VERSION "HNPBNNNYNNNNNNNNNNNNNNNNNNNNNNNNYNYYYYYYYY>4>%%%/4>'%**4YYY///"

NS_ :

BS_:

BU_: RDF2 Air Vehicle_CAN MPC2

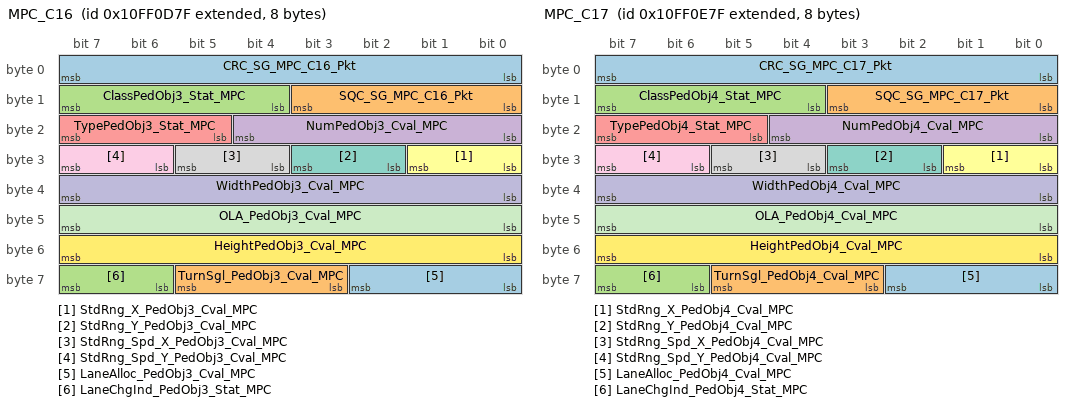
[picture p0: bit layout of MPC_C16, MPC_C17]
BO_ 2432634239 MPC_C16: 8 MPC2
 SG_ CRC_SG_MPC_C16_Pkt : 0|8@1+ (1,0) [0|255] "NoUnit" Vector__XXX
 SG_ SQC_SG_MPC_C16_Pkt : 8|4@1+ (1,0) [0|15] "NoUnit" Vector__XXX
 SG_ ClassPedObj3_Stat_MPC : 12|4@1+ (1,0) [0|15] "" Vector__XXX
 SG_ NumPedObj3_Cval_MPC : 16|5@1+ (1,0) [0|30] "NoUnit" Vector__XXX
 SG_ TypePedObj3_Stat_MPC : 21|3@1+ (1,0) [0|7] "" Vector__XXX
 SG_ StdRng_X_PedObj3_Cval_MPC : 24|2@1+ (1,0) [0|3] "" Vector__XXX
 SG_ StdRng_Y_PedObj3_Cval_MPC : 26|2@1+ (1,0) [0|3] "" Vector__XXX
 SG_ StdRng_Spd_X_PedObj3_Cval_MPC : 28|2@1+ (1,0) [0|3] "" Vector__XXX
 SG_ StdRng_Spd_Y_PedObj3_Cval_MPC : 30|2@1+ (1,0) [0|3] "" Vector__XXX
 SG_ WidthPedObj3_Cval_MPC : 32|8@1+ (0.05,0) [0|12.5] "m" Vector__XXX
 SG_ OLA_PedObj3_Cval_MPC : 40|8@1+ (0.004,-0.5) [-0.5|0.5] "rad" Vector__XXX
 SG_ HeightPedObj3_Cval_MPC : 48|8@1+ (0.05,0) [0|12.5] "m" Vector__XXX
 SG_ LaneAlloc_PedObj3_Cval_MPC : 56|3@1+ (1,0) [0|7] "" Vector__XXX
 SG_ TurnSgl_PedObj3_Cval_MPC : 59|3@1+ (1,0) [0|7] "" Vector__XXX
 SG_ LaneChgInd_PedObj3_Stat_MPC : 62|2@1+ (1,0) [0|3] "" Vector__XXX

BO_ 2432634495 MPC_C17: 8 MPC2
 SG_ CRC_SG_MPC_C17_Pkt : 0|8@1+ (1,0) [0|255] "NoUnit" Vector__XXX
 SG_ SQC_SG_MPC_C17_Pkt : 8|4@1+ (1,0) [0|15] "NoUnit" Vector__XXX
 SG_ ClassPedObj4_Stat_MPC : 12|4@1+ (1,0) [0|15] "" Vector__XXX
 SG_ NumPedObj4_Cval_MPC : 16|5@1+ (1,0) [0|30] "NoUnit" Vector__XXX
 SG_ TypePedObj4_Stat_MPC : 21|3@1+ (1,0) [0|7] "" Vector__XXX
 SG_ StdRng_X_PedObj4_Cval_MPC : 24|2@1+ (1,0) [0|3] "" Vector__XXX
 SG_ StdRng_Y_PedObj4_Cval_MPC : 26|2@1+ (1,0) [0|3] "" Vector__XXX
 SG_ StdRng_Spd_X_PedObj4_Cval_MPC : 28|2@1+ (1,0) [0|3] "" Vector__XXX
 SG_ StdRng_Spd_Y_PedObj4_Cval_MPC : 30|2@1+ (1,0) [0|3] "" Vector__XXX
 SG_ WidthPedObj4_Cval_MPC : 32|8@1+ (0.05,0) [0|12.5] "m" Vector__XXX
 SG_ OLA_PedObj4_Cval_MPC : 40|8@1+ (0.004,-0.5) [-0.5|0.5] "rad" Vector__XXX
 SG_ HeightPedObj4_Cval_MPC : 48|8@1+ (0.05,0) [0|12.5] "m" Vector__XXX
 SG_ LaneAlloc_PedObj4_Cval_MPC : 56|3@1+ (1,0) [0|7] "" Vector__XXX
 SG_ TurnSgl_PedObj4_Cval_MPC : 59|3@1+ (1,0) [0|7] "" Vector__XXX
 SG_ LaneChgInd_PedObj4_Stat_MPC : 62|2@1+ (1,0) [0|3] "" Vector__XXX

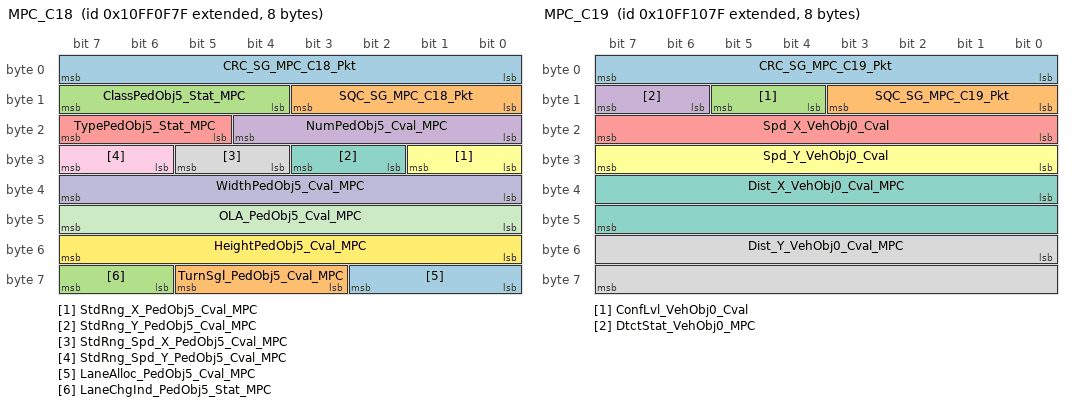
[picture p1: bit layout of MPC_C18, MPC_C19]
BO_ 2432634751 MPC_C18: 8 MPC2
 SG_ CRC_SG_MPC_C18_Pkt : 0|8@1+ (1,0) [0|255] "NoUnit" Vector__XXX
 SG_ SQC_SG_MPC_C18_Pkt : 8|4@1+ (1,0) [0|15] "NoUnit" Vector__XXX
 SG_ ClassPedObj5_Stat_MPC : 12|4@1+ (1,0) [0|15] "" Vector__XXX
 SG_ NumPedObj5_Cval_MPC : 16|5@1+ (1,0) [0|30] "NoUnit" Vector__XXX
 SG_ TypePedObj5_Stat_MPC : 21|3@1+ (1,0) [0|7] "" Vector__XXX
 SG_ StdRng_X_PedObj5_Cval_MPC : 24|2@1+ (1,0) [0|3] "" Vector__XXX
 SG_ StdRng_Y_PedObj5_Cval_MPC : 26|2@1+ (1,0) [0|3] "" Vector__XXX
 SG_ StdRng_Spd_X_PedObj5_Cval_MPC : 28|2@1+ (1,0) [0|3] "" Vector__XXX
 SG_ StdRng_Spd_Y_PedObj5_Cval_MPC : 30|2@1+ (1,0) [0|3] "" Vector__XXX
 SG_ WidthPedObj5_Cval_MPC : 32|8@1+ (0.05,0) [0|12.5] "m" Vector__XXX
 SG_ OLA_PedObj5_Cval_MPC : 40|8@1+ (0.004,-0.5) [-0.5|0.5] "rad" Vector__XXX
 SG_ HeightPedObj5_Cval_MPC : 48|8@1+ (0.05,0) [0|12.5] "m" Vector__XXX
 SG_ LaneAlloc_PedObj5_Cval_MPC : 56|3@1+ (1,0) [0|7] "" Vector__XXX
 SG_ TurnSgl_PedObj5_Cval_MPC : 59|3@1+ (1,0) [0|7] "" Vector__XXX
 SG_ LaneChgInd_PedObj5_Stat_MPC : 62|2@1+ (1,0) [0|3] "" Vector__XXX

BO_ 2432635007 MPC_C19: 8 MPC2
 SG_ CRC_SG_MPC_C19_Pkt : 0|8@1+ (1,0) [0|255] "NoUnit" Vector__XXX
 SG_ SQC_SG_MPC_C19_Pkt : 8|4@1+ (1,0) [0|15] "NoUnit" Vector__XXX
 SG_ ConfLvl_VehObj0_Cval : 12|2@1+ (1,0) [0|3] "" Vector__XXX
 SG_ DtctStat_VehObj0_MPC : 14|2@1+ (1,0) [0|3] "" Vector__XXX
 SG_ Spd_X_VehObj0_Cval : 16|8@1+ (1,-200) [-200|50] "km/h" Vector__XXX
 SG_ Spd_Y_VehObj0_Cval : 24|8@1+ (0.1,-12.5) [-12.5|12.5] "m/s" Vector__XXX
 SG_ Dist_X_VehObj0_Cval_MPC : 32|16@1+ (0.0078125,-250.99609375) [-250.99609375|250.99609375] "m" Vector__XXX
 SG_ Dist_Y_VehObj0_Cval_MPC : 48|16@1+ (0.0078125,-250.99609375) [-250.99609375|250.99609375] "m" Vector__XXX

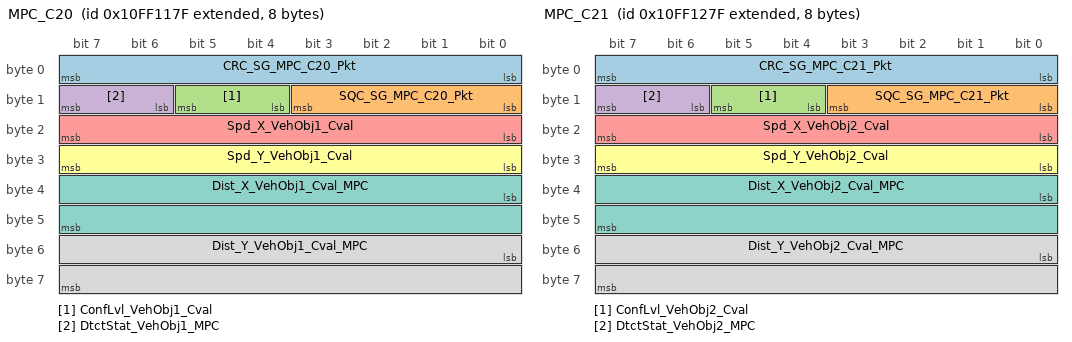
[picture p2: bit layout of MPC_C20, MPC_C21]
BO_ 2432635263 MPC_C20: 8 MPC2
 SG_ CRC_SG_MPC_C20_Pkt : 0|8@1+ (1,0) [0|255] "NoUnit" Vector__XXX
 SG_ SQC_SG_MPC_C20_Pkt : 8|4@1+ (1,0) [0|15] "NoUnit" Vector__XXX
 SG_ ConfLvl_VehObj1_Cval : 12|2@1+ (1,0) [0|3] "" Vector__XXX
 SG_ DtctStat_VehObj1_MPC : 14|2@1+ (1,0) [0|3] "" Vector__XXX
 SG_ Spd_X_VehObj1_Cval : 16|8@1+ (1,-200) [-200|50] "km/h" Vector__XXX
 SG_ Spd_Y_VehObj1_Cval : 24|8@1+ (0.1,-12.5) [-12.5|12.5] "m/s" Vector__XXX
 SG_ Dist_X_VehObj1_Cval_MPC : 32|16@1+ (0.0078125,-250.99609375) [-250.99609375|250.99609375] "m" Vector__XXX
 SG_ Dist_Y_VehObj1_Cval_MPC : 48|16@1+ (0.0078125,-250.99609375) [-250.99609375|250.99609375] "m" Vector__XXX

BO_ 2432635519 MPC_C21: 8 MPC2
 SG_ CRC_SG_MPC_C21_Pkt : 0|8@1+ (1,0) [0|255] "NoUnit" Vector__XXX
 SG_ SQC_SG_MPC_C21_Pkt : 8|4@1+ (1,0) [0|15] "NoUnit" Vector__XXX
 SG_ ConfLvl_VehObj2_Cval : 12|2@1+ (1,0) [0|3] "" Vector__XXX
 SG_ DtctStat_VehObj2_MPC : 14|2@1+ (1,0) [0|3] "" Vector__XXX
 SG_ Spd_X_VehObj2_Cval : 16|8@1+ (1,-200) [-200|50] "km/h" Vector__XXX
 SG_ Spd_Y_VehObj2_Cval : 24|8@1+ (0.1,-12.5) [-12.5|12.5] "m/s" Vector__XXX
 SG_ Dist_X_VehObj2_Cval_MPC : 32|16@1+ (0.0078125,-250.99609375) [-250.99609375|250.99609375] "m" Vector__XXX
 SG_ Dist_Y_VehObj2_Cval_MPC : 48|16@1+ (0.0078125,-250.99609375) [-250.99609375|250.99609375] "m" Vector__XXX

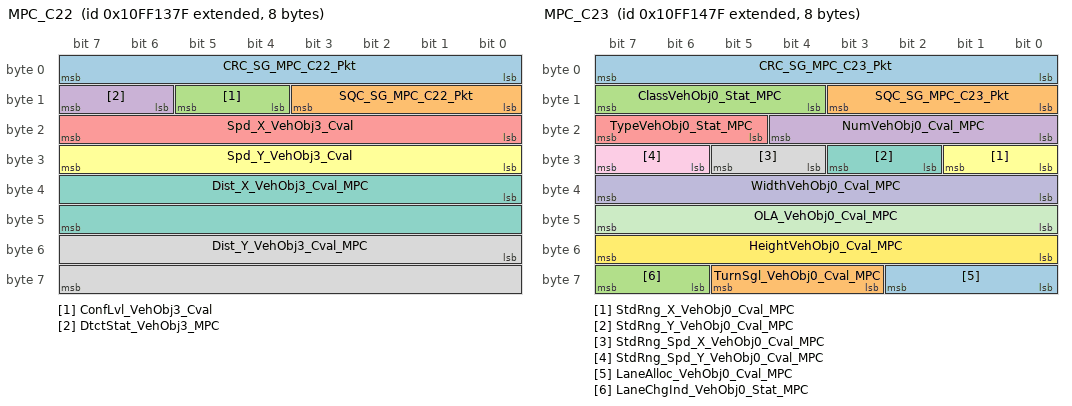
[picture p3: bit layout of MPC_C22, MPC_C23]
BO_ 2432635775 MPC_C22: 8 MPC2
 SG_ CRC_SG_MPC_C22_Pkt : 0|8@1+ (1,0) [0|255] "NoUnit" Vector__XXX
 SG_ SQC_SG_MPC_C22_Pkt : 8|4@1+ (1,0) [0|15] "NoUnit" Vector__XXX
 SG_ ConfLvl_VehObj3_Cval : 12|2@1+ (1,0) [0|3] "" Vector__XXX
 SG_ DtctStat_VehObj3_MPC : 14|2@1+ (1,0) [0|3] "" Vector__XXX
 SG_ Spd_X_VehObj3_Cval : 16|8@1+ (1,-200) [-200|50] "km/h" Vector__XXX
 SG_ Spd_Y_VehObj3_Cval : 24|8@1+ (0.1,-12.5) [-12.5|12.5] "m/s" Vector__XXX
 SG_ Dist_X_VehObj3_Cval_MPC : 32|16@1+ (0.0078125,-250.99609375) [-250.99609375|250.99609375] "m" Vector__XXX
 SG_ Dist_Y_VehObj3_Cval_MPC : 48|16@1+ (0.0078125,-250.99609375) [-250.99609375|250.99609375] "m" Vector__XXX

BO_ 2432636031 MPC_C23: 8 MPC2
 SG_ CRC_SG_MPC_C23_Pkt : 0|8@1+ (1,0) [0|255] "NoUnit" Vector__XXX
 SG_ SQC_SG_MPC_C23_Pkt : 8|4@1+ (1,0) [0|15] "NoUnit" Vector__XXX
 SG_ ClassVehObj0_Stat_MPC : 12|4@1+ (1,0) [0|15] "" Vector__XXX
 SG_ NumVehObj0_Cval_MPC : 16|5@1+ (1,0) [0|30] "NoUnit" Vector__XXX
 SG_ TypeVehObj0_Stat_MPC : 21|3@1+ (1,0) [0|7] "" Vector__XXX
 SG_ StdRng_X_VehObj0_Cval_MPC : 24|2@1+ (1,0) [0|3] "" Vector__XXX
 SG_ StdRng_Y_VehObj0_Cval_MPC : 26|2@1+ (1,0) [0|3] "" Vector__XXX
 SG_ StdRng_Spd_X_VehObj0_Cval_MPC : 28|2@1+ (1,0) [0|3] "" Vector__XXX
 SG_ StdRng_Spd_Y_VehObj0_Cval_MPC : 30|2@1+ (1,0) [0|3] "" Vector__XXX
 SG_ WidthVehObj0_Cval_MPC : 32|8@1+ (0.05,0) [0|12.5] "m" Vector__XXX
 SG_ OLA_VehObj0_Cval_MPC : 40|8@1+ (0.004,-0.5) [-0.5|0.5] "rad" Vector__XXX
 SG_ HeightVehObj0_Cval_MPC : 48|8@1+ (0.05,0) [0|12.5] "m" Vector__XXX
 SG_ LaneAlloc_VehObj0_Cval_MPC : 56|3@1+ (1,0) [0|7] "" Vector__XXX
 SG_ TurnSgl_VehObj0_Cval_MPC : 59|3@1+ (1,0) [0|7] "" Vector__XXX
 SG_ LaneChgInd_VehObj0_Stat_MPC : 62|2@1+ (1,0) [0|3] "" Vector__XXX

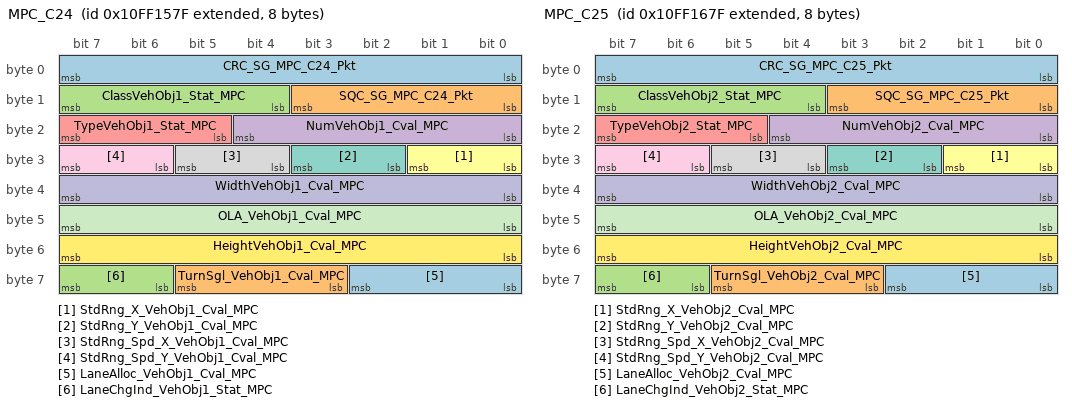
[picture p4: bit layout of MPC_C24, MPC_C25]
BO_ 2432636287 MPC_C24: 8 MPC2
 SG_ CRC_SG_MPC_C24_Pkt : 0|8@1+ (1,0) [0|255] "NoUnit" Vector__XXX
 SG_ SQC_SG_MPC_C24_Pkt : 8|4@1+ (1,0) [0|15] "NoUnit" Vector__XXX
 SG_ ClassVehObj1_Stat_MPC : 12|4@1+ (1,0) [0|15] "" Vector__XXX
 SG_ NumVehObj1_Cval_MPC : 16|5@1+ (1,0) [0|30] "NoUnit" Vector__XXX
 SG_ TypeVehObj1_Stat_MPC : 21|3@1+ (1,0) [0|7] "" Vector__XXX
 SG_ StdRng_X_VehObj1_Cval_MPC : 24|2@1+ (1,0) [0|3] "" Vector__XXX
 SG_ StdRng_Y_VehObj1_Cval_MPC : 26|2@1+ (1,0) [0|3] "" Vector__XXX
 SG_ StdRng_Spd_X_VehObj1_Cval_MPC : 28|2@1+ (1,0) [0|3] "" Vector__XXX
 SG_ StdRng_Spd_Y_VehObj1_Cval_MPC : 30|2@1+ (1,0) [0|3] "" Vector__XXX
 SG_ WidthVehObj1_Cval_MPC : 32|8@1+ (0.05,0) [0|12.5] "m" Vector__XXX
 SG_ OLA_VehObj1_Cval_MPC : 40|8@1+ (0.004,-0.5) [-0.5|0.5] "rad" Vector__XXX
 SG_ HeightVehObj1_Cval_MPC : 48|8@1+ (0.05,0) [0|12.5] "m" Vector__XXX
 SG_ LaneAlloc_VehObj1_Cval_MPC : 56|3@1+ (1,0) [0|7] "" Vector__XXX
 SG_ TurnSgl_VehObj1_Cval_MPC : 59|3@1+ (1,0) [0|7] "" Vector__XXX
 SG_ LaneChgInd_VehObj1_Stat_MPC : 62|2@1+ (1,0) [0|3] "" Vector__XXX

BO_ 2432636543 MPC_C25: 8 MPC2
 SG_ CRC_SG_MPC_C25_Pkt : 0|8@1+ (1,0) [0|255] "NoUnit" Vector__XXX
 SG_ SQC_SG_MPC_C25_Pkt : 8|4@1+ (1,0) [0|15] "NoUnit" Vector__XXX
 SG_ ClassVehObj2_Stat_MPC : 12|4@1+ (1,0) [0|15] "" Vector__XXX
 SG_ NumVehObj2_Cval_MPC : 16|5@1+ (1,0) [0|30] "NoUnit" Vector__XXX
 SG_ TypeVehObj2_Stat_MPC : 21|3@1+ (1,0) [0|7] "" Vector__XXX
 SG_ StdRng_X_VehObj2_Cval_MPC : 24|2@1+ (1,0) [0|3] "" Vector__XXX
 SG_ StdRng_Y_VehObj2_Cval_MPC : 26|2@1+ (1,0) [0|3] "" Vector__XXX
 SG_ StdRng_Spd_X_VehObj2_Cval_MPC : 28|2@1+ (1,0) [0|3] "" Vector__XXX
 SG_ StdRng_Spd_Y_VehObj2_Cval_MPC : 30|2@1+ (1,0) [0|3] "" Vector__XXX
 SG_ WidthVehObj2_Cval_MPC : 32|8@1+ (0.05,0) [0|12.5] "m" Vector__XXX
 SG_ OLA_VehObj2_Cval_MPC : 40|8@1+ (0.004,-0.5) [-0.5|0.5] "rad" Vector__XXX
 SG_ HeightVehObj2_Cval_MPC : 48|8@1+ (0.05,0) [0|12.5] "m" Vector__XXX
 SG_ LaneAlloc_VehObj2_Cval_MPC : 56|3@1+ (1,0) [0|7] "" Vector__XXX
 SG_ TurnSgl_VehObj2_Cval_MPC : 59|3@1+ (1,0) [0|7] "" Vector__XXX
 SG_ LaneChgInd_VehObj2_Stat_MPC : 62|2@1+ (1,0) [0|3] "" Vector__XXX

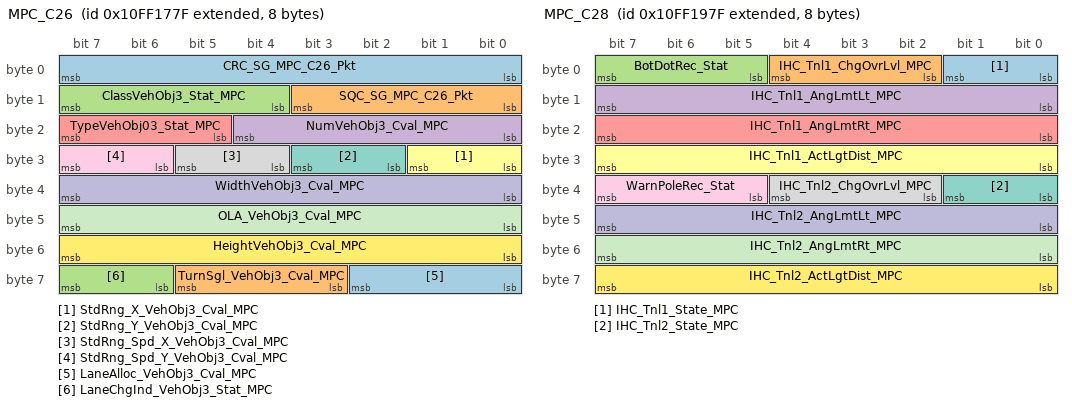
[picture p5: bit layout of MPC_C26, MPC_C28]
BO_ 2432636799 MPC_C26: 8 MPC2
 SG_ CRC_SG_MPC_C26_Pkt : 0|8@1+ (1,0) [0|255] "NoUnit" Vector__XXX
 SG_ SQC_SG_MPC_C26_Pkt : 8|4@1+ (1,0) [0|15] "NoUnit" Vector__XXX
 SG_ ClassVehObj3_Stat_MPC : 12|4@1+ (1,0) [0|15] "" Vector__XXX
 SG_ NumVehObj3_Cval_MPC : 16|5@1+ (1,0) [0|30] "NoUnit" Vector__XXX
 SG_ TypeVehObj03_Stat_MPC : 21|3@1+ (1,0) [0|7] "" Vector__XXX
 SG_ StdRng_X_VehObj3_Cval_MPC : 24|2@1+ (1,0) [0|3] "" Vector__XXX
 SG_ StdRng_Y_VehObj3_Cval_MPC : 26|2@1+ (1,0) [0|3] "" Vector__XXX
 SG_ StdRng_Spd_X_VehObj3_Cval_MPC : 28|2@1+ (1,0) [0|3] "" Vector__XXX
 SG_ StdRng_Spd_Y_VehObj3_Cval_MPC : 30|2@1+ (1,0) [0|3] "" Vector__XXX
 SG_ WidthVehObj3_Cval_MPC : 32|8@1+ (0.05,0) [0|12.5] "m" Vector__XXX
 SG_ OLA_VehObj3_Cval_MPC : 40|8@1+ (0.004,-0.5) [-0.5|0.5] "rad" Vector__XXX
 SG_ HeightVehObj3_Cval_MPC : 48|8@1+ (0.05,0) [0|12.5] "m" Vector__XXX
 SG_ LaneAlloc_VehObj3_Cval_MPC : 56|3@1+ (1,0) [0|7] "" Vector__XXX
 SG_ TurnSgl_VehObj3_Cval_MPC : 59|3@1+ (1,0) [0|7] "" Vector__XXX
 SG_ LaneChgInd_VehObj3_Stat_MPC : 62|2@1+ (1,0) [0|3] "" Vector__XXX

BO_ 2432637311 MPC_C28: 8 MPC2
 SG_ IHC_Tnl1_State_MPC : 0|2@1+ (1,0) [0|3] "" Vector__XXX
 SG_ IHC_Tnl1_ChgOvrLvl_MPC : 2|3@1+ (1,0) [0|6] "NoUnit" Vector__XXX
 SG_ BotDotRec_Stat : 5|3@1+ (1,0) [0|7] "" Vector__XXX
 SG_ IHC_Tnl1_AngLmtLt_MPC : 8|8@1+ (0.25,-31.25) [-31.25|31.25] "°" Vector__XXX
 SG_ IHC_Tnl1_AngLmtRt_MPC : 16|8@1+ (0.25,-31.25) [-31.25|31.25] "°" Vector__XXX
 SG_ IHC_Tnl1_ActLgtDist_MPC : 24|8@1+ (2.5,0) [0|625] "m" Vector__XXX
 SG_ IHC_Tnl2_State_MPC : 32|2@1+ (1,0) [0|3] "" Vector__XXX
 SG_ IHC_Tnl2_ChgOvrLvl_MPC : 34|3@1+ (1,0) [0|6] "NoUnit" Vector__XXX
 SG_ WarnPoleRec_Stat : 37|3@1+ (1,0) [0|7] "" Vector__XXX
 SG_ IHC_Tnl2_AngLmtLt_MPC : 40|8@1+ (0.25,-31.25) [-31.25|31.25] "°" Vector__XXX
 SG_ IHC_Tnl2_AngLmtRt_MPC : 48|8@1+ (0.25,-31.25) [-31.25|31.25] "°" Vector__XXX
 SG_ IHC_Tnl2_ActLgtDist_MPC : 56|8@1+ (2.5,0) [0|625] "m" Vector__XXX

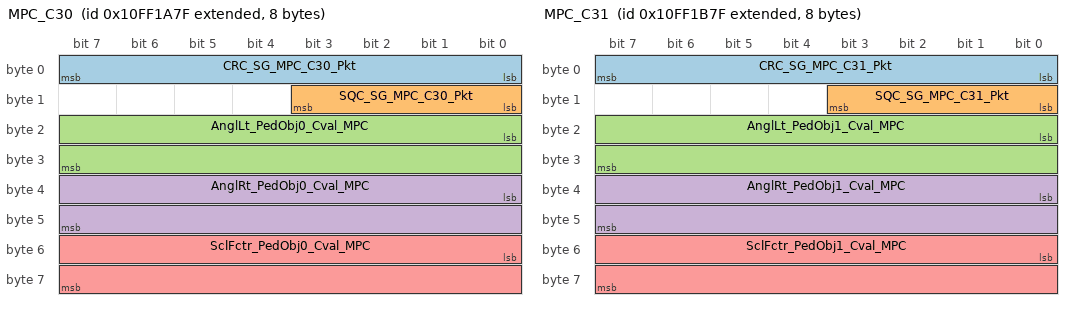
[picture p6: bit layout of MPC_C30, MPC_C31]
BO_ 2432637567 MPC_C30: 8 MPC2
 SG_ CRC_SG_MPC_C30_Pkt : 0|8@1+ (1,0) [0|255] "NoUnit" Vector__XXX
 SG_ SQC_SG_MPC_C30_Pkt : 8|4@1+ (1,0) [0|15] "NoUnit" Vector__XXX
 SG_ AnglLt_PedObj0_Cval_MPC : 16|16@1+ (0.00390625,-125) [-125|125] "°" Vector__XXX
 SG_ AnglRt_PedObj0_Cval_MPC : 32|16@1+ (0.00390625,-125) [-125|125] "°" Vector__XXX
 SG_ SclFctr_PedObj0_Cval_MPC : 48|16@1+ (6.25E-005,0.5) [0.5|4.5] "NoUnit" Vector__XXX

BO_ 2432637823 MPC_C31: 8 MPC2
 SG_ CRC_SG_MPC_C31_Pkt : 0|8@1+ (1,0) [0|255] "NoUnit" Vector__XXX
 SG_ SQC_SG_MPC_C31_Pkt : 8|4@1+ (1,0) [0|15] "NoUnit" Vector__XXX
 SG_ AnglLt_PedObj1_Cval_MPC : 16|16@1+ (0.00390625,-125) [-125|125] "°" Vector__XXX
 SG_ AnglRt_PedObj1_Cval_MPC : 32|16@1+ (0.00390625,-125) [-125|125] "°" Vector__XXX
 SG_ SclFctr_PedObj1_Cval_MPC : 48|16@1+ (6.25E-005,0.5) [0.5|4.5] "NoUnit" Vector__XXX

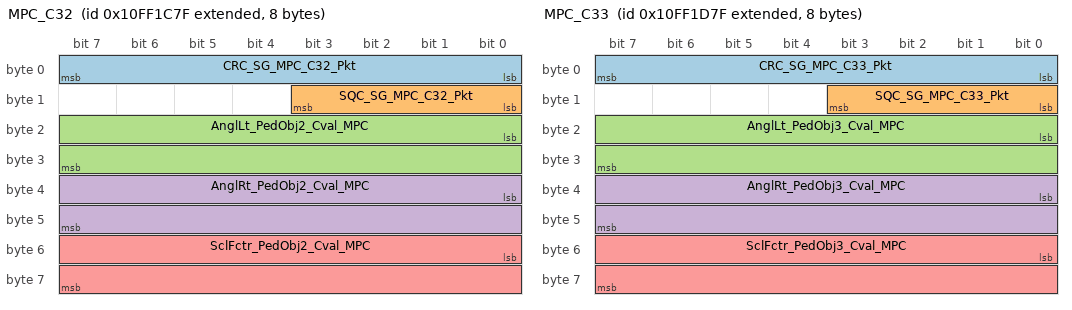
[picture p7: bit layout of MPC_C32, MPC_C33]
BO_ 2432638079 MPC_C32: 8 MPC2
 SG_ CRC_SG_MPC_C32_Pkt : 0|8@1+ (1,0) [0|255] "NoUnit" Vector__XXX
 SG_ SQC_SG_MPC_C32_Pkt : 8|4@1+ (1,0) [0|15] "NoUnit" Vector__XXX
 SG_ AnglLt_PedObj2_Cval_MPC : 16|16@1+ (0.00390625,-125) [-125|125] "°" Vector__XXX
 SG_ AnglRt_PedObj2_Cval_MPC : 32|16@1+ (0.00390625,-125) [-125|125] "°" Vector__XXX
 SG_ SclFctr_PedObj2_Cval_MPC : 48|16@1+ (6.25E-005,0.5) [0.5|4.5] "NoUnit" Vector__XXX

BO_ 2432638335 MPC_C33: 8 MPC2
 SG_ CRC_SG_MPC_C33_Pkt : 0|8@1+ (1,0) [0|255] "NoUnit" Vector__XXX
 SG_ SQC_SG_MPC_C33_Pkt : 8|4@1+ (1,0) [0|15] "NoUnit" Vector__XXX
 SG_ AnglLt_PedObj3_Cval_MPC : 16|16@1+ (0.00390625,-125) [-125|125] "°" Vector__XXX
 SG_ AnglRt_PedObj3_Cval_MPC : 32|16@1+ (0.00390625,-125) [-125|125] "°" Vector__XXX
 SG_ SclFctr_PedObj3_Cval_MPC : 48|16@1+ (6.25E-005,0.5) [0.5|4.5] "NoUnit" Vector__XXX

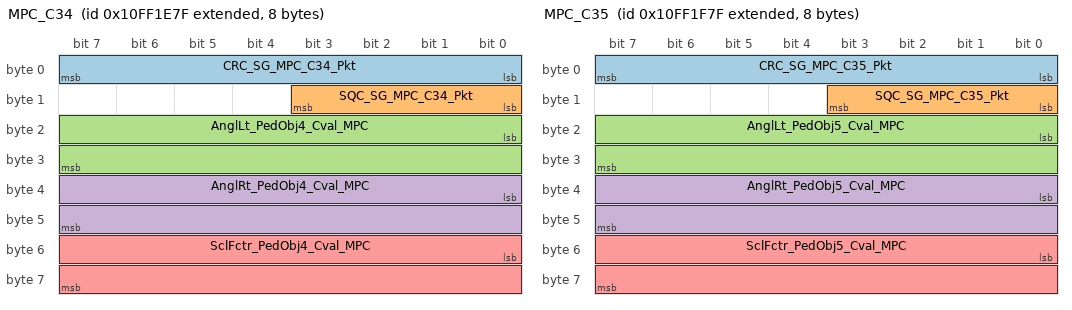
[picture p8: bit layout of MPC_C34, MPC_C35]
BO_ 2432638591 MPC_C34: 8 MPC2
 SG_ CRC_SG_MPC_C34_Pkt : 0|8@1+ (1,0) [0|255] "NoUnit" Vector__XXX
 SG_ SQC_SG_MPC_C34_Pkt : 8|4@1+ (1,0) [0|15] "NoUnit" Vector__XXX
 SG_ AnglLt_PedObj4_Cval_MPC : 16|16@1+ (0.00390625,-125) [-125|125] "°" Vector__XXX
 SG_ AnglRt_PedObj4_Cval_MPC : 32|16@1+ (0.00390625,-125) [-125|125] "°" Vector__XXX
 SG_ SclFctr_PedObj4_Cval_MPC : 48|16@1+ (6.25E-005,0.5) [0.5|4.5] "NoUnit" Vector__XXX

BO_ 2432638847 MPC_C35: 8 MPC2
 SG_ CRC_SG_MPC_C35_Pkt : 0|8@1+ (1,0) [0|255] "NoUnit" Vector__XXX
 SG_ SQC_SG_MPC_C35_Pkt : 8|4@1+ (1,0) [0|15] "NoUnit" Vector__XXX
 SG_ AnglLt_PedObj5_Cval_MPC : 16|16@1+ (0.00390625,-125) [-125|125] "°" Vector__XXX
 SG_ AnglRt_PedObj5_Cval_MPC : 32|16@1+ (0.00390625,-125) [-125|125] "°" Vector__XXX
 SG_ SclFctr_PedObj5_Cval_MPC : 48|16@1+ (6.25E-005,0.5) [0.5|4.5] "NoUnit" Vector__XXX

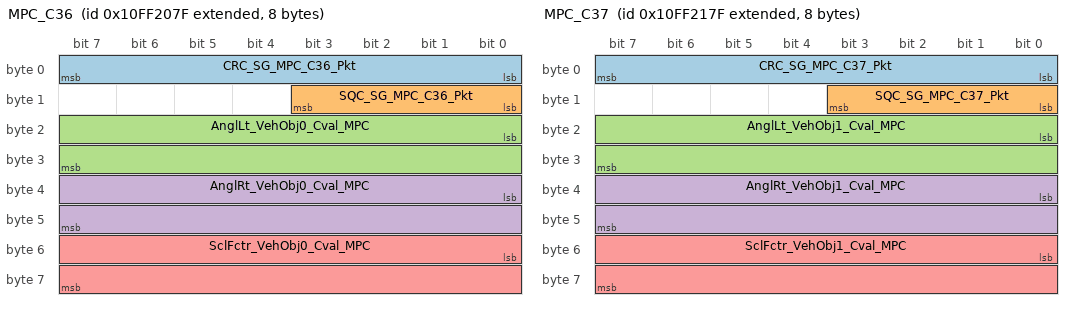
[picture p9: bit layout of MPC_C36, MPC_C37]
BO_ 2432639103 MPC_C36: 8 MPC2
 SG_ CRC_SG_MPC_C36_Pkt : 0|8@1+ (1,0) [0|255] "NoUnit" Vector__XXX
 SG_ SQC_SG_MPC_C36_Pkt : 8|4@1+ (1,0) [0|15] "NoUnit" Vector__XXX
 SG_ AnglLt_VehObj0_Cval_MPC : 16|16@1+ (0.00390625,-125) [-125|125] "°" Vector__XXX
 SG_ AnglRt_VehObj0_Cval_MPC : 32|16@1+ (0.00390625,-125) [-125|125] "°" Vector__XXX
 SG_ SclFctr_VehObj0_Cval_MPC : 48|16@1+ (6.25E-005,0.5) [0.5|4.5] "NoUnit" Vector__XXX

BO_ 2432639359 MPC_C37: 8 MPC2
 SG_ CRC_SG_MPC_C37_Pkt : 0|8@1+ (1,0) [0|255] "NoUnit" Vector__XXX
 SG_ SQC_SG_MPC_C37_Pkt : 8|4@1+ (1,0) [0|15] "NoUnit" Vector__XXX
 SG_ AnglLt_VehObj1_Cval_MPC : 16|16@1+ (0.00390625,-125) [-125|125] "°" Vector__XXX
 SG_ AnglRt_VehObj1_Cval_MPC : 32|16@1+ (0.00390625,-125) [-125|125] "°" Vector__XXX
 SG_ SclFctr_VehObj1_Cval_MPC : 48|16@1+ (6.25E-005,0.5) [0.5|4.5] "NoUnit" Vector__XXX

CM_ SG_ 2432634239 CRC_SG_MPC_C16_Pkt "Checksum C16 Current value MPC {54,37,1A,F8,DB,BE,A1,84,67,4A,2D,10,EE,D1,B4,97}";
CM_ SG_ 2432634239 SQC_SG_MPC_C16_Pkt "Message Counter C16 Current Value MPC";
CM_ SG_ 2432634239 ClassPedObj3_Stat_MPC "classification of pedestrian object 3 Current state (MPC)";
CM_ SG_ 2432634239 NumPedObj3_Cval_MPC "object number of pedestrian object 3 Current value (MPC)";
CM_ SG_ 2432634239 TypePedObj3_Stat_MPC "Object type of pedestrian object 3 Current state (MPC)";
CM_ SG_ 2432634239 StdRng_X_PedObj3_Cval_MPC "Longitudinal (x) standard deviation range gate of pedestrian object 3 Current Value (MPC)";
CM_ SG_ 2432634239 StdRng_Y_PedObj3_Cval_MPC "Lateral (y) standard deviation range gate of pedestrian object 3 Current Value (MPC)";
CM_ SG_ 2432634239 StdRng_Spd_X_PedObj3_Cval_MPC "Longitudinal speed standard deviation range gate of pedestrian object 3 Current Value (MPC)";
CM_ SG_ 2432634239 StdRng_Spd_Y_PedObj3_Cval_MPC "Lateral speed standard deviation range gate of pedestrian object 3 Current Value (MPC)";
CM_ SG_ 2432634239 WidthPedObj3_Cval_MPC "Width of the pedestrian object 3 Current value (MPC)";
CM_ SG_ 2432634239 OLA_PedObj3_Cval_MPC "OLA Pedestrian Object 3 Current value MPC";
CM_ SG_ 2432634239 HeightPedObj3_Cval_MPC "Height over grorund of the pedestrian object 3 Current value (MPC)";
CM_ SG_ 2432634239 LaneAlloc_PedObj3_Cval_MPC "Lane Allocation Pedestrian Object 3 Current value MPC";
CM_ SG_ 2432634239 TurnSgl_PedObj3_Cval_MPC "Turn Signal Pedestrian Object 3 Current value MPC";
CM_ SG_ 2432634239 LaneChgInd_PedObj3_Stat_MPC "Lane Change Indication Pedestrian Object 3 Current state MPC";
CM_ SG_ 2432634495 CRC_SG_MPC_C17_Pkt "Checksum C17 Current value MPC {30,EA,A9,68,27,E1,A0,5F,1E,D8,97,56,15,CF,8E,4D}";
CM_ SG_ 2432634495 SQC_SG_MPC_C17_Pkt "Message Counter C17 Current Value MPC";
CM_ SG_ 2432634495 ClassPedObj4_Stat_MPC "classification of pedestrian object 4 Current state (MPC)";
CM_ SG_ 2432634495 NumPedObj4_Cval_MPC "object number of pedestrian object 4 Current value (MPC)";
CM_ SG_ 2432634495 TypePedObj4_Stat_MPC "Object type of pedestrian object 4 Current state (MPC)";
CM_ SG_ 2432634495 StdRng_X_PedObj4_Cval_MPC "Longitudinal (x) standard deviation range gate of pedestrian object 4 Current Value (MPC)";
CM_ SG_ 2432634495 StdRng_Y_PedObj4_Cval_MPC "Lateral (y) standard deviation range gate of pedestrian object 4 Current Value (MPC)";
CM_ SG_ 2432634495 StdRng_Spd_X_PedObj4_Cval_MPC "Longitudinal speed standard deviation range gate of pedestrian object 4 Current Value (MPC)";
CM_ SG_ 2432634495 StdRng_Spd_Y_PedObj4_Cval_MPC "Lateral speed standard deviation range gate of pedestrian object 4 Current Value (MPC)";
CM_ SG_ 2432634495 WidthPedObj4_Cval_MPC "Width of the pedestrian object 4 Current value (MPC)";
CM_ SG_ 2432634495 OLA_PedObj4_Cval_MPC "OLA Pedestrian Object 4 Current value MPC";
CM_ SG_ 2432634495 HeightPedObj4_Cval_MPC "Height over grorund of the pedestrian object 4 Current value (MPC)";
CM_ SG_ 2432634495 LaneAlloc_PedObj4_Cval_MPC "Lane Allocation Pedestrian Object 4 Current value MPC";
CM_ SG_ 2432634495 TurnSgl_PedObj4_Cval_MPC "Turn Signal Pedestrian Object 4 Current value MPC";
CM_ SG_ 2432634495 LaneChgInd_PedObj4_Stat_MPC "Lane Change Indication Pedestrian Object 4 Current state MPC";
CM_ SG_ 2432634751 CRC_SG_MPC_C18_Pkt "Checksum C18 Current value MPC {30,7D,CA,1C,69,B6,08,55,A2,EF,41,8E,DB,2D,7A,C7}";
CM_ SG_ 2432634751 SQC_SG_MPC_C18_Pkt "Checksum C18 Current value MPC";
CM_ SG_ 2432634751 ClassPedObj5_Stat_MPC "classification of pedestrian object 5 Current state (MPC)";
CM_ SG_ 2432634751 NumPedObj5_Cval_MPC "object number of pedestrian object 5 Current value (MPC)";
CM_ SG_ 2432634751 TypePedObj5_Stat_MPC "Object type of pedestrian object 5 Current state (MPC)";
CM_ SG_ 2432634751 StdRng_X_PedObj5_Cval_MPC "Longitudinal (x) standard deviation range gate of pedestrian object 5 Current Value (MPC)";
CM_ SG_ 2432634751 StdRng_Y_PedObj5_Cval_MPC "Lateral (y) standard deviation range gate of pedestrian object 5 Current Value (MPC)";
CM_ SG_ 2432634751 StdRng_Spd_X_PedObj5_Cval_MPC "Longitudinal speed standard deviation range gate of pedestrian object 5 Current Value (MPC)";
CM_ SG_ 2432634751 StdRng_Spd_Y_PedObj5_Cval_MPC "Lateral speed standard deviation range gate of pedestrian object 5 Current Value (MPC)";
CM_ SG_ 2432634751 WidthPedObj5_Cval_MPC "Width of the pedestrian object 5 Current value (MPC)";
CM_ SG_ 2432634751 OLA_PedObj5_Cval_MPC "OLA Pedestrian Object 5 Current value MPC";
CM_ SG_ 2432634751 HeightPedObj5_Cval_MPC "Height over grorund of the pedestrian object 5 Current value (MPC)";
CM_ SG_ 2432634751 LaneAlloc_PedObj5_Cval_MPC "Lane Allocation Pedestrian Object 5 Current value MPC";
CM_ SG_ 2432634751 TurnSgl_PedObj5_Cval_MPC "Turn Signal Pedestrian Object 5 Current value MPC";
CM_ SG_ 2432634751 LaneChgInd_PedObj5_Stat_MPC "Lane Change Indication Pedestrian Object 5 Current state MPC";
CM_ SG_ 2432635007 CRC_SG_MPC_C19_Pkt "Checksum C19 Current value MPC {ED,F9,0A,16,22,2E,3A,46,52,5E,6A,76,82,8E,9A,A6}";
CM_ SG_ 2432635007 SQC_SG_MPC_C19_Pkt "Checksum C19 Current value MPC";
CM_ SG_ 2432635007 ConfLvl_VehObj0_Cval "Confidence Level of vehicle object 0 Current value (MPC)";
CM_ SG_ 2432635007 DtctStat_VehObj0_MPC "Detection State of vehicle object 0 Current Value (MPC)";
CM_ SG_ 2432635007 Spd_X_VehObj0_Cval "Relative speed longitudinal (vx) of vehicle object 0 Current value (MPC)";
CM_ SG_ 2432635007 Spd_Y_VehObj0_Cval "Relative speed lateral (vy) of vehicle object 0 Current value (MPC)";
CM_ SG_ 2432635007 Dist_X_VehObj0_Cval_MPC "Distance longitudinal (x) of vehicle object 0 Current value (MPC)";
CM_ SG_ 2432635007 Dist_Y_VehObj0_Cval_MPC "Distance lateral (y) of vehicle object 0 Current value (MPC)";
CM_ SG_ 2432635263 CRC_SG_MPC_C20_Pkt "Checksum C20 Current value MPC {67,72,7D,88,93,9E,A9,B4,BF,CA,D5,E0,EB,F6,06,11}";
CM_ SG_ 2432635263 SQC_SG_MPC_C20_Pkt "Checksum C20 Current value MPC";
CM_ SG_ 2432635263 ConfLvl_VehObj1_Cval "Confidence Level of vehicle object 1 Current value (MPC)";
CM_ SG_ 2432635263 DtctStat_VehObj1_MPC "Detection State of vehicle object 1 Current Value (MPC)";
CM_ SG_ 2432635263 Spd_X_VehObj1_Cval "Relative speed longitudinal (vx) of vehicle object 1 Current value (MPC)";
CM_ SG_ 2432635263 Spd_Y_VehObj1_Cval "Relative speed lateral (vy) of vehicle object 1 Current value (MPC)";
CM_ SG_ 2432635263 Dist_X_VehObj1_Cval_MPC "Distance longitudinal (x) of vehicle object 1 Current value (MPC)";
CM_ SG_ 2432635263 Dist_Y_VehObj1_Cval_MPC "Distance lateral (y) of vehicle object 1 Current value (MPC)";
CM_ SG_ 2432635519 CRC_SG_MPC_C21_Pkt "Checksum C21 Current value MPC {9C,56,10,C5,7F,39,EE,A8,62,1C,D1,8B,45,FA,B4,6E}";
CM_ SG_ 2432635519 SQC_SG_MPC_C21_Pkt "Checksum C21 Current value MPC";
CM_ SG_ 2432635519 ConfLvl_VehObj2_Cval "Confidence Level of vehicle object 2 Current value (MPC)";
CM_ SG_ 2432635519 DtctStat_VehObj2_MPC "Detection State of vehicle object 2 Current Value (MPC)";
CM_ SG_ 2432635519 Spd_X_VehObj2_Cval "Relative speed longitudinal (vx) of vehicle object 2 Current value (MPC)";
CM_ SG_ 2432635519 Spd_Y_VehObj2_Cval "Relative speed lateral (vy) of vehicle object 2 Current value (MPC)";
CM_ SG_ 2432635519 Dist_X_VehObj2_Cval_MPC "Distance longitudinal (x) of vehicle object 2 Current value (MPC)";
CM_ SG_ 2432635519 Dist_Y_VehObj2_Cval_MPC "Distance lateral (y) of vehicle object 2 Current value (MPC)";
CM_ SG_ 2432635775 CRC_SG_MPC_C22_Pkt "Checksum C22 Current value MPC {62,A0,DE,21,5F,9D,DB,1E,5C,9A,D8,1B,59,97,D5,18}";
CM_ SG_ 2432635775 SQC_SG_MPC_C22_Pkt "Checksum C22 Current value MPC";
CM_ SG_ 2432635775 ConfLvl_VehObj3_Cval "Confidence Level of vehicle object 3 Current value (MPC)";
CM_ SG_ 2432635775 DtctStat_VehObj3_MPC "Detection State of vehicle object 3 Current Value (MPC)";
CM_ SG_ 2432635775 Spd_X_VehObj3_Cval "Relative speed longitudinal (vx) of vehicle object 3 Current value (MPC)";
CM_ SG_ 2432635775 Spd_Y_VehObj3_Cval "Relative speed lateral (vy) of vehicle object 3 Current value (MPC)";
CM_ SG_ 2432635775 Dist_X_VehObj3_Cval_MPC "Distance longitudinal (x) of vehicle object 3 Current value (MPC)";
CM_ SG_ 2432635775 Dist_Y_VehObj3_Cval_MPC "Distance lateral (y) of vehicle object 3 Current value (MPC)";
CM_ SG_ 2432636031 CRC_SG_MPC_C23_Pkt "Checksum C23 Current value MPC {84,30,D7,83,2F,D6,82,2E,D5,81,2D,D4,80,2C,D3,7F}";
CM_ SG_ 2432636031 SQC_SG_MPC_C23_Pkt "Message Counter C23 Current Value MPC";
CM_ SG_ 2432636031 ClassVehObj0_Stat_MPC "classification of vehicle object 0 Current state (MPC)";
CM_ SG_ 2432636031 NumVehObj0_Cval_MPC "object number of vehicle object 0 (MPC)";
CM_ SG_ 2432636031 TypeVehObj0_Stat_MPC "Object type of vehicle object 0 (MPC)";
CM_ SG_ 2432636031 StdRng_X_VehObj0_Cval_MPC "Longitudinal (x) standard deviation range gate of vehicle object 0 Current Value (MPC)";
CM_ SG_ 2432636031 StdRng_Y_VehObj0_Cval_MPC "Lateral (y) standard deviation range gate of vehicle object 0 Current Value (MPC)";
CM_ SG_ 2432636031 StdRng_Spd_X_VehObj0_Cval_MPC "Longitudinal speed standard deviation range gate of vehicle object 0 Current Value (MPC)";
CM_ SG_ 2432636031 StdRng_Spd_Y_VehObj0_Cval_MPC "Lateral speed standard deviation range gate of vehicle object 0 Current Value (MPC)";
CM_ SG_ 2432636031 WidthVehObj0_Cval_MPC "Width of the vehicle object 0 Current value (MPC)";
CM_ SG_ 2432636031 OLA_VehObj0_Cval_MPC "OLA Vehicle Object 0 Current value MPC";
CM_ SG_ 2432636031 HeightVehObj0_Cval_MPC "Height over grorund of the vehicle object 0 Current value (MPC)";
CM_ SG_ 2432636031 LaneAlloc_VehObj0_Cval_MPC "Lane allocation of the vehicle object 0 Current value (MPC)";
CM_ SG_ 2432636031 TurnSgl_VehObj0_Cval_MPC "Turn Signal of vehicle object 0 Current value (MPC)";
CM_ SG_ 2432636031 LaneChgInd_VehObj0_Stat_MPC "LaneChange Indication of vehicle object 0 Current state (MPC)";
CM_ SG_ 2432636287 CRC_SG_MPC_C24_Pkt "Checksum C24 Current value MPC {E2,E1,E0,DF,DE,DD,DC,DB,DA,D9,D8,D7,D6,D5,D4,D3}";
CM_ SG_ 2432636287 SQC_SG_MPC_C24_Pkt "Message Counter C24 Current Value MPC";
CM_ SG_ 2432636287 ClassVehObj1_Stat_MPC "classification of vehicle object 1 Current state (MPC)";
CM_ SG_ 2432636287 NumVehObj1_Cval_MPC "object number of vehicle object 1 (MPC)";
CM_ SG_ 2432636287 TypeVehObj1_Stat_MPC "Object type of vehicle object 1 (MPC)";
CM_ SG_ 2432636287 StdRng_X_VehObj1_Cval_MPC "Longitudinal (x) standard deviation range gate of vehicle object 1 Current Value (MPC)";
CM_ SG_ 2432636287 StdRng_Y_VehObj1_Cval_MPC "Lateral (y) standard deviation range gate of vehicle object 1 Current Value (MPC)";
CM_ SG_ 2432636287 StdRng_Spd_X_VehObj1_Cval_MPC "Longitudinal speed standard deviation range gate of vehicle object 1 Current Value (MPC)";
CM_ SG_ 2432636287 StdRng_Spd_Y_VehObj1_Cval_MPC "Lateral speed standard deviation range gate of vehicle object 1 Current Value (MPC)";
CM_ SG_ 2432636287 WidthVehObj1_Cval_MPC "Width of the vehicle object 1 Current value (MPC)";
CM_ SG_ 2432636287 OLA_VehObj1_Cval_MPC "OLA Vehicle Object 1 Current value MPC";
CM_ SG_ 2432636287 HeightVehObj1_Cval_MPC "Height over grorund of the vehicle object 1 Current value (MPC)";
CM_ SG_ 2432636287 LaneAlloc_VehObj1_Cval_MPC "Lane allocation of the vehicle object 1 Current value (MPC)";
CM_ SG_ 2432636287 TurnSgl_VehObj1_Cval_MPC "Turn Signal of vehicle object 1 Current value (MPC)";
CM_ SG_ 2432636287 LaneChgInd_VehObj1_Stat_MPC "LaneChange Indication of vehicle object 1 Current state (MPC)";
CM_ SG_ 2432636543 CRC_SG_MPC_C25_Pkt "Checksum C25 Current value MPC {4F,C3,3C,B0,29,9D,16,8A,03,77,EB,64,D8,51,C5,3E}";
CM_ SG_ 2432636543 SQC_SG_MPC_C25_Pkt "Message Counter C25 Current value MPC";
CM_ SG_ 2432636543 ClassVehObj2_Stat_MPC "classification of vehicle object 2 Current state (MPC)";
CM_ SG_ 2432636543 NumVehObj2_Cval_MPC "object number of vehicle object 2 (MPC)";
CM_ SG_ 2432636543 TypeVehObj2_Stat_MPC "Object type of vehicle object 2 (MPC)";
CM_ SG_ 2432636543 StdRng_X_VehObj2_Cval_MPC "Longitudinal (x) standard deviation range gate of vehicle object 2 Current Value (MPC)";
CM_ SG_ 2432636543 StdRng_Y_VehObj2_Cval_MPC "Lateral (y) standard deviation range gate of vehicle object 2 Current Value (MPC)";
CM_ SG_ 2432636543 StdRng_Spd_X_VehObj2_Cval_MPC "Longitudinal speed standard deviation range gate of vehicle object 2 Current Value (MPC)";
CM_ SG_ 2432636543 StdRng_Spd_Y_VehObj2_Cval_MPC "Lateral speed standard deviation range gate of vehicle object 2 Current Value (MPC)";
CM_ SG_ 2432636543 WidthVehObj2_Cval_MPC "Width of the vehicle object 2 Current value (MPC)";
CM_ SG_ 2432636543 OLA_VehObj2_Cval_MPC "OLA Vehicle Object 2 Current value MPC";
CM_ SG_ 2432636543 HeightVehObj2_Cval_MPC "Height over grorund of the vehicle object 2 Current value (MPC)";
CM_ SG_ 2432636543 LaneAlloc_VehObj2_Cval_MPC "Lane allocation of the vehicle object 2 Current value (MPC)";
CM_ SG_ 2432636543 TurnSgl_VehObj2_Cval_MPC "Turn Signal of vehicle object 2 Current value (MPC)";
CM_ SG_ 2432636543 LaneChgInd_VehObj2_Stat_MPC "LaneChange Indication of vehicle object 2 Current state (MPC)";
CM_ SG_ 2432636799 CRC_SG_MPC_C26_Pkt "Checksum C26 Current value MPC {D8,13,49,7F,B5,EB,26,5C,92,C8,03,39,6F,A5,DB,16}";
CM_ SG_ 2432636799 SQC_SG_MPC_C26_Pkt "Message Counter C26 Current value MPC";
CM_ SG_ 2432636799 ClassVehObj3_Stat_MPC "classification of vehicle object 3 Current state (MPC)";
CM_ SG_ 2432636799 NumVehObj3_Cval_MPC "object number of vehicle object 3 (MPC)";
CM_ SG_ 2432636799 TypeVehObj03_Stat_MPC "Object type of vehicle object 3 (MPC)";
CM_ SG_ 2432636799 StdRng_X_VehObj3_Cval_MPC "Longitudinal (x) standard deviation range gate of vehicle object 3 Current Value (MPC)";
CM_ SG_ 2432636799 StdRng_Y_VehObj3_Cval_MPC "Lateral (y) standard deviation range gate of vehicle object 3 Current Value (MPC)";
CM_ SG_ 2432636799 StdRng_Spd_X_VehObj3_Cval_MPC "Longitudinal speed standard deviation range gate of vehicle object 3 Current Value (MPC)";
CM_ SG_ 2432636799 StdRng_Spd_Y_VehObj3_Cval_MPC "Lateral speed standard deviation range gate of vehicle object 3 Current Value (MPC)";
CM_ SG_ 2432636799 WidthVehObj3_Cval_MPC "Width of the vehicle object 3 Current value (MPC)";
CM_ SG_ 2432636799 OLA_VehObj3_Cval_MPC "OLA Vehicle Object 3 Current value MPC";
CM_ SG_ 2432636799 HeightVehObj3_Cval_MPC "Height over grorund of the vehicle object 3 Current value (MPC)";
CM_ SG_ 2432636799 LaneAlloc_VehObj3_Cval_MPC "Lane allocation of the vehicle object 3 Current value (MPC)";
CM_ SG_ 2432636799 TurnSgl_VehObj3_Cval_MPC "Turn Signal of vehicle object 3 Current value (MPC)";
CM_ SG_ 2432636799 LaneChgInd_VehObj3_Stat_MPC "LaneChange Indication of vehicle object 3 Current state (MPC)";
CM_ SG_ 2432637311 IHC_Tnl1_State_MPC "Tunnel 1 Current State (MPC)";
CM_ SG_ 2432637311 IHC_Tnl1_ChgOvrLvl_MPC "Tunnel 1 Changeover Level (MPC)";
CM_ SG_ 2432637311 BotDotRec_Stat "Bot Dot Recognition  Current state";
CM_ SG_ 2432637311 IHC_Tnl1_AngLmtLt_MPC "Tunnel 1 border left (MPC)";
CM_ SG_ 2432637311 IHC_Tnl1_AngLmtRt_MPC "Tunnel 1 border right (MPC)";
CM_ SG_ 2432637311 IHC_Tnl1_ActLgtDist_MPC "Tunnel 1 Actual Light Distance (MPC)";
CM_ SG_ 2432637311 IHC_Tnl2_State_MPC "Tunnel 2 Current State (MPC)";
CM_ SG_ 2432637311 IHC_Tnl2_ChgOvrLvl_MPC "Tunnel 2 Changeover Level (MPC)";
CM_ SG_ 2432637311 WarnPoleRec_Stat "Warning Pole Recognition Current state";
CM_ SG_ 2432637311 IHC_Tnl2_AngLmtLt_MPC "Tunnel 2 border left (MPC)";
CM_ SG_ 2432637311 IHC_Tnl2_AngLmtRt_MPC "Tunnel 2 border right (MPC)";
CM_ SG_ 2432637311 IHC_Tnl2_ActLgtDist_MPC "Tunnel 2 Actual Light Distance (MPC)";
CM_ SG_ 2432637567 CRC_SG_MPC_C30_Pkt "Checksum C30 Current value MPC {BE,DF,05,26,47,68,89,AA,CB,EC,12,33,54,75,96,B7}";
CM_ SG_ 2432637567 SQC_SG_MPC_C30_Pkt "Message Counter C30 Current Value MPC";
CM_ SG_ 2432637567 AnglLt_PedObj0_Cval_MPC "Angle Left Pedestrian Object 0 Current value MPC";
CM_ SG_ 2432637567 AnglRt_PedObj0_Cval_MPC "Angle Right Pedestrian Object 0 Current value MPC";
CM_ SG_ 2432637567 SclFctr_PedObj0_Cval_MPC "Scaling Factor Pedestrian Object 0 Current value MPC";
CM_ SG_ 2432637823 CRC_SG_MPC_C31_Pkt "Checksum C31 Current value MPC {9B,3A,D4,73,12,AC,4B,E5,84,23,BD,5C,F6,95,34,CE}";
CM_ SG_ 2432637823 SQC_SG_MPC_C31_Pkt "Message Counter C31 Current Value MPC";
CM_ SG_ 2432637823 AnglLt_PedObj1_Cval_MPC "Angle Left Pedestrian Object 1 Current value MPC";
CM_ SG_ 2432637823 AnglRt_PedObj1_Cval_MPC "Angle Right Pedestrian Object 1 Current value MPC";
CM_ SG_ 2432637823 SclFctr_PedObj1_Cval_MPC "Scaling Factor Pedestrian Object 1 Current value MPC";
CM_ SG_ 2432638079 CRC_SG_MPC_C32_Pkt "Checksum C32 Current value MPC {60,E5,6F,F4,7E,08,8D,17,9C,26,AB,35,BA,44,C9,53}";
CM_ SG_ 2432638079 SQC_SG_MPC_C32_Pkt "Message Counter C32 Current Value MPC";
CM_ SG_ 2432638079 AnglLt_PedObj2_Cval_MPC "Angle Left Pedestrian Object 2 Current value MPC";
CM_ SG_ 2432638079 AnglRt_PedObj2_Cval_MPC "Angle Right Pedestrian Object 2 Current value MPC";
CM_ SG_ 2432638079 SclFctr_PedObj2_Cval_MPC "Scaling Factor Pedestrian Object 2 Current value MPC";
CM_ SG_ 2432638335 CRC_SG_MPC_C33_Pkt "Checksum C33 Current value MPC {58,99,DA,20,61,A2,E3,29,6A,AB,EC,32,73,B4,F5,3B}";
CM_ SG_ 2432638335 SQC_SG_MPC_C33_Pkt "Message Counter C33 Current Value MPC";
CM_ SG_ 2432638335 AnglLt_PedObj3_Cval_MPC "Angle Left Pedestrian Object 3 Current value MPC";
CM_ SG_ 2432638335 AnglRt_PedObj3_Cval_MPC "Angle Right Pedestrian Object 3 Current value MPC";
CM_ SG_ 2432638335 SclFctr_PedObj3_Cval_MPC "Scaling Factor Pedestrian Object 3 Current value MPC";
CM_ SG_ 2432638591 CRC_SG_MPC_C34_Pkt "Checksum C34 Current value MPC {FB,2B,56,81,AC,D7,07,32,5D,88,B3,DE,0E,39,64,8F}";
CM_ SG_ 2432638591 SQC_SG_MPC_C34_Pkt "Message Counter C34 Current Value MPC";
CM_ SG_ 2432638591 AnglLt_PedObj4_Cval_MPC "Angle Left Pedestrian Object 4 Current value MPC";
CM_ SG_ 2432638591 AnglRt_PedObj4_Cval_MPC "Angle Right Pedestrian Object 4 Current value MPC";
CM_ SG_ 2432638591 SclFctr_PedObj4_Cval_MPC "Scaling Factor Pedestrian Object 4 Current value MPC";
CM_ SG_ 2432638847 CRC_SG_MPC_C35_Pkt "Checksum C35 Current value MPC {42,C1,45,C4,48,C7,4B,CA,4E,CD,51,D0,54,D3,57,D6}";
CM_ SG_ 2432638847 SQC_SG_MPC_C35_Pkt "Message Counter C35 Current Value MPC";
CM_ SG_ 2432638847 AnglLt_PedObj5_Cval_MPC "Angle Left Pedestrian Object 5 Current value MPC";
CM_ SG_ 2432638847 AnglRt_PedObj5_Cval_MPC "Angle Right Pedestrian Object 5 Current value MPC";
CM_ SG_ 2432638847 SclFctr_PedObj5_Cval_MPC "Scaling Factor Pedestrian Object 5 Current value MPC";
CM_ SG_ 2432639103 CRC_SG_MPC_C36_Pkt "Checksum C36 Current value MPC {D8,76,14,AD,4B,E4,82,20,B9,57,F0,8E,2C,C5,63,FC}";
CM_ SG_ 2432639103 SQC_SG_MPC_C36_Pkt "Message Counter C36 Current Value MPC";
CM_ SG_ 2432639103 AnglLt_VehObj0_Cval_MPC "Angle Left Vehicle Object 0 Current value MPC";
CM_ SG_ 2432639103 AnglRt_VehObj0_Cval_MPC "Angle Right Vehicle Object 0 Current value MPC";
CM_ SG_ 2432639103 SclFctr_VehObj0_Cval_MPC "Scaling Factor Vehicle Object 0 Current value MPC";
CM_ SG_ 2432639359 CRC_SG_MPC_C37_Pkt "Checksum C37 Current value MPC {96,84,72,60,4E,3C,2A,18,06,EF,DD,CB,B9,A7,95,83}";
CM_ SG_ 2432639359 SQC_SG_MPC_C37_Pkt "Message Counter C37 Current Value MPC";
CM_ SG_ 2432639359 AnglLt_VehObj1_Cval_MPC "Angle Left Vehicle Object 1 Current value MPC";
CM_ SG_ 2432639359 AnglRt_VehObj1_Cval_MPC "Angle Right Vehicle Object 1 Current value MPC";
CM_ SG_ 2432639359 SclFctr_VehObj1_Cval_MPC "Scaling Factor Vehicle Object 1 Current value MPC";
BA_DEF_ SG_  "GenSigTimeout_MPC2" INT 0 65535;
BA_DEF_ BO_  "GenMsgStartValue" STRING ;
BA_DEF_ SG_  "GenSigSNA" STRING ;
BA_DEF_ SG_  "FlexKomIsMotorola" ENUM  "nein","ja";
BA_DEF_ SG_  "FlexKomSigLaenge" INT 0 64;
BA_DEF_ SG_  "FlexKomSigStartPos" INT 0 63;
BA_DEF_ SG_  "FlexKomComment" STRING ;
BA_DEF_ SG_  "FlexKomSigName" STRING ;
BA_DEF_ SG_  "FlexKomSID" INT 0 2147483647;
BA_DEF_ SG_  "GenSigStartValue" HEX 0 4294967295;
BA_DEF_ SG_  "FlexKomSigStartValue" STRING ;
BA_DEF_ SG_  "GenSigCycleTime" INT 0 65535;
BA_DEF_ SG_  "GenSigSendType" ENUM  "cyclicX","spontanX","cyclicIfActiveX","spontanWithDelay","cyclicAndSpontanX","cyclicAndSpontanWithDelay","spontanWithRepitition","cyclicIfActiveAndSpontanWD","cyclicIfActiveFast","cyclicWithRepeatOnDemand","none";
BA_DEF_ BO_  "GenMsgNrOfRepetitions" INT 0 65535;
BA_DEF_ BO_  "GenMsgDelayTime" INT 0 65535;
BA_DEF_ BO_  "GenMsgStartDelayTime" INT 0 65535;
BA_DEF_ BO_  "GenMsgCycleTime" INT 0 65535;
BA_DEF_ BO_  "GenMsgSendType" ENUM  "cyclicX","spontanX","cyclicIfActiveX","spontanWithDelay","cyclicAndSpontanX","cyclicAndSpontanWithDelay","spontanWithRepitition","cyclicIfActiveAndSpontanWD","cyclicIfActiveFast","cyclicWithRepeatOnDemand","none";
BA_DEF_ BO_  "DiagResponse" ENUM  "nein","ja";
BA_DEF_ BO_  "DiagRequest" ENUM  "nein","ja";
BA_DEF_ BO_  "DiagState" ENUM  "nein","ja";
BA_DEF_ BO_  "App-Botschaft" ENUM  "nein","ja";
BA_DEF_ BO_  "NWM-Botschaft" ENUM  "nein","ja";
BA_DEF_ BO_  "GenMsgMinAcceptLength" INT -1 8;
BA_DEF_DEF_  "GenSigTimeout_MPC2" 0;
BA_DEF_DEF_  "GenMsgStartValue" "";
BA_DEF_DEF_  "GenSigSNA" "";
BA_DEF_DEF_  "FlexKomIsMotorola" "nein";
BA_DEF_DEF_  "FlexKomSigLaenge" 0;
BA_DEF_DEF_  "FlexKomSigStartPos" 0;
BA_DEF_DEF_  "FlexKomComment" "";
BA_DEF_DEF_  "FlexKomSigName" "";
BA_DEF_DEF_  "FlexKomSID" 0;
BA_DEF_DEF_  "GenSigStartValue" 0;
BA_DEF_DEF_  "FlexKomSigStartValue" "";
BA_DEF_DEF_  "GenSigCycleTime" 0;
BA_DEF_DEF_  "GenSigSendType" "cyclicX";
BA_DEF_DEF_  "GenMsgNrOfRepetitions" 0;
BA_DEF_DEF_  "GenMsgDelayTime" 0;
BA_DEF_DEF_  "GenMsgStartDelayTime" 0;
BA_DEF_DEF_  "GenMsgCycleTime" 0;
BA_DEF_DEF_  "GenMsgSendType" "cyclicX";
BA_DEF_DEF_  "DiagResponse" "nein";
BA_DEF_DEF_  "DiagRequest" "nein";
BA_DEF_DEF_  "DiagState" "nein";
BA_DEF_DEF_  "App-Botschaft" "nein";
BA_DEF_DEF_  "NWM-Botschaft" "nein";
BA_DEF_DEF_  "GenMsgMinAcceptLength" -1;
BA_ "GenMsgStartDelayTime" BO_ 2432634239 40;
BA_ "GenMsgStartValue" BO_ 2432634239 "32F0FFFFFFFFFFFFh";
BA_ "GenMsgNrOfRepetitions" BO_ 2432634239 2;
BA_ "GenMsgDelayTime" BO_ 2432634239 20;
BA_ "GenMsgCycleTime" BO_ 2432634239 50;
BA_ "GenMsgStartDelayTime" BO_ 2432634495 50;
BA_ "GenMsgStartValue" BO_ 2432634495 "1BF0FFFFFFFFFFFFh";
BA_ "GenMsgNrOfRepetitions" BO_ 2432634495 2;
BA_ "GenMsgDelayTime" BO_ 2432634495 20;
BA_ "GenMsgCycleTime" BO_ 2432634495 50;
BA_ "GenMsgStartDelayTime" BO_ 2432634751 60;
BA_ "GenMsgStartValue" BO_ 2432634751 "1BF0FFFFFFFFFFFFh";
BA_ "GenMsgNrOfRepetitions" BO_ 2432634751 2;
BA_ "GenMsgDelayTime" BO_ 2432634751 20;
BA_ "GenMsgCycleTime" BO_ 2432634751 50;
BA_ "GenMsgStartDelayTime" BO_ 2432635007 70;
BA_ "GenMsgStartValue" BO_ 2432635007 "74F0FFFFFFFFFFFFh";
BA_ "GenMsgNrOfRepetitions" BO_ 2432635007 2;
BA_ "GenMsgDelayTime" BO_ 2432635007 20;
BA_ "GenMsgCycleTime" BO_ 2432635007 50;
BA_ "GenMsgStartDelayTime" BO_ 2432635263 80;
BA_ "GenMsgStartValue" BO_ 2432635263 "9EF0FFFFFFFFFFFFh";
BA_ "GenMsgNrOfRepetitions" BO_ 2432635263 2;
BA_ "GenMsgDelayTime" BO_ 2432635263 20;
BA_ "GenMsgCycleTime" BO_ 2432635263 50;
BA_ "GenMsgStartDelayTime" BO_ 2432635519 90;
BA_ "GenMsgStartValue" BO_ 2432635519 "60F0FFFFFFFFFFFFh";
BA_ "GenMsgNrOfRepetitions" BO_ 2432635519 2;
BA_ "GenMsgDelayTime" BO_ 2432635519 20;
BA_ "GenMsgCycleTime" BO_ 2432635519 50;
BA_ "GenMsgStartDelayTime" BO_ 2432635775 100;
BA_ "GenMsgStartValue" BO_ 2432635775 "0DF0FFFFFFFFFFFFh";
BA_ "GenMsgNrOfRepetitions" BO_ 2432635775 2;
BA_ "GenMsgDelayTime" BO_ 2432635775 20;
BA_ "GenMsgCycleTime" BO_ 2432635775 50;
BA_ "GenMsgStartValue" BO_ 2432636031 "99F0FFFFFFFFFFFFh";
BA_ "GenMsgNrOfRepetitions" BO_ 2432636031 2;
BA_ "GenMsgDelayTime" BO_ 2432636031 20;
BA_ "GenMsgCycleTime" BO_ 2432636031 50;
BA_ "GenMsgStartDelayTime" BO_ 2432636287 10;
BA_ "GenMsgStartValue" BO_ 2432636287 "EEF0FFFFFFFFFFFFh";
BA_ "GenMsgNrOfRepetitions" BO_ 2432636287 2;
BA_ "GenMsgDelayTime" BO_ 2432636287 20;
BA_ "GenMsgCycleTime" BO_ 2432636287 50;
BA_ "GenMsgStartDelayTime" BO_ 2432636543 20;
BA_ "GenMsgStartValue" BO_ 2432636543 "BAF0FFFFFFFFFFFFh";
BA_ "GenMsgNrOfRepetitions" BO_ 2432636543 2;
BA_ "GenMsgDelayTime" BO_ 2432636543 20;
BA_ "GenMsgCycleTime" BO_ 2432636543 50;
BA_ "GenMsgStartDelayTime" BO_ 2432636799 30;
BA_ "GenMsgStartValue" BO_ 2432636799 "3AF0FFFFFFFFFFFFh";
BA_ "GenMsgNrOfRepetitions" BO_ 2432636799 2;
BA_ "GenMsgDelayTime" BO_ 2432636799 20;
BA_ "GenMsgCycleTime" BO_ 2432636799 50;
BA_ "GenMsgStartDelayTime" BO_ 2432637311 40;
BA_ "GenMsgStartValue" BO_ 2432637311 "FFFFFFFFFFFFFFFFh";
BA_ "GenMsgNrOfRepetitions" BO_ 2432637311 2;
BA_ "GenMsgDelayTime" BO_ 2432637311 20;
BA_ "GenMsgCycleTime" BO_ 2432637311 50;
BA_ "GenMsgStartDelayTime" BO_ 2432637567 60;
BA_ "GenMsgStartValue" BO_ 2432637567 "4DF0FFFFFFFFFFFFh";
BA_ "GenMsgNrOfRepetitions" BO_ 2432637567 2;
BA_ "GenMsgDelayTime" BO_ 2432637567 20;
BA_ "GenMsgCycleTime" BO_ 2432637567 50;
BA_ "GenMsgStartDelayTime" BO_ 2432637823 70;
BA_ "GenMsgStartValue" BO_ 2432637823 "ADF0FFFFFFFFFFFFh";
BA_ "GenMsgNrOfRepetitions" BO_ 2432637823 2;
BA_ "GenMsgDelayTime" BO_ 2432637823 20;
BA_ "GenMsgCycleTime" BO_ 2432637823 50;
BA_ "GenMsgStartDelayTime" BO_ 2432638079 80;
BA_ "GenMsgStartValue" BO_ 2432638079 "53F0FFFFFFFFFFFFh";
BA_ "GenMsgNrOfRepetitions" BO_ 2432638079 2;
BA_ "GenMsgDelayTime" BO_ 2432638079 20;
BA_ "GenMsgCycleTime" BO_ 2432638079 50;
BA_ "GenMsgStartDelayTime" BO_ 2432638335 90;
BA_ "GenMsgStartValue" BO_ 2432638335 "D9F0FFFFFFFFFFFFh";
BA_ "GenMsgNrOfRepetitions" BO_ 2432638335 2;
BA_ "GenMsgDelayTime" BO_ 2432638335 20;
BA_ "GenMsgCycleTime" BO_ 2432638335 50;
BA_ "GenMsgStartDelayTime" BO_ 2432638591 100;
BA_ "GenMsgStartValue" BO_ 2432638591 "38F0FFFFFFFFFFFFh";
BA_ "GenMsgNrOfRepetitions" BO_ 2432638591 2;
BA_ "GenMsgDelayTime" BO_ 2432638591 20;
BA_ "GenMsgCycleTime" BO_ 2432638591 50;
BA_ "GenMsgStartValue" BO_ 2432638847 "7EF0FFFFFFFFFFFFh";
BA_ "GenMsgNrOfRepetitions" BO_ 2432638847 2;
BA_ "GenMsgDelayTime" BO_ 2432638847 20;
BA_ "GenMsgCycleTime" BO_ 2432638847 50;
BA_ "GenMsgStartDelayTime" BO_ 2432639103 10;
BA_ "GenMsgStartValue" BO_ 2432639103 "3AF0FFFFFFFFFFFFh";
BA_ "GenMsgNrOfRepetitions" BO_ 2432639103 2;
BA_ "GenMsgDelayTime" BO_ 2432639103 20;
BA_ "GenMsgCycleTime" BO_ 2432639103 50;
BA_ "GenMsgStartDelayTime" BO_ 2432639359 20;
BA_ "GenMsgStartValue" BO_ 2432639359 "69F0FFFFFFFFFFFFh";
BA_ "GenMsgNrOfRepetitions" BO_ 2432639359 2;
BA_ "GenMsgDelayTime" BO_ 2432639359 20;
BA_ "GenMsgCycleTime" BO_ 2432639359 50;
BA_ "GenSigSNA" SG_ 2432634239 CRC_SG_MPC_C16_Pkt "32h";
BA_ "FlexKomIsMotorola" SG_ 2432634239 CRC_SG_MPC_C16_Pkt 1;
BA_ "FlexKomComment" SG_ 2432634239 CRC_SG_MPC_C16_Pkt "MPC_C16_Pkt";
BA_ "FlexKomSigName" SG_ 2432634239 CRC_SG_MPC_C16_Pkt "MPC_C16_Pkt";
BA_ "FlexKomSigLaenge" SG_ 2432634239 CRC_SG_MPC_C16_Pkt 64;
BA_ "FlexKomSigStartPos" SG_ 2432634239 CRC_SG_MPC_C16_Pkt 7;
BA_ "FlexKomSID" SG_ 2432634239 CRC_SG_MPC_C16_Pkt 100679832;
BA_ "GenSigStartValue" SG_ 2432634239 CRC_SG_MPC_C16_Pkt 50;
BA_ "FlexKomSigStartValue" SG_ 2432634239 CRC_SG_MPC_C16_Pkt "32F0FFFFFFFFFFFFh";
BA_ "GenSigCycleTime" SG_ 2432634239 CRC_SG_MPC_C16_Pkt 50;
BA_ "GenSigSNA" SG_ 2432634239 SQC_SG_MPC_C16_Pkt "0h";
BA_ "FlexKomIsMotorola" SG_ 2432634239 SQC_SG_MPC_C16_Pkt 1;
BA_ "FlexKomComment" SG_ 2432634239 SQC_SG_MPC_C16_Pkt "MPC_C16_Pkt";
BA_ "FlexKomSigName" SG_ 2432634239 SQC_SG_MPC_C16_Pkt "MPC_C16_Pkt";
BA_ "FlexKomSigLaenge" SG_ 2432634239 SQC_SG_MPC_C16_Pkt 64;
BA_ "FlexKomSigStartPos" SG_ 2432634239 SQC_SG_MPC_C16_Pkt 7;
BA_ "FlexKomSID" SG_ 2432634239 SQC_SG_MPC_C16_Pkt 100679832;
BA_ "FlexKomSigStartValue" SG_ 2432634239 SQC_SG_MPC_C16_Pkt "32F0FFFFFFFFFFFFh";
BA_ "GenSigCycleTime" SG_ 2432634239 SQC_SG_MPC_C16_Pkt 50;
BA_ "GenSigSNA" SG_ 2432634239 ClassPedObj3_Stat_MPC "Fh";
BA_ "FlexKomIsMotorola" SG_ 2432634239 ClassPedObj3_Stat_MPC 1;
BA_ "FlexKomComment" SG_ 2432634239 ClassPedObj3_Stat_MPC "MPC_C16_Pkt";
BA_ "FlexKomSigName" SG_ 2432634239 ClassPedObj3_Stat_MPC "MPC_C16_Pkt";
BA_ "FlexKomSigLaenge" SG_ 2432634239 ClassPedObj3_Stat_MPC 64;
BA_ "FlexKomSigStartPos" SG_ 2432634239 ClassPedObj3_Stat_MPC 7;
BA_ "FlexKomSID" SG_ 2432634239 ClassPedObj3_Stat_MPC 100679832;
BA_ "GenSigStartValue" SG_ 2432634239 ClassPedObj3_Stat_MPC 15;
BA_ "FlexKomSigStartValue" SG_ 2432634239 ClassPedObj3_Stat_MPC "32F0FFFFFFFFFFFFh";
BA_ "GenSigCycleTime" SG_ 2432634239 ClassPedObj3_Stat_MPC 50;
BA_ "GenSigSNA" SG_ 2432634239 NumPedObj3_Cval_MPC "1Fh";
BA_ "FlexKomIsMotorola" SG_ 2432634239 NumPedObj3_Cval_MPC 1;
BA_ "FlexKomComment" SG_ 2432634239 NumPedObj3_Cval_MPC "MPC_C16_Pkt";
BA_ "FlexKomSigName" SG_ 2432634239 NumPedObj3_Cval_MPC "MPC_C16_Pkt";
BA_ "FlexKomSigLaenge" SG_ 2432634239 NumPedObj3_Cval_MPC 64;
BA_ "FlexKomSigStartPos" SG_ 2432634239 NumPedObj3_Cval_MPC 7;
BA_ "FlexKomSID" SG_ 2432634239 NumPedObj3_Cval_MPC 100679832;
BA_ "GenSigStartValue" SG_ 2432634239 NumPedObj3_Cval_MPC 31;
BA_ "FlexKomSigStartValue" SG_ 2432634239 NumPedObj3_Cval_MPC "32F0FFFFFFFFFFFFh";
BA_ "GenSigCycleTime" SG_ 2432634239 NumPedObj3_Cval_MPC 50;
BA_ "GenSigSNA" SG_ 2432634239 TypePedObj3_Stat_MPC "7h";
BA_ "FlexKomIsMotorola" SG_ 2432634239 TypePedObj3_Stat_MPC 1;
BA_ "FlexKomComment" SG_ 2432634239 TypePedObj3_Stat_MPC "MPC_C16_Pkt";
BA_ "FlexKomSigName" SG_ 2432634239 TypePedObj3_Stat_MPC "MPC_C16_Pkt";
BA_ "FlexKomSigLaenge" SG_ 2432634239 TypePedObj3_Stat_MPC 64;
BA_ "FlexKomSigStartPos" SG_ 2432634239 TypePedObj3_Stat_MPC 7;
BA_ "FlexKomSID" SG_ 2432634239 TypePedObj3_Stat_MPC 100679832;
BA_ "GenSigStartValue" SG_ 2432634239 TypePedObj3_Stat_MPC 7;
BA_ "FlexKomSigStartValue" SG_ 2432634239 TypePedObj3_Stat_MPC "32F0FFFFFFFFFFFFh";
BA_ "GenSigCycleTime" SG_ 2432634239 TypePedObj3_Stat_MPC 50;
BA_ "GenSigSNA" SG_ 2432634239 StdRng_X_PedObj3_Cval_MPC "3h";
BA_ "FlexKomIsMotorola" SG_ 2432634239 StdRng_X_PedObj3_Cval_MPC 1;
BA_ "FlexKomComment" SG_ 2432634239 StdRng_X_PedObj3_Cval_MPC "MPC_C16_Pkt";
BA_ "FlexKomSigName" SG_ 2432634239 StdRng_X_PedObj3_Cval_MPC "MPC_C16_Pkt";
BA_ "FlexKomSigLaenge" SG_ 2432634239 StdRng_X_PedObj3_Cval_MPC 64;
BA_ "FlexKomSigStartPos" SG_ 2432634239 StdRng_X_PedObj3_Cval_MPC 7;
BA_ "FlexKomSID" SG_ 2432634239 StdRng_X_PedObj3_Cval_MPC 100679832;
BA_ "GenSigStartValue" SG_ 2432634239 StdRng_X_PedObj3_Cval_MPC 3;
BA_ "FlexKomSigStartValue" SG_ 2432634239 StdRng_X_PedObj3_Cval_MPC "32F0FFFFFFFFFFFFh";
BA_ "GenSigCycleTime" SG_ 2432634239 StdRng_X_PedObj3_Cval_MPC 50;
BA_ "GenSigSNA" SG_ 2432634239 StdRng_Y_PedObj3_Cval_MPC "3h";
BA_ "FlexKomIsMotorola" SG_ 2432634239 StdRng_Y_PedObj3_Cval_MPC 1;
BA_ "FlexKomComment" SG_ 2432634239 StdRng_Y_PedObj3_Cval_MPC "MPC_C16_Pkt";
BA_ "FlexKomSigName" SG_ 2432634239 StdRng_Y_PedObj3_Cval_MPC "MPC_C16_Pkt";
BA_ "FlexKomSigLaenge" SG_ 2432634239 StdRng_Y_PedObj3_Cval_MPC 64;
BA_ "FlexKomSigStartPos" SG_ 2432634239 StdRng_Y_PedObj3_Cval_MPC 7;
BA_ "FlexKomSID" SG_ 2432634239 StdRng_Y_PedObj3_Cval_MPC 100679832;
BA_ "GenSigStartValue" SG_ 2432634239 StdRng_Y_PedObj3_Cval_MPC 3;
BA_ "FlexKomSigStartValue" SG_ 2432634239 StdRng_Y_PedObj3_Cval_MPC "32F0FFFFFFFFFFFFh";
BA_ "GenSigCycleTime" SG_ 2432634239 StdRng_Y_PedObj3_Cval_MPC 50;
BA_ "GenSigSNA" SG_ 2432634239 StdRng_Spd_X_PedObj3_Cval_MPC "3h";
BA_ "FlexKomIsMotorola" SG_ 2432634239 StdRng_Spd_X_PedObj3_Cval_MPC 1;
BA_ "FlexKomComment" SG_ 2432634239 StdRng_Spd_X_PedObj3_Cval_MPC "MPC_C16_Pkt";
BA_ "FlexKomSigName" SG_ 2432634239 StdRng_Spd_X_PedObj3_Cval_MPC "MPC_C16_Pkt";
BA_ "FlexKomSigLaenge" SG_ 2432634239 StdRng_Spd_X_PedObj3_Cval_MPC 64;
BA_ "FlexKomSigStartPos" SG_ 2432634239 StdRng_Spd_X_PedObj3_Cval_MPC 7;
BA_ "FlexKomSID" SG_ 2432634239 StdRng_Spd_X_PedObj3_Cval_MPC 100679832;
BA_ "GenSigStartValue" SG_ 2432634239 StdRng_Spd_X_PedObj3_Cval_MPC 3;
BA_ "FlexKomSigStartValue" SG_ 2432634239 StdRng_Spd_X_PedObj3_Cval_MPC "32F0FFFFFFFFFFFFh";
BA_ "GenSigCycleTime" SG_ 2432634239 StdRng_Spd_X_PedObj3_Cval_MPC 50;
BA_ "GenSigSNA" SG_ 2432634239 StdRng_Spd_Y_PedObj3_Cval_MPC "3h";
BA_ "FlexKomIsMotorola" SG_ 2432634239 StdRng_Spd_Y_PedObj3_Cval_MPC 1;
BA_ "FlexKomComment" SG_ 2432634239 StdRng_Spd_Y_PedObj3_Cval_MPC "MPC_C16_Pkt";
BA_ "FlexKomSigName" SG_ 2432634239 StdRng_Spd_Y_PedObj3_Cval_MPC "MPC_C16_Pkt";
BA_ "FlexKomSigLaenge" SG_ 2432634239 StdRng_Spd_Y_PedObj3_Cval_MPC 64;
BA_ "FlexKomSigStartPos" SG_ 2432634239 StdRng_Spd_Y_PedObj3_Cval_MPC 7;
BA_ "FlexKomSID" SG_ 2432634239 StdRng_Spd_Y_PedObj3_Cval_MPC 100679832;
BA_ "GenSigStartValue" SG_ 2432634239 StdRng_Spd_Y_PedObj3_Cval_MPC 3;
BA_ "FlexKomSigStartValue" SG_ 2432634239 StdRng_Spd_Y_PedObj3_Cval_MPC "32F0FFFFFFFFFFFFh";
BA_ "GenSigCycleTime" SG_ 2432634239 StdRng_Spd_Y_PedObj3_Cval_MPC 50;
BA_ "GenSigSNA" SG_ 2432634239 WidthPedObj3_Cval_MPC "FFh";
BA_ "FlexKomIsMotorola" SG_ 2432634239 WidthPedObj3_Cval_MPC 1;
BA_ "FlexKomComment" SG_ 2432634239 WidthPedObj3_Cval_MPC "MPC_C16_Pkt";
BA_ "FlexKomSigName" SG_ 2432634239 WidthPedObj3_Cval_MPC "MPC_C16_Pkt";
BA_ "FlexKomSigLaenge" SG_ 2432634239 WidthPedObj3_Cval_MPC 64;
BA_ "FlexKomSigStartPos" SG_ 2432634239 WidthPedObj3_Cval_MPC 7;
BA_ "FlexKomSID" SG_ 2432634239 WidthPedObj3_Cval_MPC 100679832;
BA_ "GenSigStartValue" SG_ 2432634239 WidthPedObj3_Cval_MPC 255;
BA_ "FlexKomSigStartValue" SG_ 2432634239 WidthPedObj3_Cval_MPC "32F0FFFFFFFFFFFFh";
BA_ "GenSigCycleTime" SG_ 2432634239 WidthPedObj3_Cval_MPC 50;
BA_ "GenSigSNA" SG_ 2432634239 OLA_PedObj3_Cval_MPC "FFh";
BA_ "FlexKomIsMotorola" SG_ 2432634239 OLA_PedObj3_Cval_MPC 1;
BA_ "FlexKomComment" SG_ 2432634239 OLA_PedObj3_Cval_MPC "MPC_C16_Pkt";
BA_ "FlexKomSigName" SG_ 2432634239 OLA_PedObj3_Cval_MPC "MPC_C16_Pkt";
BA_ "FlexKomSigLaenge" SG_ 2432634239 OLA_PedObj3_Cval_MPC 64;
BA_ "FlexKomSigStartPos" SG_ 2432634239 OLA_PedObj3_Cval_MPC 7;
BA_ "FlexKomSID" SG_ 2432634239 OLA_PedObj3_Cval_MPC 100679832;
BA_ "GenSigStartValue" SG_ 2432634239 OLA_PedObj3_Cval_MPC 255;
BA_ "FlexKomSigStartValue" SG_ 2432634239 OLA_PedObj3_Cval_MPC "32F0FFFFFFFFFFFFh";
BA_ "GenSigCycleTime" SG_ 2432634239 OLA_PedObj3_Cval_MPC 50;
BA_ "GenSigSNA" SG_ 2432634239 HeightPedObj3_Cval_MPC "FFh";
BA_ "FlexKomIsMotorola" SG_ 2432634239 HeightPedObj3_Cval_MPC 1;
BA_ "FlexKomComment" SG_ 2432634239 HeightPedObj3_Cval_MPC "MPC_C16_Pkt";
BA_ "FlexKomSigName" SG_ 2432634239 HeightPedObj3_Cval_MPC "MPC_C16_Pkt";
BA_ "FlexKomSigLaenge" SG_ 2432634239 HeightPedObj3_Cval_MPC 64;
BA_ "FlexKomSigStartPos" SG_ 2432634239 HeightPedObj3_Cval_MPC 7;
BA_ "FlexKomSID" SG_ 2432634239 HeightPedObj3_Cval_MPC 100679832;
BA_ "GenSigStartValue" SG_ 2432634239 HeightPedObj3_Cval_MPC 255;
BA_ "FlexKomSigStartValue" SG_ 2432634239 HeightPedObj3_Cval_MPC "32F0FFFFFFFFFFFFh";
BA_ "GenSigCycleTime" SG_ 2432634239 HeightPedObj3_Cval_MPC 50;
BA_ "GenSigSNA" SG_ 2432634239 LaneAlloc_PedObj3_Cval_MPC "7h";
BA_ "FlexKomIsMotorola" SG_ 2432634239 LaneAlloc_PedObj3_Cval_MPC 1;
BA_ "FlexKomComment" SG_ 2432634239 LaneAlloc_PedObj3_Cval_MPC "MPC_C16_Pkt";
BA_ "FlexKomSigName" SG_ 2432634239 LaneAlloc_PedObj3_Cval_MPC "MPC_C16_Pkt";
BA_ "FlexKomSigLaenge" SG_ 2432634239 LaneAlloc_PedObj3_Cval_MPC 64;
BA_ "FlexKomSigStartPos" SG_ 2432634239 LaneAlloc_PedObj3_Cval_MPC 7;
BA_ "FlexKomSID" SG_ 2432634239 LaneAlloc_PedObj3_Cval_MPC 100679832;
BA_ "GenSigStartValue" SG_ 2432634239 LaneAlloc_PedObj3_Cval_MPC 7;
BA_ "FlexKomSigStartValue" SG_ 2432634239 LaneAlloc_PedObj3_Cval_MPC "32F0FFFFFFFFFFFFh";
BA_ "GenSigCycleTime" SG_ 2432634239 LaneAlloc_PedObj3_Cval_MPC 50;
BA_ "GenSigSNA" SG_ 2432634239 TurnSgl_PedObj3_Cval_MPC "7h";
BA_ "FlexKomIsMotorola" SG_ 2432634239 TurnSgl_PedObj3_Cval_MPC 1;
BA_ "FlexKomComment" SG_ 2432634239 TurnSgl_PedObj3_Cval_MPC "MPC_C16_Pkt";
BA_ "FlexKomSigName" SG_ 2432634239 TurnSgl_PedObj3_Cval_MPC "MPC_C16_Pkt";
BA_ "FlexKomSigLaenge" SG_ 2432634239 TurnSgl_PedObj3_Cval_MPC 64;
BA_ "FlexKomSigStartPos" SG_ 2432634239 TurnSgl_PedObj3_Cval_MPC 7;
BA_ "FlexKomSID" SG_ 2432634239 TurnSgl_PedObj3_Cval_MPC 100679832;
BA_ "GenSigStartValue" SG_ 2432634239 TurnSgl_PedObj3_Cval_MPC 7;
BA_ "FlexKomSigStartValue" SG_ 2432634239 TurnSgl_PedObj3_Cval_MPC "32F0FFFFFFFFFFFFh";
BA_ "GenSigCycleTime" SG_ 2432634239 TurnSgl_PedObj3_Cval_MPC 50;
BA_ "GenSigSNA" SG_ 2432634239 LaneChgInd_PedObj3_Stat_MPC "3h";
BA_ "FlexKomIsMotorola" SG_ 2432634239 LaneChgInd_PedObj3_Stat_MPC 1;
BA_ "FlexKomComment" SG_ 2432634239 LaneChgInd_PedObj3_Stat_MPC "MPC_C16_Pkt";
BA_ "FlexKomSigName" SG_ 2432634239 LaneChgInd_PedObj3_Stat_MPC "MPC_C16_Pkt";
BA_ "FlexKomSigLaenge" SG_ 2432634239 LaneChgInd_PedObj3_Stat_MPC 64;
BA_ "FlexKomSigStartPos" SG_ 2432634239 LaneChgInd_PedObj3_Stat_MPC 7;
BA_ "FlexKomSID" SG_ 2432634239 LaneChgInd_PedObj3_Stat_MPC 100679832;
BA_ "GenSigStartValue" SG_ 2432634239 LaneChgInd_PedObj3_Stat_MPC 3;
BA_ "FlexKomSigStartValue" SG_ 2432634239 LaneChgInd_PedObj3_Stat_MPC "32F0FFFFFFFFFFFFh";
BA_ "GenSigCycleTime" SG_ 2432634239 LaneChgInd_PedObj3_Stat_MPC 50;
BA_ "GenSigSNA" SG_ 2432634495 CRC_SG_MPC_C17_Pkt "1Bh";
BA_ "FlexKomIsMotorola" SG_ 2432634495 CRC_SG_MPC_C17_Pkt 1;
BA_ "FlexKomComment" SG_ 2432634495 CRC_SG_MPC_C17_Pkt "MPC_C17_Pkt";
BA_ "FlexKomSigName" SG_ 2432634495 CRC_SG_MPC_C17_Pkt "MPC_C17_Pkt";
BA_ "FlexKomSigLaenge" SG_ 2432634495 CRC_SG_MPC_C17_Pkt 64;
BA_ "FlexKomSigStartPos" SG_ 2432634495 CRC_SG_MPC_C17_Pkt 7;
BA_ "FlexKomSID" SG_ 2432634495 CRC_SG_MPC_C17_Pkt 100679834;
BA_ "GenSigStartValue" SG_ 2432634495 CRC_SG_MPC_C17_Pkt 27;
BA_ "FlexKomSigStartValue" SG_ 2432634495 CRC_SG_MPC_C17_Pkt "1BF0FFFFFFFFFFFFh";
BA_ "GenSigCycleTime" SG_ 2432634495 CRC_SG_MPC_C17_Pkt 50;
BA_ "GenSigSNA" SG_ 2432634495 SQC_SG_MPC_C17_Pkt "0h";
BA_ "FlexKomIsMotorola" SG_ 2432634495 SQC_SG_MPC_C17_Pkt 1;
BA_ "FlexKomComment" SG_ 2432634495 SQC_SG_MPC_C17_Pkt "MPC_C17_Pkt";
BA_ "FlexKomSigName" SG_ 2432634495 SQC_SG_MPC_C17_Pkt "MPC_C17_Pkt";
BA_ "FlexKomSigLaenge" SG_ 2432634495 SQC_SG_MPC_C17_Pkt 64;
BA_ "FlexKomSigStartPos" SG_ 2432634495 SQC_SG_MPC_C17_Pkt 7;
BA_ "FlexKomSID" SG_ 2432634495 SQC_SG_MPC_C17_Pkt 100679834;
BA_ "FlexKomSigStartValue" SG_ 2432634495 SQC_SG_MPC_C17_Pkt "1BF0FFFFFFFFFFFFh";
BA_ "GenSigCycleTime" SG_ 2432634495 SQC_SG_MPC_C17_Pkt 50;
BA_ "GenSigSNA" SG_ 2432634495 ClassPedObj4_Stat_MPC "Fh";
BA_ "FlexKomIsMotorola" SG_ 2432634495 ClassPedObj4_Stat_MPC 1;
BA_ "FlexKomComment" SG_ 2432634495 ClassPedObj4_Stat_MPC "MPC_C17_Pkt";
BA_ "FlexKomSigName" SG_ 2432634495 ClassPedObj4_Stat_MPC "MPC_C17_Pkt";
BA_ "FlexKomSigLaenge" SG_ 2432634495 ClassPedObj4_Stat_MPC 64;
BA_ "FlexKomSigStartPos" SG_ 2432634495 ClassPedObj4_Stat_MPC 7;
BA_ "FlexKomSID" SG_ 2432634495 ClassPedObj4_Stat_MPC 100679834;
BA_ "GenSigStartValue" SG_ 2432634495 ClassPedObj4_Stat_MPC 15;
BA_ "FlexKomSigStartValue" SG_ 2432634495 ClassPedObj4_Stat_MPC "1BF0FFFFFFFFFFFFh";
BA_ "GenSigCycleTime" SG_ 2432634495 ClassPedObj4_Stat_MPC 50;
BA_ "GenSigSNA" SG_ 2432634495 NumPedObj4_Cval_MPC "1Fh";
BA_ "FlexKomIsMotorola" SG_ 2432634495 NumPedObj4_Cval_MPC 1;
BA_ "FlexKomComment" SG_ 2432634495 NumPedObj4_Cval_MPC "MPC_C17_Pkt";
BA_ "FlexKomSigName" SG_ 2432634495 NumPedObj4_Cval_MPC "MPC_C17_Pkt";
BA_ "FlexKomSigLaenge" SG_ 2432634495 NumPedObj4_Cval_MPC 64;
BA_ "FlexKomSigStartPos" SG_ 2432634495 NumPedObj4_Cval_MPC 7;
BA_ "FlexKomSID" SG_ 2432634495 NumPedObj4_Cval_MPC 100679834;
BA_ "GenSigStartValue" SG_ 2432634495 NumPedObj4_Cval_MPC 31;
BA_ "FlexKomSigStartValue" SG_ 2432634495 NumPedObj4_Cval_MPC "1BF0FFFFFFFFFFFFh";
BA_ "GenSigCycleTime" SG_ 2432634495 NumPedObj4_Cval_MPC 50;
BA_ "GenSigSNA" SG_ 2432634495 TypePedObj4_Stat_MPC "7h";
BA_ "FlexKomIsMotorola" SG_ 2432634495 TypePedObj4_Stat_MPC 1;
BA_ "FlexKomComment" SG_ 2432634495 TypePedObj4_Stat_MPC "MPC_C17_Pkt";
BA_ "FlexKomSigName" SG_ 2432634495 TypePedObj4_Stat_MPC "MPC_C17_Pkt";
BA_ "FlexKomSigLaenge" SG_ 2432634495 TypePedObj4_Stat_MPC 64;
BA_ "FlexKomSigStartPos" SG_ 2432634495 TypePedObj4_Stat_MPC 7;
BA_ "FlexKomSID" SG_ 2432634495 TypePedObj4_Stat_MPC 100679834;
BA_ "GenSigStartValue" SG_ 2432634495 TypePedObj4_Stat_MPC 7;
BA_ "FlexKomSigStartValue" SG_ 2432634495 TypePedObj4_Stat_MPC "1BF0FFFFFFFFFFFFh";
BA_ "GenSigCycleTime" SG_ 2432634495 TypePedObj4_Stat_MPC 50;
BA_ "GenSigSNA" SG_ 2432634495 StdRng_X_PedObj4_Cval_MPC "3h";
BA_ "FlexKomIsMotorola" SG_ 2432634495 StdRng_X_PedObj4_Cval_MPC 1;
BA_ "FlexKomComment" SG_ 2432634495 StdRng_X_PedObj4_Cval_MPC "MPC_C17_Pkt";
BA_ "FlexKomSigName" SG_ 2432634495 StdRng_X_PedObj4_Cval_MPC "MPC_C17_Pkt";
BA_ "FlexKomSigLaenge" SG_ 2432634495 StdRng_X_PedObj4_Cval_MPC 64;
BA_ "FlexKomSigStartPos" SG_ 2432634495 StdRng_X_PedObj4_Cval_MPC 7;
BA_ "FlexKomSID" SG_ 2432634495 StdRng_X_PedObj4_Cval_MPC 100679834;
BA_ "GenSigStartValue" SG_ 2432634495 StdRng_X_PedObj4_Cval_MPC 3;
BA_ "FlexKomSigStartValue" SG_ 2432634495 StdRng_X_PedObj4_Cval_MPC "1BF0FFFFFFFFFFFFh";
BA_ "GenSigCycleTime" SG_ 2432634495 StdRng_X_PedObj4_Cval_MPC 50;
BA_ "GenSigSNA" SG_ 2432634495 StdRng_Y_PedObj4_Cval_MPC "3h";
BA_ "FlexKomIsMotorola" SG_ 2432634495 StdRng_Y_PedObj4_Cval_MPC 1;
BA_ "FlexKomComment" SG_ 2432634495 StdRng_Y_PedObj4_Cval_MPC "MPC_C17_Pkt";
BA_ "FlexKomSigName" SG_ 2432634495 StdRng_Y_PedObj4_Cval_MPC "MPC_C17_Pkt";
BA_ "FlexKomSigLaenge" SG_ 2432634495 StdRng_Y_PedObj4_Cval_MPC 64;
BA_ "FlexKomSigStartPos" SG_ 2432634495 StdRng_Y_PedObj4_Cval_MPC 7;
BA_ "FlexKomSID" SG_ 2432634495 StdRng_Y_PedObj4_Cval_MPC 100679834;
BA_ "GenSigStartValue" SG_ 2432634495 StdRng_Y_PedObj4_Cval_MPC 3;
BA_ "FlexKomSigStartValue" SG_ 2432634495 StdRng_Y_PedObj4_Cval_MPC "1BF0FFFFFFFFFFFFh";
BA_ "GenSigCycleTime" SG_ 2432634495 StdRng_Y_PedObj4_Cval_MPC 50;
BA_ "GenSigSNA" SG_ 2432634495 StdRng_Spd_X_PedObj4_Cval_MPC "3h";
BA_ "FlexKomIsMotorola" SG_ 2432634495 StdRng_Spd_X_PedObj4_Cval_MPC 1;
BA_ "FlexKomComment" SG_ 2432634495 StdRng_Spd_X_PedObj4_Cval_MPC "MPC_C17_Pkt";
BA_ "FlexKomSigName" SG_ 2432634495 StdRng_Spd_X_PedObj4_Cval_MPC "MPC_C17_Pkt";
BA_ "FlexKomSigLaenge" SG_ 2432634495 StdRng_Spd_X_PedObj4_Cval_MPC 64;
BA_ "FlexKomSigStartPos" SG_ 2432634495 StdRng_Spd_X_PedObj4_Cval_MPC 7;
BA_ "FlexKomSID" SG_ 2432634495 StdRng_Spd_X_PedObj4_Cval_MPC 100679834;
BA_ "GenSigStartValue" SG_ 2432634495 StdRng_Spd_X_PedObj4_Cval_MPC 3;
BA_ "FlexKomSigStartValue" SG_ 2432634495 StdRng_Spd_X_PedObj4_Cval_MPC "1BF0FFFFFFFFFFFFh";
BA_ "GenSigCycleTime" SG_ 2432634495 StdRng_Spd_X_PedObj4_Cval_MPC 50;
BA_ "GenSigSNA" SG_ 2432634495 StdRng_Spd_Y_PedObj4_Cval_MPC "3h";
BA_ "FlexKomIsMotorola" SG_ 2432634495 StdRng_Spd_Y_PedObj4_Cval_MPC 1;
BA_ "FlexKomComment" SG_ 2432634495 StdRng_Spd_Y_PedObj4_Cval_MPC "MPC_C17_Pkt";
BA_ "FlexKomSigName" SG_ 2432634495 StdRng_Spd_Y_PedObj4_Cval_MPC "MPC_C17_Pkt";
BA_ "FlexKomSigLaenge" SG_ 2432634495 StdRng_Spd_Y_PedObj4_Cval_MPC 64;
BA_ "FlexKomSigStartPos" SG_ 2432634495 StdRng_Spd_Y_PedObj4_Cval_MPC 7;
BA_ "FlexKomSID" SG_ 2432634495 StdRng_Spd_Y_PedObj4_Cval_MPC 100679834;
BA_ "GenSigStartValue" SG_ 2432634495 StdRng_Spd_Y_PedObj4_Cval_MPC 3;
BA_ "FlexKomSigStartValue" SG_ 2432634495 StdRng_Spd_Y_PedObj4_Cval_MPC "1BF0FFFFFFFFFFFFh";
BA_ "GenSigCycleTime" SG_ 2432634495 StdRng_Spd_Y_PedObj4_Cval_MPC 50;
BA_ "GenSigSNA" SG_ 2432634495 WidthPedObj4_Cval_MPC "FFh";
BA_ "FlexKomIsMotorola" SG_ 2432634495 WidthPedObj4_Cval_MPC 1;
BA_ "FlexKomComment" SG_ 2432634495 WidthPedObj4_Cval_MPC "MPC_C17_Pkt";
BA_ "FlexKomSigName" SG_ 2432634495 WidthPedObj4_Cval_MPC "MPC_C17_Pkt";
BA_ "FlexKomSigLaenge" SG_ 2432634495 WidthPedObj4_Cval_MPC 64;
BA_ "FlexKomSigStartPos" SG_ 2432634495 WidthPedObj4_Cval_MPC 7;
BA_ "FlexKomSID" SG_ 2432634495 WidthPedObj4_Cval_MPC 100679834;
BA_ "GenSigStartValue" SG_ 2432634495 WidthPedObj4_Cval_MPC 255;
BA_ "FlexKomSigStartValue" SG_ 2432634495 WidthPedObj4_Cval_MPC "1BF0FFFFFFFFFFFFh";
BA_ "GenSigCycleTime" SG_ 2432634495 WidthPedObj4_Cval_MPC 50;
BA_ "GenSigSNA" SG_ 2432634495 OLA_PedObj4_Cval_MPC "FFh";
BA_ "FlexKomIsMotorola" SG_ 2432634495 OLA_PedObj4_Cval_MPC 1;
BA_ "FlexKomComment" SG_ 2432634495 OLA_PedObj4_Cval_MPC "MPC_C17_Pkt";
BA_ "FlexKomSigName" SG_ 2432634495 OLA_PedObj4_Cval_MPC "MPC_C17_Pkt";
BA_ "FlexKomSigLaenge" SG_ 2432634495 OLA_PedObj4_Cval_MPC 64;
BA_ "FlexKomSigStartPos" SG_ 2432634495 OLA_PedObj4_Cval_MPC 7;
BA_ "FlexKomSID" SG_ 2432634495 OLA_PedObj4_Cval_MPC 100679834;
BA_ "GenSigStartValue" SG_ 2432634495 OLA_PedObj4_Cval_MPC 255;
BA_ "FlexKomSigStartValue" SG_ 2432634495 OLA_PedObj4_Cval_MPC "1BF0FFFFFFFFFFFFh";
BA_ "GenSigCycleTime" SG_ 2432634495 OLA_PedObj4_Cval_MPC 50;
BA_ "GenSigSNA" SG_ 2432634495 HeightPedObj4_Cval_MPC "FFh";
BA_ "FlexKomIsMotorola" SG_ 2432634495 HeightPedObj4_Cval_MPC 1;
BA_ "FlexKomComment" SG_ 2432634495 HeightPedObj4_Cval_MPC "MPC_C17_Pkt";
BA_ "FlexKomSigName" SG_ 2432634495 HeightPedObj4_Cval_MPC "MPC_C17_Pkt";
BA_ "FlexKomSigLaenge" SG_ 2432634495 HeightPedObj4_Cval_MPC 64;
BA_ "FlexKomSigStartPos" SG_ 2432634495 HeightPedObj4_Cval_MPC 7;
BA_ "FlexKomSID" SG_ 2432634495 HeightPedObj4_Cval_MPC 100679834;
BA_ "GenSigStartValue" SG_ 2432634495 HeightPedObj4_Cval_MPC 255;
BA_ "FlexKomSigStartValue" SG_ 2432634495 HeightPedObj4_Cval_MPC "1BF0FFFFFFFFFFFFh";
BA_ "GenSigCycleTime" SG_ 2432634495 HeightPedObj4_Cval_MPC 50;
BA_ "GenSigSNA" SG_ 2432634495 LaneAlloc_PedObj4_Cval_MPC "7h";
BA_ "FlexKomIsMotorola" SG_ 2432634495 LaneAlloc_PedObj4_Cval_MPC 1;
BA_ "FlexKomComment" SG_ 2432634495 LaneAlloc_PedObj4_Cval_MPC "MPC_C17_Pkt";
BA_ "FlexKomSigName" SG_ 2432634495 LaneAlloc_PedObj4_Cval_MPC "MPC_C17_Pkt";
BA_ "FlexKomSigLaenge" SG_ 2432634495 LaneAlloc_PedObj4_Cval_MPC 64;
BA_ "FlexKomSigStartPos" SG_ 2432634495 LaneAlloc_PedObj4_Cval_MPC 7;
BA_ "FlexKomSID" SG_ 2432634495 LaneAlloc_PedObj4_Cval_MPC 100679834;
BA_ "GenSigStartValue" SG_ 2432634495 LaneAlloc_PedObj4_Cval_MPC 7;
BA_ "FlexKomSigStartValue" SG_ 2432634495 LaneAlloc_PedObj4_Cval_MPC "1BF0FFFFFFFFFFFFh";
BA_ "GenSigCycleTime" SG_ 2432634495 LaneAlloc_PedObj4_Cval_MPC 50;
BA_ "GenSigSNA" SG_ 2432634495 TurnSgl_PedObj4_Cval_MPC "7h";
BA_ "FlexKomIsMotorola" SG_ 2432634495 TurnSgl_PedObj4_Cval_MPC 1;
BA_ "FlexKomComment" SG_ 2432634495 TurnSgl_PedObj4_Cval_MPC "MPC_C17_Pkt";
BA_ "FlexKomSigName" SG_ 2432634495 TurnSgl_PedObj4_Cval_MPC "MPC_C17_Pkt";
BA_ "FlexKomSigLaenge" SG_ 2432634495 TurnSgl_PedObj4_Cval_MPC 64;
BA_ "FlexKomSigStartPos" SG_ 2432634495 TurnSgl_PedObj4_Cval_MPC 7;
BA_ "FlexKomSID" SG_ 2432634495 TurnSgl_PedObj4_Cval_MPC 100679834;
BA_ "GenSigStartValue" SG_ 2432634495 TurnSgl_PedObj4_Cval_MPC 7;
BA_ "FlexKomSigStartValue" SG_ 2432634495 TurnSgl_PedObj4_Cval_MPC "1BF0FFFFFFFFFFFFh";
BA_ "GenSigCycleTime" SG_ 2432634495 TurnSgl_PedObj4_Cval_MPC 50;
BA_ "GenSigSNA" SG_ 2432634495 LaneChgInd_PedObj4_Stat_MPC "3h";
BA_ "FlexKomIsMotorola" SG_ 2432634495 LaneChgInd_PedObj4_Stat_MPC 1;
BA_ "FlexKomComment" SG_ 2432634495 LaneChgInd_PedObj4_Stat_MPC "MPC_C17_Pkt";
BA_ "FlexKomSigName" SG_ 2432634495 LaneChgInd_PedObj4_Stat_MPC "MPC_C17_Pkt";
BA_ "FlexKomSigLaenge" SG_ 2432634495 LaneChgInd_PedObj4_Stat_MPC 64;
BA_ "FlexKomSigStartPos" SG_ 2432634495 LaneChgInd_PedObj4_Stat_MPC 7;
BA_ "FlexKomSID" SG_ 2432634495 LaneChgInd_PedObj4_Stat_MPC 100679834;
BA_ "GenSigStartValue" SG_ 2432634495 LaneChgInd_PedObj4_Stat_MPC 3;
BA_ "FlexKomSigStartValue" SG_ 2432634495 LaneChgInd_PedObj4_Stat_MPC "1BF0FFFFFFFFFFFFh";
BA_ "GenSigCycleTime" SG_ 2432634495 LaneChgInd_PedObj4_Stat_MPC 50;
BA_ "GenSigSNA" SG_ 2432634751 CRC_SG_MPC_C18_Pkt "1Bh";
BA_ "FlexKomIsMotorola" SG_ 2432634751 CRC_SG_MPC_C18_Pkt 1;
BA_ "FlexKomComment" SG_ 2432634751 CRC_SG_MPC_C18_Pkt "MPC_C18_Pkt";
BA_ "FlexKomSigName" SG_ 2432634751 CRC_SG_MPC_C18_Pkt "MPC_C18_Pkt";
BA_ "FlexKomSigLaenge" SG_ 2432634751 CRC_SG_MPC_C18_Pkt 64;
BA_ "FlexKomSigStartPos" SG_ 2432634751 CRC_SG_MPC_C18_Pkt 7;
BA_ "FlexKomSID" SG_ 2432634751 CRC_SG_MPC_C18_Pkt 100679837;
BA_ "GenSigStartValue" SG_ 2432634751 CRC_SG_MPC_C18_Pkt 27;
BA_ "FlexKomSigStartValue" SG_ 2432634751 CRC_SG_MPC_C18_Pkt "1BF0FFFFFFFFFFFFh";
BA_ "GenSigCycleTime" SG_ 2432634751 CRC_SG_MPC_C18_Pkt 50;
BA_ "GenSigSNA" SG_ 2432634751 SQC_SG_MPC_C18_Pkt "0h";
BA_ "FlexKomIsMotorola" SG_ 2432634751 SQC_SG_MPC_C18_Pkt 1;
BA_ "FlexKomComment" SG_ 2432634751 SQC_SG_MPC_C18_Pkt "MPC_C18_Pkt";
BA_ "FlexKomSigName" SG_ 2432634751 SQC_SG_MPC_C18_Pkt "MPC_C18_Pkt";
BA_ "FlexKomSigLaenge" SG_ 2432634751 SQC_SG_MPC_C18_Pkt 64;
BA_ "FlexKomSigStartPos" SG_ 2432634751 SQC_SG_MPC_C18_Pkt 7;
BA_ "FlexKomSID" SG_ 2432634751 SQC_SG_MPC_C18_Pkt 100679837;
BA_ "FlexKomSigStartValue" SG_ 2432634751 SQC_SG_MPC_C18_Pkt "1BF0FFFFFFFFFFFFh";
BA_ "GenSigCycleTime" SG_ 2432634751 SQC_SG_MPC_C18_Pkt 50;
BA_ "GenSigSNA" SG_ 2432634751 ClassPedObj5_Stat_MPC "Fh";
BA_ "FlexKomIsMotorola" SG_ 2432634751 ClassPedObj5_Stat_MPC 1;
BA_ "FlexKomComment" SG_ 2432634751 ClassPedObj5_Stat_MPC "MPC_C18_Pkt";
BA_ "FlexKomSigName" SG_ 2432634751 ClassPedObj5_Stat_MPC "MPC_C18_Pkt";
BA_ "FlexKomSigLaenge" SG_ 2432634751 ClassPedObj5_Stat_MPC 64;
BA_ "FlexKomSigStartPos" SG_ 2432634751 ClassPedObj5_Stat_MPC 7;
BA_ "FlexKomSID" SG_ 2432634751 ClassPedObj5_Stat_MPC 100679837;
BA_ "GenSigStartValue" SG_ 2432634751 ClassPedObj5_Stat_MPC 15;
BA_ "FlexKomSigStartValue" SG_ 2432634751 ClassPedObj5_Stat_MPC "1BF0FFFFFFFFFFFFh";
BA_ "GenSigCycleTime" SG_ 2432634751 ClassPedObj5_Stat_MPC 50;
BA_ "GenSigSNA" SG_ 2432634751 NumPedObj5_Cval_MPC "1Fh";
BA_ "FlexKomIsMotorola" SG_ 2432634751 NumPedObj5_Cval_MPC 1;
BA_ "FlexKomComment" SG_ 2432634751 NumPedObj5_Cval_MPC "MPC_C18_Pkt";
BA_ "FlexKomSigName" SG_ 2432634751 NumPedObj5_Cval_MPC "MPC_C18_Pkt";
BA_ "FlexKomSigLaenge" SG_ 2432634751 NumPedObj5_Cval_MPC 64;
BA_ "FlexKomSigStartPos" SG_ 2432634751 NumPedObj5_Cval_MPC 7;
BA_ "FlexKomSID" SG_ 2432634751 NumPedObj5_Cval_MPC 100679837;
BA_ "GenSigStartValue" SG_ 2432634751 NumPedObj5_Cval_MPC 31;
BA_ "FlexKomSigStartValue" SG_ 2432634751 NumPedObj5_Cval_MPC "1BF0FFFFFFFFFFFFh";
BA_ "GenSigCycleTime" SG_ 2432634751 NumPedObj5_Cval_MPC 50;
BA_ "GenSigSNA" SG_ 2432634751 TypePedObj5_Stat_MPC "7h";
BA_ "FlexKomIsMotorola" SG_ 2432634751 TypePedObj5_Stat_MPC 1;
BA_ "FlexKomComment" SG_ 2432634751 TypePedObj5_Stat_MPC "MPC_C18_Pkt";
BA_ "FlexKomSigName" SG_ 2432634751 TypePedObj5_Stat_MPC "MPC_C18_Pkt";
BA_ "FlexKomSigLaenge" SG_ 2432634751 TypePedObj5_Stat_MPC 64;
BA_ "FlexKomSigStartPos" SG_ 2432634751 TypePedObj5_Stat_MPC 7;
BA_ "FlexKomSID" SG_ 2432634751 TypePedObj5_Stat_MPC 100679837;
BA_ "GenSigStartValue" SG_ 2432634751 TypePedObj5_Stat_MPC 7;
BA_ "FlexKomSigStartValue" SG_ 2432634751 TypePedObj5_Stat_MPC "1BF0FFFFFFFFFFFFh";
BA_ "GenSigCycleTime" SG_ 2432634751 TypePedObj5_Stat_MPC 50;
BA_ "GenSigSNA" SG_ 2432634751 StdRng_X_PedObj5_Cval_MPC "3h";
BA_ "FlexKomIsMotorola" SG_ 2432634751 StdRng_X_PedObj5_Cval_MPC 1;
BA_ "FlexKomComment" SG_ 2432634751 StdRng_X_PedObj5_Cval_MPC "MPC_C18_Pkt";
BA_ "FlexKomSigName" SG_ 2432634751 StdRng_X_PedObj5_Cval_MPC "MPC_C18_Pkt";
BA_ "FlexKomSigLaenge" SG_ 2432634751 StdRng_X_PedObj5_Cval_MPC 64;
BA_ "FlexKomSigStartPos" SG_ 2432634751 StdRng_X_PedObj5_Cval_MPC 7;
BA_ "FlexKomSID" SG_ 2432634751 StdRng_X_PedObj5_Cval_MPC 100679837;
BA_ "GenSigStartValue" SG_ 2432634751 StdRng_X_PedObj5_Cval_MPC 3;
BA_ "FlexKomSigStartValue" SG_ 2432634751 StdRng_X_PedObj5_Cval_MPC "1BF0FFFFFFFFFFFFh";
BA_ "GenSigCycleTime" SG_ 2432634751 StdRng_X_PedObj5_Cval_MPC 50;
BA_ "GenSigSNA" SG_ 2432634751 StdRng_Y_PedObj5_Cval_MPC "3h";
BA_ "FlexKomIsMotorola" SG_ 2432634751 StdRng_Y_PedObj5_Cval_MPC 1;
BA_ "FlexKomComment" SG_ 2432634751 StdRng_Y_PedObj5_Cval_MPC "MPC_C18_Pkt";
BA_ "FlexKomSigName" SG_ 2432634751 StdRng_Y_PedObj5_Cval_MPC "MPC_C18_Pkt";
BA_ "FlexKomSigLaenge" SG_ 2432634751 StdRng_Y_PedObj5_Cval_MPC 64;
BA_ "FlexKomSigStartPos" SG_ 2432634751 StdRng_Y_PedObj5_Cval_MPC 7;
BA_ "FlexKomSID" SG_ 2432634751 StdRng_Y_PedObj5_Cval_MPC 100679837;
BA_ "GenSigStartValue" SG_ 2432634751 StdRng_Y_PedObj5_Cval_MPC 3;
BA_ "FlexKomSigStartValue" SG_ 2432634751 StdRng_Y_PedObj5_Cval_MPC "1BF0FFFFFFFFFFFFh";
BA_ "GenSigCycleTime" SG_ 2432634751 StdRng_Y_PedObj5_Cval_MPC 50;
BA_ "GenSigSNA" SG_ 2432634751 StdRng_Spd_X_PedObj5_Cval_MPC "3h";
BA_ "FlexKomIsMotorola" SG_ 2432634751 StdRng_Spd_X_PedObj5_Cval_MPC 1;
BA_ "FlexKomComment" SG_ 2432634751 StdRng_Spd_X_PedObj5_Cval_MPC "MPC_C18_Pkt";
BA_ "FlexKomSigName" SG_ 2432634751 StdRng_Spd_X_PedObj5_Cval_MPC "MPC_C18_Pkt";
BA_ "FlexKomSigLaenge" SG_ 2432634751 StdRng_Spd_X_PedObj5_Cval_MPC 64;
BA_ "FlexKomSigStartPos" SG_ 2432634751 StdRng_Spd_X_PedObj5_Cval_MPC 7;
BA_ "FlexKomSID" SG_ 2432634751 StdRng_Spd_X_PedObj5_Cval_MPC 100679837;
BA_ "GenSigStartValue" SG_ 2432634751 StdRng_Spd_X_PedObj5_Cval_MPC 3;
BA_ "FlexKomSigStartValue" SG_ 2432634751 StdRng_Spd_X_PedObj5_Cval_MPC "1BF0FFFFFFFFFFFFh";
BA_ "GenSigCycleTime" SG_ 2432634751 StdRng_Spd_X_PedObj5_Cval_MPC 50;
BA_ "GenSigSNA" SG_ 2432634751 StdRng_Spd_Y_PedObj5_Cval_MPC "3h";
BA_ "FlexKomIsMotorola" SG_ 2432634751 StdRng_Spd_Y_PedObj5_Cval_MPC 1;
BA_ "FlexKomComment" SG_ 2432634751 StdRng_Spd_Y_PedObj5_Cval_MPC "MPC_C18_Pkt";
BA_ "FlexKomSigName" SG_ 2432634751 StdRng_Spd_Y_PedObj5_Cval_MPC "MPC_C18_Pkt";
BA_ "FlexKomSigLaenge" SG_ 2432634751 StdRng_Spd_Y_PedObj5_Cval_MPC 64;
BA_ "FlexKomSigStartPos" SG_ 2432634751 StdRng_Spd_Y_PedObj5_Cval_MPC 7;
BA_ "FlexKomSID" SG_ 2432634751 StdRng_Spd_Y_PedObj5_Cval_MPC 100679837;
BA_ "GenSigStartValue" SG_ 2432634751 StdRng_Spd_Y_PedObj5_Cval_MPC 3;
BA_ "FlexKomSigStartValue" SG_ 2432634751 StdRng_Spd_Y_PedObj5_Cval_MPC "1BF0FFFFFFFFFFFFh";
BA_ "GenSigCycleTime" SG_ 2432634751 StdRng_Spd_Y_PedObj5_Cval_MPC 50;
BA_ "GenSigSNA" SG_ 2432634751 WidthPedObj5_Cval_MPC "FFh";
BA_ "FlexKomIsMotorola" SG_ 2432634751 WidthPedObj5_Cval_MPC 1;
BA_ "FlexKomComment" SG_ 2432634751 WidthPedObj5_Cval_MPC "MPC_C18_Pkt";
BA_ "FlexKomSigName" SG_ 2432634751 WidthPedObj5_Cval_MPC "MPC_C18_Pkt";
BA_ "FlexKomSigLaenge" SG_ 2432634751 WidthPedObj5_Cval_MPC 64;
BA_ "FlexKomSigStartPos" SG_ 2432634751 WidthPedObj5_Cval_MPC 7;
BA_ "FlexKomSID" SG_ 2432634751 WidthPedObj5_Cval_MPC 100679837;
BA_ "GenSigStartValue" SG_ 2432634751 WidthPedObj5_Cval_MPC 255;
BA_ "FlexKomSigStartValue" SG_ 2432634751 WidthPedObj5_Cval_MPC "1BF0FFFFFFFFFFFFh";
BA_ "GenSigCycleTime" SG_ 2432634751 WidthPedObj5_Cval_MPC 50;
BA_ "GenSigSNA" SG_ 2432634751 OLA_PedObj5_Cval_MPC "FFh";
BA_ "FlexKomIsMotorola" SG_ 2432634751 OLA_PedObj5_Cval_MPC 1;
BA_ "FlexKomComment" SG_ 2432634751 OLA_PedObj5_Cval_MPC "MPC_C18_Pkt";
BA_ "FlexKomSigName" SG_ 2432634751 OLA_PedObj5_Cval_MPC "MPC_C18_Pkt";
BA_ "FlexKomSigLaenge" SG_ 2432634751 OLA_PedObj5_Cval_MPC 64;
BA_ "FlexKomSigStartPos" SG_ 2432634751 OLA_PedObj5_Cval_MPC 7;
BA_ "FlexKomSID" SG_ 2432634751 OLA_PedObj5_Cval_MPC 100679837;
BA_ "GenSigStartValue" SG_ 2432634751 OLA_PedObj5_Cval_MPC 255;
BA_ "FlexKomSigStartValue" SG_ 2432634751 OLA_PedObj5_Cval_MPC "1BF0FFFFFFFFFFFFh";
BA_ "GenSigCycleTime" SG_ 2432634751 OLA_PedObj5_Cval_MPC 50;
BA_ "GenSigSNA" SG_ 2432634751 HeightPedObj5_Cval_MPC "FFh";
BA_ "FlexKomIsMotorola" SG_ 2432634751 HeightPedObj5_Cval_MPC 1;
BA_ "FlexKomComment" SG_ 2432634751 HeightPedObj5_Cval_MPC "MPC_C18_Pkt";
BA_ "FlexKomSigName" SG_ 2432634751 HeightPedObj5_Cval_MPC "MPC_C18_Pkt";
BA_ "FlexKomSigLaenge" SG_ 2432634751 HeightPedObj5_Cval_MPC 64;
BA_ "FlexKomSigStartPos" SG_ 2432634751 HeightPedObj5_Cval_MPC 7;
BA_ "FlexKomSID" SG_ 2432634751 HeightPedObj5_Cval_MPC 100679837;
BA_ "GenSigStartValue" SG_ 2432634751 HeightPedObj5_Cval_MPC 255;
BA_ "FlexKomSigStartValue" SG_ 2432634751 HeightPedObj5_Cval_MPC "1BF0FFFFFFFFFFFFh";
BA_ "GenSigCycleTime" SG_ 2432634751 HeightPedObj5_Cval_MPC 50;
BA_ "GenSigSNA" SG_ 2432634751 LaneAlloc_PedObj5_Cval_MPC "7h";
BA_ "FlexKomIsMotorola" SG_ 2432634751 LaneAlloc_PedObj5_Cval_MPC 1;
BA_ "FlexKomComment" SG_ 2432634751 LaneAlloc_PedObj5_Cval_MPC "MPC_C18_Pkt";
BA_ "FlexKomSigName" SG_ 2432634751 LaneAlloc_PedObj5_Cval_MPC "MPC_C18_Pkt";
BA_ "FlexKomSigLaenge" SG_ 2432634751 LaneAlloc_PedObj5_Cval_MPC 64;
BA_ "FlexKomSigStartPos" SG_ 2432634751 LaneAlloc_PedObj5_Cval_MPC 7;
BA_ "FlexKomSID" SG_ 2432634751 LaneAlloc_PedObj5_Cval_MPC 100679837;
BA_ "GenSigStartValue" SG_ 2432634751 LaneAlloc_PedObj5_Cval_MPC 7;
BA_ "FlexKomSigStartValue" SG_ 2432634751 LaneAlloc_PedObj5_Cval_MPC "1BF0FFFFFFFFFFFFh";
BA_ "GenSigCycleTime" SG_ 2432634751 LaneAlloc_PedObj5_Cval_MPC 50;
BA_ "GenSigSNA" SG_ 2432634751 TurnSgl_PedObj5_Cval_MPC "7h";
BA_ "FlexKomIsMotorola" SG_ 2432634751 TurnSgl_PedObj5_Cval_MPC 1;
BA_ "FlexKomComment" SG_ 2432634751 TurnSgl_PedObj5_Cval_MPC "MPC_C18_Pkt";
BA_ "FlexKomSigName" SG_ 2432634751 TurnSgl_PedObj5_Cval_MPC "MPC_C18_Pkt";
BA_ "FlexKomSigLaenge" SG_ 2432634751 TurnSgl_PedObj5_Cval_MPC 64;
BA_ "FlexKomSigStartPos" SG_ 2432634751 TurnSgl_PedObj5_Cval_MPC 7;
BA_ "FlexKomSID" SG_ 2432634751 TurnSgl_PedObj5_Cval_MPC 100679837;
BA_ "GenSigStartValue" SG_ 2432634751 TurnSgl_PedObj5_Cval_MPC 7;
BA_ "FlexKomSigStartValue" SG_ 2432634751 TurnSgl_PedObj5_Cval_MPC "1BF0FFFFFFFFFFFFh";
BA_ "GenSigCycleTime" SG_ 2432634751 TurnSgl_PedObj5_Cval_MPC 50;
BA_ "GenSigSNA" SG_ 2432634751 LaneChgInd_PedObj5_Stat_MPC "3h";
BA_ "FlexKomIsMotorola" SG_ 2432634751 LaneChgInd_PedObj5_Stat_MPC 1;
BA_ "FlexKomComment" SG_ 2432634751 LaneChgInd_PedObj5_Stat_MPC "MPC_C18_Pkt";
BA_ "FlexKomSigName" SG_ 2432634751 LaneChgInd_PedObj5_Stat_MPC "MPC_C18_Pkt";
BA_ "FlexKomSigLaenge" SG_ 2432634751 LaneChgInd_PedObj5_Stat_MPC 64;
BA_ "FlexKomSigStartPos" SG_ 2432634751 LaneChgInd_PedObj5_Stat_MPC 7;
BA_ "FlexKomSID" SG_ 2432634751 LaneChgInd_PedObj5_Stat_MPC 100679837;
BA_ "GenSigStartValue" SG_ 2432634751 LaneChgInd_PedObj5_Stat_MPC 3;
BA_ "FlexKomSigStartValue" SG_ 2432634751 LaneChgInd_PedObj5_Stat_MPC "1BF0FFFFFFFFFFFFh";
BA_ "GenSigCycleTime" SG_ 2432634751 LaneChgInd_PedObj5_Stat_MPC 50;
BA_ "GenSigSNA" SG_ 2432635007 CRC_SG_MPC_C19_Pkt "74h";
BA_ "FlexKomIsMotorola" SG_ 2432635007 CRC_SG_MPC_C19_Pkt 1;
BA_ "FlexKomComment" SG_ 2432635007 CRC_SG_MPC_C19_Pkt "MPC_C19_Pkt";
BA_ "FlexKomSigName" SG_ 2432635007 CRC_SG_MPC_C19_Pkt "MPC_C19_Pkt";
BA_ "FlexKomSigLaenge" SG_ 2432635007 CRC_SG_MPC_C19_Pkt 64;
BA_ "FlexKomSigStartPos" SG_ 2432635007 CRC_SG_MPC_C19_Pkt 7;
BA_ "FlexKomSID" SG_ 2432635007 CRC_SG_MPC_C19_Pkt 100679839;
BA_ "GenSigStartValue" SG_ 2432635007 CRC_SG_MPC_C19_Pkt 116;
BA_ "FlexKomSigStartValue" SG_ 2432635007 CRC_SG_MPC_C19_Pkt "74F0FFFFFFFFFFFFh";
BA_ "GenSigCycleTime" SG_ 2432635007 CRC_SG_MPC_C19_Pkt 50;
BA_ "GenSigSNA" SG_ 2432635007 SQC_SG_MPC_C19_Pkt "0h";
BA_ "FlexKomIsMotorola" SG_ 2432635007 SQC_SG_MPC_C19_Pkt 1;
BA_ "FlexKomComment" SG_ 2432635007 SQC_SG_MPC_C19_Pkt "MPC_C19_Pkt";
BA_ "FlexKomSigName" SG_ 2432635007 SQC_SG_MPC_C19_Pkt "MPC_C19_Pkt";
BA_ "FlexKomSigLaenge" SG_ 2432635007 SQC_SG_MPC_C19_Pkt 64;
BA_ "FlexKomSigStartPos" SG_ 2432635007 SQC_SG_MPC_C19_Pkt 7;
BA_ "FlexKomSID" SG_ 2432635007 SQC_SG_MPC_C19_Pkt 100679839;
BA_ "FlexKomSigStartValue" SG_ 2432635007 SQC_SG_MPC_C19_Pkt "74F0FFFFFFFFFFFFh";
BA_ "GenSigCycleTime" SG_ 2432635007 SQC_SG_MPC_C19_Pkt 50;
BA_ "GenSigSNA" SG_ 2432635007 ConfLvl_VehObj0_Cval "3h";
BA_ "FlexKomIsMotorola" SG_ 2432635007 ConfLvl_VehObj0_Cval 1;
BA_ "FlexKomComment" SG_ 2432635007 ConfLvl_VehObj0_Cval "MPC_C19_Pkt";
BA_ "FlexKomSigName" SG_ 2432635007 ConfLvl_VehObj0_Cval "MPC_C19_Pkt";
BA_ "FlexKomSigLaenge" SG_ 2432635007 ConfLvl_VehObj0_Cval 64;
BA_ "FlexKomSigStartPos" SG_ 2432635007 ConfLvl_VehObj0_Cval 7;
BA_ "FlexKomSID" SG_ 2432635007 ConfLvl_VehObj0_Cval 100679839;
BA_ "GenSigStartValue" SG_ 2432635007 ConfLvl_VehObj0_Cval 3;
BA_ "FlexKomSigStartValue" SG_ 2432635007 ConfLvl_VehObj0_Cval "74F0FFFFFFFFFFFFh";
BA_ "GenSigCycleTime" SG_ 2432635007 ConfLvl_VehObj0_Cval 50;
BA_ "GenSigSNA" SG_ 2432635007 DtctStat_VehObj0_MPC "3h";
BA_ "FlexKomIsMotorola" SG_ 2432635007 DtctStat_VehObj0_MPC 1;
BA_ "FlexKomComment" SG_ 2432635007 DtctStat_VehObj0_MPC "MPC_C19_Pkt";
BA_ "FlexKomSigName" SG_ 2432635007 DtctStat_VehObj0_MPC "MPC_C19_Pkt";
BA_ "FlexKomSigLaenge" SG_ 2432635007 DtctStat_VehObj0_MPC 64;
BA_ "FlexKomSigStartPos" SG_ 2432635007 DtctStat_VehObj0_MPC 7;
BA_ "FlexKomSID" SG_ 2432635007 DtctStat_VehObj0_MPC 100679839;
BA_ "GenSigStartValue" SG_ 2432635007 DtctStat_VehObj0_MPC 3;
BA_ "FlexKomSigStartValue" SG_ 2432635007 DtctStat_VehObj0_MPC "74F0FFFFFFFFFFFFh";
BA_ "GenSigCycleTime" SG_ 2432635007 DtctStat_VehObj0_MPC 50;
BA_ "GenSigSNA" SG_ 2432635007 Spd_X_VehObj0_Cval "FFh";
BA_ "FlexKomIsMotorola" SG_ 2432635007 Spd_X_VehObj0_Cval 1;
BA_ "FlexKomComment" SG_ 2432635007 Spd_X_VehObj0_Cval "MPC_C19_Pkt";
BA_ "FlexKomSigName" SG_ 2432635007 Spd_X_VehObj0_Cval "MPC_C19_Pkt";
BA_ "FlexKomSigLaenge" SG_ 2432635007 Spd_X_VehObj0_Cval 64;
BA_ "FlexKomSigStartPos" SG_ 2432635007 Spd_X_VehObj0_Cval 7;
BA_ "FlexKomSID" SG_ 2432635007 Spd_X_VehObj0_Cval 100679839;
BA_ "GenSigStartValue" SG_ 2432635007 Spd_X_VehObj0_Cval 255;
BA_ "FlexKomSigStartValue" SG_ 2432635007 Spd_X_VehObj0_Cval "74F0FFFFFFFFFFFFh";
BA_ "GenSigCycleTime" SG_ 2432635007 Spd_X_VehObj0_Cval 50;
BA_ "GenSigSNA" SG_ 2432635007 Spd_Y_VehObj0_Cval "FFh";
BA_ "FlexKomIsMotorola" SG_ 2432635007 Spd_Y_VehObj0_Cval 1;
BA_ "FlexKomComment" SG_ 2432635007 Spd_Y_VehObj0_Cval "MPC_C19_Pkt";
BA_ "FlexKomSigName" SG_ 2432635007 Spd_Y_VehObj0_Cval "MPC_C19_Pkt";
BA_ "FlexKomSigLaenge" SG_ 2432635007 Spd_Y_VehObj0_Cval 64;
BA_ "FlexKomSigStartPos" SG_ 2432635007 Spd_Y_VehObj0_Cval 7;
BA_ "FlexKomSID" SG_ 2432635007 Spd_Y_VehObj0_Cval 100679839;
BA_ "GenSigStartValue" SG_ 2432635007 Spd_Y_VehObj0_Cval 255;
BA_ "FlexKomSigStartValue" SG_ 2432635007 Spd_Y_VehObj0_Cval "74F0FFFFFFFFFFFFh";
BA_ "GenSigCycleTime" SG_ 2432635007 Spd_Y_VehObj0_Cval 50;
BA_ "GenSigSNA" SG_ 2432635007 Dist_X_VehObj0_Cval_MPC "FFFFh";
BA_ "FlexKomIsMotorola" SG_ 2432635007 Dist_X_VehObj0_Cval_MPC 1;
BA_ "FlexKomComment" SG_ 2432635007 Dist_X_VehObj0_Cval_MPC "MPC_C19_Pkt";
BA_ "FlexKomSigName" SG_ 2432635007 Dist_X_VehObj0_Cval_MPC "MPC_C19_Pkt";
BA_ "FlexKomSigLaenge" SG_ 2432635007 Dist_X_VehObj0_Cval_MPC 64;
BA_ "FlexKomSigStartPos" SG_ 2432635007 Dist_X_VehObj0_Cval_MPC 7;
BA_ "FlexKomSID" SG_ 2432635007 Dist_X_VehObj0_Cval_MPC 100679839;
BA_ "GenSigStartValue" SG_ 2432635007 Dist_X_VehObj0_Cval_MPC 65535;
BA_ "FlexKomSigStartValue" SG_ 2432635007 Dist_X_VehObj0_Cval_MPC "74F0FFFFFFFFFFFFh";
BA_ "GenSigCycleTime" SG_ 2432635007 Dist_X_VehObj0_Cval_MPC 50;
BA_ "GenSigSNA" SG_ 2432635007 Dist_Y_VehObj0_Cval_MPC "FFFFh";
BA_ "FlexKomIsMotorola" SG_ 2432635007 Dist_Y_VehObj0_Cval_MPC 1;
BA_ "FlexKomComment" SG_ 2432635007 Dist_Y_VehObj0_Cval_MPC "MPC_C19_Pkt";
BA_ "FlexKomSigName" SG_ 2432635007 Dist_Y_VehObj0_Cval_MPC "MPC_C19_Pkt";
BA_ "FlexKomSigLaenge" SG_ 2432635007 Dist_Y_VehObj0_Cval_MPC 64;
BA_ "FlexKomSigStartPos" SG_ 2432635007 Dist_Y_VehObj0_Cval_MPC 7;
BA_ "FlexKomSID" SG_ 2432635007 Dist_Y_VehObj0_Cval_MPC 100679839;
BA_ "GenSigStartValue" SG_ 2432635007 Dist_Y_VehObj0_Cval_MPC 65535;
BA_ "FlexKomSigStartValue" SG_ 2432635007 Dist_Y_VehObj0_Cval_MPC "74F0FFFFFFFFFFFFh";
BA_ "GenSigCycleTime" SG_ 2432635007 Dist_Y_VehObj0_Cval_MPC 50;
BA_ "GenSigSNA" SG_ 2432635263 CRC_SG_MPC_C20_Pkt "9Eh";
BA_ "FlexKomIsMotorola" SG_ 2432635263 CRC_SG_MPC_C20_Pkt 1;
BA_ "FlexKomComment" SG_ 2432635263 CRC_SG_MPC_C20_Pkt "MPC_C20_Pkt";
BA_ "FlexKomSigName" SG_ 2432635263 CRC_SG_MPC_C20_Pkt "MPC_C20_Pkt";
BA_ "FlexKomSigLaenge" SG_ 2432635263 CRC_SG_MPC_C20_Pkt 64;
BA_ "FlexKomSigStartPos" SG_ 2432635263 CRC_SG_MPC_C20_Pkt 7;
BA_ "FlexKomSID" SG_ 2432635263 CRC_SG_MPC_C20_Pkt 100679842;
BA_ "GenSigStartValue" SG_ 2432635263 CRC_SG_MPC_C20_Pkt 158;
BA_ "FlexKomSigStartValue" SG_ 2432635263 CRC_SG_MPC_C20_Pkt "9EF0FFFFFFFFFFFFh";
BA_ "GenSigCycleTime" SG_ 2432635263 CRC_SG_MPC_C20_Pkt 50;
BA_ "GenSigSNA" SG_ 2432635263 SQC_SG_MPC_C20_Pkt "0h";
BA_ "FlexKomIsMotorola" SG_ 2432635263 SQC_SG_MPC_C20_Pkt 1;
BA_ "FlexKomComment" SG_ 2432635263 SQC_SG_MPC_C20_Pkt "MPC_C20_Pkt";
BA_ "FlexKomSigName" SG_ 2432635263 SQC_SG_MPC_C20_Pkt "MPC_C20_Pkt";
BA_ "FlexKomSigLaenge" SG_ 2432635263 SQC_SG_MPC_C20_Pkt 64;
BA_ "FlexKomSigStartPos" SG_ 2432635263 SQC_SG_MPC_C20_Pkt 7;
BA_ "FlexKomSID" SG_ 2432635263 SQC_SG_MPC_C20_Pkt 100679842;
BA_ "FlexKomSigStartValue" SG_ 2432635263 SQC_SG_MPC_C20_Pkt "9EF0FFFFFFFFFFFFh";
BA_ "GenSigCycleTime" SG_ 2432635263 SQC_SG_MPC_C20_Pkt 50;
BA_ "GenSigSNA" SG_ 2432635263 ConfLvl_VehObj1_Cval "3h";
BA_ "FlexKomIsMotorola" SG_ 2432635263 ConfLvl_VehObj1_Cval 1;
BA_ "FlexKomComment" SG_ 2432635263 ConfLvl_VehObj1_Cval "MPC_C20_Pkt";
BA_ "FlexKomSigName" SG_ 2432635263 ConfLvl_VehObj1_Cval "MPC_C20_Pkt";
BA_ "FlexKomSigLaenge" SG_ 2432635263 ConfLvl_VehObj1_Cval 64;
BA_ "FlexKomSigStartPos" SG_ 2432635263 ConfLvl_VehObj1_Cval 7;
BA_ "FlexKomSID" SG_ 2432635263 ConfLvl_VehObj1_Cval 100679842;
BA_ "GenSigStartValue" SG_ 2432635263 ConfLvl_VehObj1_Cval 3;
BA_ "FlexKomSigStartValue" SG_ 2432635263 ConfLvl_VehObj1_Cval "9EF0FFFFFFFFFFFFh";
BA_ "GenSigCycleTime" SG_ 2432635263 ConfLvl_VehObj1_Cval 50;
BA_ "GenSigSNA" SG_ 2432635263 DtctStat_VehObj1_MPC "3h";
BA_ "FlexKomIsMotorola" SG_ 2432635263 DtctStat_VehObj1_MPC 1;
BA_ "FlexKomComment" SG_ 2432635263 DtctStat_VehObj1_MPC "MPC_C20_Pkt";
BA_ "FlexKomSigName" SG_ 2432635263 DtctStat_VehObj1_MPC "MPC_C20_Pkt";
BA_ "FlexKomSigLaenge" SG_ 2432635263 DtctStat_VehObj1_MPC 64;
BA_ "FlexKomSigStartPos" SG_ 2432635263 DtctStat_VehObj1_MPC 7;
BA_ "FlexKomSID" SG_ 2432635263 DtctStat_VehObj1_MPC 100679842;
BA_ "GenSigStartValue" SG_ 2432635263 DtctStat_VehObj1_MPC 3;
BA_ "FlexKomSigStartValue" SG_ 2432635263 DtctStat_VehObj1_MPC "9EF0FFFFFFFFFFFFh";
BA_ "GenSigCycleTime" SG_ 2432635263 DtctStat_VehObj1_MPC 50;
BA_ "GenSigSNA" SG_ 2432635263 Spd_X_VehObj1_Cval "FFh";
BA_ "FlexKomIsMotorola" SG_ 2432635263 Spd_X_VehObj1_Cval 1;
BA_ "FlexKomComment" SG_ 2432635263 Spd_X_VehObj1_Cval "MPC_C20_Pkt";
BA_ "FlexKomSigName" SG_ 2432635263 Spd_X_VehObj1_Cval "MPC_C20_Pkt";
BA_ "FlexKomSigLaenge" SG_ 2432635263 Spd_X_VehObj1_Cval 64;
BA_ "FlexKomSigStartPos" SG_ 2432635263 Spd_X_VehObj1_Cval 7;
BA_ "FlexKomSID" SG_ 2432635263 Spd_X_VehObj1_Cval 100679842;
BA_ "GenSigStartValue" SG_ 2432635263 Spd_X_VehObj1_Cval 255;
BA_ "FlexKomSigStartValue" SG_ 2432635263 Spd_X_VehObj1_Cval "9EF0FFFFFFFFFFFFh";
BA_ "GenSigCycleTime" SG_ 2432635263 Spd_X_VehObj1_Cval 50;
BA_ "GenSigSNA" SG_ 2432635263 Spd_Y_VehObj1_Cval "FFh";
BA_ "FlexKomIsMotorola" SG_ 2432635263 Spd_Y_VehObj1_Cval 1;
BA_ "FlexKomComment" SG_ 2432635263 Spd_Y_VehObj1_Cval "MPC_C20_Pkt";
BA_ "FlexKomSigName" SG_ 2432635263 Spd_Y_VehObj1_Cval "MPC_C20_Pkt";
BA_ "FlexKomSigLaenge" SG_ 2432635263 Spd_Y_VehObj1_Cval 64;
BA_ "FlexKomSigStartPos" SG_ 2432635263 Spd_Y_VehObj1_Cval 7;
BA_ "FlexKomSID" SG_ 2432635263 Spd_Y_VehObj1_Cval 100679842;
BA_ "GenSigStartValue" SG_ 2432635263 Spd_Y_VehObj1_Cval 255;
BA_ "FlexKomSigStartValue" SG_ 2432635263 Spd_Y_VehObj1_Cval "9EF0FFFFFFFFFFFFh";
BA_ "GenSigCycleTime" SG_ 2432635263 Spd_Y_VehObj1_Cval 50;
BA_ "GenSigSNA" SG_ 2432635263 Dist_X_VehObj1_Cval_MPC "FFFFh";
BA_ "FlexKomIsMotorola" SG_ 2432635263 Dist_X_VehObj1_Cval_MPC 1;
BA_ "FlexKomComment" SG_ 2432635263 Dist_X_VehObj1_Cval_MPC "MPC_C20_Pkt";
BA_ "FlexKomSigName" SG_ 2432635263 Dist_X_VehObj1_Cval_MPC "MPC_C20_Pkt";
BA_ "FlexKomSigLaenge" SG_ 2432635263 Dist_X_VehObj1_Cval_MPC 64;
BA_ "FlexKomSigStartPos" SG_ 2432635263 Dist_X_VehObj1_Cval_MPC 7;
BA_ "FlexKomSID" SG_ 2432635263 Dist_X_VehObj1_Cval_MPC 100679842;
BA_ "GenSigStartValue" SG_ 2432635263 Dist_X_VehObj1_Cval_MPC 65535;
BA_ "FlexKomSigStartValue" SG_ 2432635263 Dist_X_VehObj1_Cval_MPC "9EF0FFFFFFFFFFFFh";
BA_ "GenSigCycleTime" SG_ 2432635263 Dist_X_VehObj1_Cval_MPC 50;
BA_ "GenSigSNA" SG_ 2432635263 Dist_Y_VehObj1_Cval_MPC "FFFFh";
BA_ "FlexKomIsMotorola" SG_ 2432635263 Dist_Y_VehObj1_Cval_MPC 1;
BA_ "FlexKomComment" SG_ 2432635263 Dist_Y_VehObj1_Cval_MPC "MPC_C20_Pkt";
BA_ "FlexKomSigName" SG_ 2432635263 Dist_Y_VehObj1_Cval_MPC "MPC_C20_Pkt";
BA_ "FlexKomSigLaenge" SG_ 2432635263 Dist_Y_VehObj1_Cval_MPC 64;
BA_ "FlexKomSigStartPos" SG_ 2432635263 Dist_Y_VehObj1_Cval_MPC 7;
BA_ "FlexKomSID" SG_ 2432635263 Dist_Y_VehObj1_Cval_MPC 100679842;
BA_ "GenSigStartValue" SG_ 2432635263 Dist_Y_VehObj1_Cval_MPC 65535;
BA_ "FlexKomSigStartValue" SG_ 2432635263 Dist_Y_VehObj1_Cval_MPC "9EF0FFFFFFFFFFFFh";
BA_ "GenSigCycleTime" SG_ 2432635263 Dist_Y_VehObj1_Cval_MPC 50;
BA_ "GenSigSNA" SG_ 2432635519 CRC_SG_MPC_C21_Pkt "60h";
BA_ "FlexKomIsMotorola" SG_ 2432635519 CRC_SG_MPC_C21_Pkt 1;
BA_ "FlexKomComment" SG_ 2432635519 CRC_SG_MPC_C21_Pkt "MPC_C21_Pkt";
BA_ "FlexKomSigName" SG_ 2432635519 CRC_SG_MPC_C21_Pkt "MPC_C21_Pkt";
BA_ "FlexKomSigLaenge" SG_ 2432635519 CRC_SG_MPC_C21_Pkt 64;
BA_ "FlexKomSigStartPos" SG_ 2432635519 CRC_SG_MPC_C21_Pkt 7;
BA_ "FlexKomSID" SG_ 2432635519 CRC_SG_MPC_C21_Pkt 100679843;
BA_ "GenSigStartValue" SG_ 2432635519 CRC_SG_MPC_C21_Pkt 96;
BA_ "FlexKomSigStartValue" SG_ 2432635519 CRC_SG_MPC_C21_Pkt "60F0FFFFFFFFFFFFh";
BA_ "GenSigCycleTime" SG_ 2432635519 CRC_SG_MPC_C21_Pkt 50;
BA_ "GenSigSNA" SG_ 2432635519 SQC_SG_MPC_C21_Pkt "0h";
BA_ "FlexKomIsMotorola" SG_ 2432635519 SQC_SG_MPC_C21_Pkt 1;
BA_ "FlexKomComment" SG_ 2432635519 SQC_SG_MPC_C21_Pkt "MPC_C21_Pkt";
BA_ "FlexKomSigName" SG_ 2432635519 SQC_SG_MPC_C21_Pkt "MPC_C21_Pkt";
BA_ "FlexKomSigLaenge" SG_ 2432635519 SQC_SG_MPC_C21_Pkt 64;
BA_ "FlexKomSigStartPos" SG_ 2432635519 SQC_SG_MPC_C21_Pkt 7;
BA_ "FlexKomSID" SG_ 2432635519 SQC_SG_MPC_C21_Pkt 100679843;
BA_ "FlexKomSigStartValue" SG_ 2432635519 SQC_SG_MPC_C21_Pkt "60F0FFFFFFFFFFFFh";
BA_ "GenSigCycleTime" SG_ 2432635519 SQC_SG_MPC_C21_Pkt 50;
BA_ "GenSigSNA" SG_ 2432635519 ConfLvl_VehObj2_Cval "3h";
BA_ "FlexKomIsMotorola" SG_ 2432635519 ConfLvl_VehObj2_Cval 1;
BA_ "FlexKomComment" SG_ 2432635519 ConfLvl_VehObj2_Cval "MPC_C21_Pkt";
BA_ "FlexKomSigName" SG_ 2432635519 ConfLvl_VehObj2_Cval "MPC_C21_Pkt";
BA_ "FlexKomSigLaenge" SG_ 2432635519 ConfLvl_VehObj2_Cval 64;
BA_ "FlexKomSigStartPos" SG_ 2432635519 ConfLvl_VehObj2_Cval 7;
BA_ "FlexKomSID" SG_ 2432635519 ConfLvl_VehObj2_Cval 100679843;
BA_ "GenSigStartValue" SG_ 2432635519 ConfLvl_VehObj2_Cval 3;
BA_ "FlexKomSigStartValue" SG_ 2432635519 ConfLvl_VehObj2_Cval "60F0FFFFFFFFFFFFh";
BA_ "GenSigCycleTime" SG_ 2432635519 ConfLvl_VehObj2_Cval 50;
BA_ "GenSigSNA" SG_ 2432635519 DtctStat_VehObj2_MPC "3h";
BA_ "FlexKomIsMotorola" SG_ 2432635519 DtctStat_VehObj2_MPC 1;
BA_ "FlexKomComment" SG_ 2432635519 DtctStat_VehObj2_MPC "MPC_C21_Pkt";
BA_ "FlexKomSigName" SG_ 2432635519 DtctStat_VehObj2_MPC "MPC_C21_Pkt";
BA_ "FlexKomSigLaenge" SG_ 2432635519 DtctStat_VehObj2_MPC 64;
BA_ "FlexKomSigStartPos" SG_ 2432635519 DtctStat_VehObj2_MPC 7;
BA_ "FlexKomSID" SG_ 2432635519 DtctStat_VehObj2_MPC 100679843;
BA_ "GenSigStartValue" SG_ 2432635519 DtctStat_VehObj2_MPC 3;
BA_ "FlexKomSigStartValue" SG_ 2432635519 DtctStat_VehObj2_MPC "60F0FFFFFFFFFFFFh";
BA_ "GenSigCycleTime" SG_ 2432635519 DtctStat_VehObj2_MPC 50;
BA_ "GenSigSNA" SG_ 2432635519 Spd_X_VehObj2_Cval "FFh";
BA_ "FlexKomIsMotorola" SG_ 2432635519 Spd_X_VehObj2_Cval 1;
BA_ "FlexKomComment" SG_ 2432635519 Spd_X_VehObj2_Cval "MPC_C21_Pkt";
BA_ "FlexKomSigName" SG_ 2432635519 Spd_X_VehObj2_Cval "MPC_C21_Pkt";
BA_ "FlexKomSigLaenge" SG_ 2432635519 Spd_X_VehObj2_Cval 64;
BA_ "FlexKomSigStartPos" SG_ 2432635519 Spd_X_VehObj2_Cval 7;
BA_ "FlexKomSID" SG_ 2432635519 Spd_X_VehObj2_Cval 100679843;
BA_ "GenSigStartValue" SG_ 2432635519 Spd_X_VehObj2_Cval 255;
BA_ "FlexKomSigStartValue" SG_ 2432635519 Spd_X_VehObj2_Cval "60F0FFFFFFFFFFFFh";
BA_ "GenSigCycleTime" SG_ 2432635519 Spd_X_VehObj2_Cval 50;
BA_ "GenSigSNA" SG_ 2432635519 Spd_Y_VehObj2_Cval "FFh";
BA_ "FlexKomIsMotorola" SG_ 2432635519 Spd_Y_VehObj2_Cval 1;
BA_ "FlexKomComment" SG_ 2432635519 Spd_Y_VehObj2_Cval "MPC_C21_Pkt";
BA_ "FlexKomSigName" SG_ 2432635519 Spd_Y_VehObj2_Cval "MPC_C21_Pkt";
BA_ "FlexKomSigLaenge" SG_ 2432635519 Spd_Y_VehObj2_Cval 64;
BA_ "FlexKomSigStartPos" SG_ 2432635519 Spd_Y_VehObj2_Cval 7;
BA_ "FlexKomSID" SG_ 2432635519 Spd_Y_VehObj2_Cval 100679843;
BA_ "GenSigStartValue" SG_ 2432635519 Spd_Y_VehObj2_Cval 255;
BA_ "FlexKomSigStartValue" SG_ 2432635519 Spd_Y_VehObj2_Cval "60F0FFFFFFFFFFFFh";
BA_ "GenSigCycleTime" SG_ 2432635519 Spd_Y_VehObj2_Cval 50;
BA_ "GenSigSNA" SG_ 2432635519 Dist_X_VehObj2_Cval_MPC "FFFFh";
BA_ "FlexKomIsMotorola" SG_ 2432635519 Dist_X_VehObj2_Cval_MPC 1;
BA_ "FlexKomComment" SG_ 2432635519 Dist_X_VehObj2_Cval_MPC "MPC_C21_Pkt";
BA_ "FlexKomSigName" SG_ 2432635519 Dist_X_VehObj2_Cval_MPC "MPC_C21_Pkt";
BA_ "FlexKomSigLaenge" SG_ 2432635519 Dist_X_VehObj2_Cval_MPC 64;
BA_ "FlexKomSigStartPos" SG_ 2432635519 Dist_X_VehObj2_Cval_MPC 7;
BA_ "FlexKomSID" SG_ 2432635519 Dist_X_VehObj2_Cval_MPC 100679843;
BA_ "GenSigStartValue" SG_ 2432635519 Dist_X_VehObj2_Cval_MPC 65535;
BA_ "FlexKomSigStartValue" SG_ 2432635519 Dist_X_VehObj2_Cval_MPC "60F0FFFFFFFFFFFFh";
BA_ "GenSigCycleTime" SG_ 2432635519 Dist_X_VehObj2_Cval_MPC 50;
BA_ "GenSigSNA" SG_ 2432635519 Dist_Y_VehObj2_Cval_MPC "FFFFh";
BA_ "FlexKomIsMotorola" SG_ 2432635519 Dist_Y_VehObj2_Cval_MPC 1;
BA_ "FlexKomComment" SG_ 2432635519 Dist_Y_VehObj2_Cval_MPC "MPC_C21_Pkt";
BA_ "FlexKomSigName" SG_ 2432635519 Dist_Y_VehObj2_Cval_MPC "MPC_C21_Pkt";
BA_ "FlexKomSigLaenge" SG_ 2432635519 Dist_Y_VehObj2_Cval_MPC 64;
BA_ "FlexKomSigStartPos" SG_ 2432635519 Dist_Y_VehObj2_Cval_MPC 7;
BA_ "FlexKomSID" SG_ 2432635519 Dist_Y_VehObj2_Cval_MPC 100679843;
BA_ "GenSigStartValue" SG_ 2432635519 Dist_Y_VehObj2_Cval_MPC 65535;
BA_ "FlexKomSigStartValue" SG_ 2432635519 Dist_Y_VehObj2_Cval_MPC "60F0FFFFFFFFFFFFh";
BA_ "GenSigCycleTime" SG_ 2432635519 Dist_Y_VehObj2_Cval_MPC 50;
BA_ "GenSigSNA" SG_ 2432635775 CRC_SG_MPC_C22_Pkt "Dh";
BA_ "FlexKomIsMotorola" SG_ 2432635775 CRC_SG_MPC_C22_Pkt 1;
BA_ "FlexKomComment" SG_ 2432635775 CRC_SG_MPC_C22_Pkt "MPC_C22_Pkt";
BA_ "FlexKomSigName" SG_ 2432635775 CRC_SG_MPC_C22_Pkt "MPC_C22_Pkt";
BA_ "FlexKomSigLaenge" SG_ 2432635775 CRC_SG_MPC_C22_Pkt 64;
BA_ "FlexKomSigStartPos" SG_ 2432635775 CRC_SG_MPC_C22_Pkt 7;
BA_ "FlexKomSID" SG_ 2432635775 CRC_SG_MPC_C22_Pkt 100679844;
BA_ "GenSigStartValue" SG_ 2432635775 CRC_SG_MPC_C22_Pkt 13;
BA_ "FlexKomSigStartValue" SG_ 2432635775 CRC_SG_MPC_C22_Pkt "0DF0FFFFFFFFFFFFh";
BA_ "GenSigCycleTime" SG_ 2432635775 CRC_SG_MPC_C22_Pkt 50;
BA_ "GenSigSNA" SG_ 2432635775 SQC_SG_MPC_C22_Pkt "0h";
BA_ "FlexKomIsMotorola" SG_ 2432635775 SQC_SG_MPC_C22_Pkt 1;
BA_ "FlexKomComment" SG_ 2432635775 SQC_SG_MPC_C22_Pkt "MPC_C22_Pkt";
BA_ "FlexKomSigName" SG_ 2432635775 SQC_SG_MPC_C22_Pkt "MPC_C22_Pkt";
BA_ "FlexKomSigLaenge" SG_ 2432635775 SQC_SG_MPC_C22_Pkt 64;
BA_ "FlexKomSigStartPos" SG_ 2432635775 SQC_SG_MPC_C22_Pkt 7;
BA_ "FlexKomSID" SG_ 2432635775 SQC_SG_MPC_C22_Pkt 100679844;
BA_ "FlexKomSigStartValue" SG_ 2432635775 SQC_SG_MPC_C22_Pkt "0DF0FFFFFFFFFFFFh";
BA_ "GenSigCycleTime" SG_ 2432635775 SQC_SG_MPC_C22_Pkt 50;
BA_ "GenSigSNA" SG_ 2432635775 ConfLvl_VehObj3_Cval "3h";
BA_ "FlexKomIsMotorola" SG_ 2432635775 ConfLvl_VehObj3_Cval 1;
BA_ "FlexKomComment" SG_ 2432635775 ConfLvl_VehObj3_Cval "MPC_C22_Pkt";
BA_ "FlexKomSigName" SG_ 2432635775 ConfLvl_VehObj3_Cval "MPC_C22_Pkt";
BA_ "FlexKomSigLaenge" SG_ 2432635775 ConfLvl_VehObj3_Cval 64;
BA_ "FlexKomSigStartPos" SG_ 2432635775 ConfLvl_VehObj3_Cval 7;
BA_ "FlexKomSID" SG_ 2432635775 ConfLvl_VehObj3_Cval 100679844;
BA_ "GenSigStartValue" SG_ 2432635775 ConfLvl_VehObj3_Cval 3;
BA_ "FlexKomSigStartValue" SG_ 2432635775 ConfLvl_VehObj3_Cval "0DF0FFFFFFFFFFFFh";
BA_ "GenSigCycleTime" SG_ 2432635775 ConfLvl_VehObj3_Cval 50;
BA_ "GenSigSNA" SG_ 2432635775 DtctStat_VehObj3_MPC "3h";
BA_ "FlexKomIsMotorola" SG_ 2432635775 DtctStat_VehObj3_MPC 1;
BA_ "FlexKomComment" SG_ 2432635775 DtctStat_VehObj3_MPC "MPC_C22_Pkt";
BA_ "FlexKomSigName" SG_ 2432635775 DtctStat_VehObj3_MPC "MPC_C22_Pkt";
BA_ "FlexKomSigLaenge" SG_ 2432635775 DtctStat_VehObj3_MPC 64;
BA_ "FlexKomSigStartPos" SG_ 2432635775 DtctStat_VehObj3_MPC 7;
BA_ "FlexKomSID" SG_ 2432635775 DtctStat_VehObj3_MPC 100679844;
BA_ "GenSigStartValue" SG_ 2432635775 DtctStat_VehObj3_MPC 3;
BA_ "FlexKomSigStartValue" SG_ 2432635775 DtctStat_VehObj3_MPC "0DF0FFFFFFFFFFFFh";
BA_ "GenSigCycleTime" SG_ 2432635775 DtctStat_VehObj3_MPC 50;
BA_ "GenSigSNA" SG_ 2432635775 Spd_X_VehObj3_Cval "FFh";
BA_ "FlexKomIsMotorola" SG_ 2432635775 Spd_X_VehObj3_Cval 1;
BA_ "FlexKomComment" SG_ 2432635775 Spd_X_VehObj3_Cval "MPC_C22_Pkt";
BA_ "FlexKomSigName" SG_ 2432635775 Spd_X_VehObj3_Cval "MPC_C22_Pkt";
BA_ "FlexKomSigLaenge" SG_ 2432635775 Spd_X_VehObj3_Cval 64;
BA_ "FlexKomSigStartPos" SG_ 2432635775 Spd_X_VehObj3_Cval 7;
BA_ "FlexKomSID" SG_ 2432635775 Spd_X_VehObj3_Cval 100679844;
BA_ "GenSigStartValue" SG_ 2432635775 Spd_X_VehObj3_Cval 255;
BA_ "FlexKomSigStartValue" SG_ 2432635775 Spd_X_VehObj3_Cval "0DF0FFFFFFFFFFFFh";
BA_ "GenSigCycleTime" SG_ 2432635775 Spd_X_VehObj3_Cval 50;
BA_ "GenSigSNA" SG_ 2432635775 Spd_Y_VehObj3_Cval "FFh";
BA_ "FlexKomIsMotorola" SG_ 2432635775 Spd_Y_VehObj3_Cval 1;
BA_ "FlexKomComment" SG_ 2432635775 Spd_Y_VehObj3_Cval "MPC_C22_Pkt";
BA_ "FlexKomSigName" SG_ 2432635775 Spd_Y_VehObj3_Cval "MPC_C22_Pkt";
BA_ "FlexKomSigLaenge" SG_ 2432635775 Spd_Y_VehObj3_Cval 64;
BA_ "FlexKomSigStartPos" SG_ 2432635775 Spd_Y_VehObj3_Cval 7;
BA_ "FlexKomSID" SG_ 2432635775 Spd_Y_VehObj3_Cval 100679844;
BA_ "GenSigStartValue" SG_ 2432635775 Spd_Y_VehObj3_Cval 255;
BA_ "FlexKomSigStartValue" SG_ 2432635775 Spd_Y_VehObj3_Cval "0DF0FFFFFFFFFFFFh";
BA_ "GenSigCycleTime" SG_ 2432635775 Spd_Y_VehObj3_Cval 50;
BA_ "GenSigSNA" SG_ 2432635775 Dist_X_VehObj3_Cval_MPC "FFFFh";
BA_ "FlexKomIsMotorola" SG_ 2432635775 Dist_X_VehObj3_Cval_MPC 1;
BA_ "FlexKomComment" SG_ 2432635775 Dist_X_VehObj3_Cval_MPC "MPC_C22_Pkt";
BA_ "FlexKomSigName" SG_ 2432635775 Dist_X_VehObj3_Cval_MPC "MPC_C22_Pkt";
BA_ "FlexKomSigLaenge" SG_ 2432635775 Dist_X_VehObj3_Cval_MPC 64;
BA_ "FlexKomSigStartPos" SG_ 2432635775 Dist_X_VehObj3_Cval_MPC 7;
BA_ "FlexKomSID" SG_ 2432635775 Dist_X_VehObj3_Cval_MPC 100679844;
BA_ "GenSigStartValue" SG_ 2432635775 Dist_X_VehObj3_Cval_MPC 65535;
BA_ "FlexKomSigStartValue" SG_ 2432635775 Dist_X_VehObj3_Cval_MPC "0DF0FFFFFFFFFFFFh";
BA_ "GenSigCycleTime" SG_ 2432635775 Dist_X_VehObj3_Cval_MPC 50;
BA_ "GenSigSNA" SG_ 2432635775 Dist_Y_VehObj3_Cval_MPC "FFFFh";
BA_ "FlexKomIsMotorola" SG_ 2432635775 Dist_Y_VehObj3_Cval_MPC 1;
BA_ "FlexKomComment" SG_ 2432635775 Dist_Y_VehObj3_Cval_MPC "MPC_C22_Pkt";
BA_ "FlexKomSigName" SG_ 2432635775 Dist_Y_VehObj3_Cval_MPC "MPC_C22_Pkt";
BA_ "FlexKomSigLaenge" SG_ 2432635775 Dist_Y_VehObj3_Cval_MPC 64;
BA_ "FlexKomSigStartPos" SG_ 2432635775 Dist_Y_VehObj3_Cval_MPC 7;
BA_ "FlexKomSID" SG_ 2432635775 Dist_Y_VehObj3_Cval_MPC 100679844;
BA_ "GenSigStartValue" SG_ 2432635775 Dist_Y_VehObj3_Cval_MPC 65535;
BA_ "FlexKomSigStartValue" SG_ 2432635775 Dist_Y_VehObj3_Cval_MPC "0DF0FFFFFFFFFFFFh";
BA_ "GenSigCycleTime" SG_ 2432635775 Dist_Y_VehObj3_Cval_MPC 50;
BA_ "GenSigSNA" SG_ 2432636031 CRC_SG_MPC_C23_Pkt "99h";
BA_ "FlexKomIsMotorola" SG_ 2432636031 CRC_SG_MPC_C23_Pkt 1;
BA_ "FlexKomComment" SG_ 2432636031 CRC_SG_MPC_C23_Pkt "MPC C23 Pkt";
BA_ "FlexKomSigName" SG_ 2432636031 CRC_SG_MPC_C23_Pkt "MPC_C23_Pkt";
BA_ "FlexKomSigLaenge" SG_ 2432636031 CRC_SG_MPC_C23_Pkt 64;
BA_ "FlexKomSigStartPos" SG_ 2432636031 CRC_SG_MPC_C23_Pkt 7;
BA_ "FlexKomSID" SG_ 2432636031 CRC_SG_MPC_C23_Pkt 100679833;
BA_ "GenSigStartValue" SG_ 2432636031 CRC_SG_MPC_C23_Pkt 153;
BA_ "FlexKomSigStartValue" SG_ 2432636031 CRC_SG_MPC_C23_Pkt "99F0FFFFFFFFFFFFh";
BA_ "GenSigCycleTime" SG_ 2432636031 CRC_SG_MPC_C23_Pkt 50;
BA_ "GenSigSNA" SG_ 2432636031 SQC_SG_MPC_C23_Pkt "0h";
BA_ "FlexKomIsMotorola" SG_ 2432636031 SQC_SG_MPC_C23_Pkt 1;
BA_ "FlexKomComment" SG_ 2432636031 SQC_SG_MPC_C23_Pkt "MPC C23 Pkt";
BA_ "FlexKomSigName" SG_ 2432636031 SQC_SG_MPC_C23_Pkt "MPC_C23_Pkt";
BA_ "FlexKomSigLaenge" SG_ 2432636031 SQC_SG_MPC_C23_Pkt 64;
BA_ "FlexKomSigStartPos" SG_ 2432636031 SQC_SG_MPC_C23_Pkt 7;
BA_ "FlexKomSID" SG_ 2432636031 SQC_SG_MPC_C23_Pkt 100679833;
BA_ "FlexKomSigStartValue" SG_ 2432636031 SQC_SG_MPC_C23_Pkt "99F0FFFFFFFFFFFFh";
BA_ "GenSigCycleTime" SG_ 2432636031 SQC_SG_MPC_C23_Pkt 50;
BA_ "GenSigSNA" SG_ 2432636031 ClassVehObj0_Stat_MPC "Fh";
BA_ "FlexKomIsMotorola" SG_ 2432636031 ClassVehObj0_Stat_MPC 1;
BA_ "FlexKomComment" SG_ 2432636031 ClassVehObj0_Stat_MPC "MPC C23 Pkt";
BA_ "FlexKomSigName" SG_ 2432636031 ClassVehObj0_Stat_MPC "MPC_C23_Pkt";
BA_ "FlexKomSigLaenge" SG_ 2432636031 ClassVehObj0_Stat_MPC 64;
BA_ "FlexKomSigStartPos" SG_ 2432636031 ClassVehObj0_Stat_MPC 7;
BA_ "FlexKomSID" SG_ 2432636031 ClassVehObj0_Stat_MPC 100679833;
BA_ "GenSigStartValue" SG_ 2432636031 ClassVehObj0_Stat_MPC 15;
BA_ "FlexKomSigStartValue" SG_ 2432636031 ClassVehObj0_Stat_MPC "99F0FFFFFFFFFFFFh";
BA_ "GenSigCycleTime" SG_ 2432636031 ClassVehObj0_Stat_MPC 50;
BA_ "GenSigSNA" SG_ 2432636031 NumVehObj0_Cval_MPC "1Fh";
BA_ "FlexKomIsMotorola" SG_ 2432636031 NumVehObj0_Cval_MPC 1;
BA_ "FlexKomComment" SG_ 2432636031 NumVehObj0_Cval_MPC "MPC C23 Pkt";
BA_ "FlexKomSigName" SG_ 2432636031 NumVehObj0_Cval_MPC "MPC_C23_Pkt";
BA_ "FlexKomSigLaenge" SG_ 2432636031 NumVehObj0_Cval_MPC 64;
BA_ "FlexKomSigStartPos" SG_ 2432636031 NumVehObj0_Cval_MPC 7;
BA_ "FlexKomSID" SG_ 2432636031 NumVehObj0_Cval_MPC 100679833;
BA_ "GenSigStartValue" SG_ 2432636031 NumVehObj0_Cval_MPC 31;
BA_ "FlexKomSigStartValue" SG_ 2432636031 NumVehObj0_Cval_MPC "99F0FFFFFFFFFFFFh";
BA_ "GenSigCycleTime" SG_ 2432636031 NumVehObj0_Cval_MPC 50;
BA_ "GenSigSNA" SG_ 2432636031 TypeVehObj0_Stat_MPC "7h";
BA_ "FlexKomIsMotorola" SG_ 2432636031 TypeVehObj0_Stat_MPC 1;
BA_ "FlexKomComment" SG_ 2432636031 TypeVehObj0_Stat_MPC "MPC C23 Pkt";
BA_ "FlexKomSigName" SG_ 2432636031 TypeVehObj0_Stat_MPC "MPC_C23_Pkt";
BA_ "FlexKomSigLaenge" SG_ 2432636031 TypeVehObj0_Stat_MPC 64;
BA_ "FlexKomSigStartPos" SG_ 2432636031 TypeVehObj0_Stat_MPC 7;
BA_ "FlexKomSID" SG_ 2432636031 TypeVehObj0_Stat_MPC 100679833;
BA_ "GenSigStartValue" SG_ 2432636031 TypeVehObj0_Stat_MPC 7;
BA_ "FlexKomSigStartValue" SG_ 2432636031 TypeVehObj0_Stat_MPC "99F0FFFFFFFFFFFFh";
BA_ "GenSigCycleTime" SG_ 2432636031 TypeVehObj0_Stat_MPC 50;
BA_ "GenSigSNA" SG_ 2432636031 StdRng_X_VehObj0_Cval_MPC "3h";
BA_ "FlexKomIsMotorola" SG_ 2432636031 StdRng_X_VehObj0_Cval_MPC 1;
BA_ "FlexKomComment" SG_ 2432636031 StdRng_X_VehObj0_Cval_MPC "MPC C23 Pkt";
BA_ "FlexKomSigName" SG_ 2432636031 StdRng_X_VehObj0_Cval_MPC "MPC_C23_Pkt";
BA_ "FlexKomSigLaenge" SG_ 2432636031 StdRng_X_VehObj0_Cval_MPC 64;
BA_ "FlexKomSigStartPos" SG_ 2432636031 StdRng_X_VehObj0_Cval_MPC 7;
BA_ "FlexKomSID" SG_ 2432636031 StdRng_X_VehObj0_Cval_MPC 100679833;
BA_ "GenSigStartValue" SG_ 2432636031 StdRng_X_VehObj0_Cval_MPC 3;
BA_ "FlexKomSigStartValue" SG_ 2432636031 StdRng_X_VehObj0_Cval_MPC "99F0FFFFFFFFFFFFh";
BA_ "GenSigCycleTime" SG_ 2432636031 StdRng_X_VehObj0_Cval_MPC 50;
BA_ "GenSigSNA" SG_ 2432636031 StdRng_Y_VehObj0_Cval_MPC "3h";
BA_ "FlexKomIsMotorola" SG_ 2432636031 StdRng_Y_VehObj0_Cval_MPC 1;
BA_ "FlexKomComment" SG_ 2432636031 StdRng_Y_VehObj0_Cval_MPC "MPC C23 Pkt";
BA_ "FlexKomSigName" SG_ 2432636031 StdRng_Y_VehObj0_Cval_MPC "MPC_C23_Pkt";
BA_ "FlexKomSigLaenge" SG_ 2432636031 StdRng_Y_VehObj0_Cval_MPC 64;
BA_ "FlexKomSigStartPos" SG_ 2432636031 StdRng_Y_VehObj0_Cval_MPC 7;
BA_ "FlexKomSID" SG_ 2432636031 StdRng_Y_VehObj0_Cval_MPC 100679833;
BA_ "GenSigStartValue" SG_ 2432636031 StdRng_Y_VehObj0_Cval_MPC 3;
BA_ "FlexKomSigStartValue" SG_ 2432636031 StdRng_Y_VehObj0_Cval_MPC "99F0FFFFFFFFFFFFh";
BA_ "GenSigCycleTime" SG_ 2432636031 StdRng_Y_VehObj0_Cval_MPC 50;
BA_ "GenSigSNA" SG_ 2432636031 StdRng_Spd_X_VehObj0_Cval_MPC "3h";
BA_ "FlexKomIsMotorola" SG_ 2432636031 StdRng_Spd_X_VehObj0_Cval_MPC 1;
BA_ "FlexKomComment" SG_ 2432636031 StdRng_Spd_X_VehObj0_Cval_MPC "MPC C23 Pkt";
BA_ "FlexKomSigName" SG_ 2432636031 StdRng_Spd_X_VehObj0_Cval_MPC "MPC_C23_Pkt";
BA_ "FlexKomSigLaenge" SG_ 2432636031 StdRng_Spd_X_VehObj0_Cval_MPC 64;
BA_ "FlexKomSigStartPos" SG_ 2432636031 StdRng_Spd_X_VehObj0_Cval_MPC 7;
BA_ "FlexKomSID" SG_ 2432636031 StdRng_Spd_X_VehObj0_Cval_MPC 100679833;
BA_ "GenSigStartValue" SG_ 2432636031 StdRng_Spd_X_VehObj0_Cval_MPC 3;
BA_ "FlexKomSigStartValue" SG_ 2432636031 StdRng_Spd_X_VehObj0_Cval_MPC "99F0FFFFFFFFFFFFh";
BA_ "GenSigCycleTime" SG_ 2432636031 StdRng_Spd_X_VehObj0_Cval_MPC 50;
BA_ "GenSigSNA" SG_ 2432636031 StdRng_Spd_Y_VehObj0_Cval_MPC "3h";
BA_ "FlexKomIsMotorola" SG_ 2432636031 StdRng_Spd_Y_VehObj0_Cval_MPC 1;
BA_ "FlexKomComment" SG_ 2432636031 StdRng_Spd_Y_VehObj0_Cval_MPC "MPC C23 Pkt";
BA_ "FlexKomSigName" SG_ 2432636031 StdRng_Spd_Y_VehObj0_Cval_MPC "MPC_C23_Pkt";
BA_ "FlexKomSigLaenge" SG_ 2432636031 StdRng_Spd_Y_VehObj0_Cval_MPC 64;
BA_ "FlexKomSigStartPos" SG_ 2432636031 StdRng_Spd_Y_VehObj0_Cval_MPC 7;
BA_ "FlexKomSID" SG_ 2432636031 StdRng_Spd_Y_VehObj0_Cval_MPC 100679833;
BA_ "GenSigStartValue" SG_ 2432636031 StdRng_Spd_Y_VehObj0_Cval_MPC 3;
BA_ "FlexKomSigStartValue" SG_ 2432636031 StdRng_Spd_Y_VehObj0_Cval_MPC "99F0FFFFFFFFFFFFh";
BA_ "GenSigCycleTime" SG_ 2432636031 StdRng_Spd_Y_VehObj0_Cval_MPC 50;
BA_ "GenSigSNA" SG_ 2432636031 WidthVehObj0_Cval_MPC "FFh";
BA_ "FlexKomIsMotorola" SG_ 2432636031 WidthVehObj0_Cval_MPC 1;
BA_ "FlexKomComment" SG_ 2432636031 WidthVehObj0_Cval_MPC "MPC C23 Pkt";
BA_ "FlexKomSigName" SG_ 2432636031 WidthVehObj0_Cval_MPC "MPC_C23_Pkt";
BA_ "FlexKomSigLaenge" SG_ 2432636031 WidthVehObj0_Cval_MPC 64;
BA_ "FlexKomSigStartPos" SG_ 2432636031 WidthVehObj0_Cval_MPC 7;
BA_ "FlexKomSID" SG_ 2432636031 WidthVehObj0_Cval_MPC 100679833;
BA_ "GenSigStartValue" SG_ 2432636031 WidthVehObj0_Cval_MPC 255;
BA_ "FlexKomSigStartValue" SG_ 2432636031 WidthVehObj0_Cval_MPC "99F0FFFFFFFFFFFFh";
BA_ "GenSigCycleTime" SG_ 2432636031 WidthVehObj0_Cval_MPC 50;
BA_ "GenSigSNA" SG_ 2432636031 OLA_VehObj0_Cval_MPC "FFh";
BA_ "FlexKomIsMotorola" SG_ 2432636031 OLA_VehObj0_Cval_MPC 1;
BA_ "FlexKomComment" SG_ 2432636031 OLA_VehObj0_Cval_MPC "MPC C23 Pkt";
BA_ "FlexKomSigName" SG_ 2432636031 OLA_VehObj0_Cval_MPC "MPC_C23_Pkt";
BA_ "FlexKomSigLaenge" SG_ 2432636031 OLA_VehObj0_Cval_MPC 64;
BA_ "FlexKomSigStartPos" SG_ 2432636031 OLA_VehObj0_Cval_MPC 7;
BA_ "FlexKomSID" SG_ 2432636031 OLA_VehObj0_Cval_MPC 100679833;
BA_ "GenSigStartValue" SG_ 2432636031 OLA_VehObj0_Cval_MPC 255;
BA_ "FlexKomSigStartValue" SG_ 2432636031 OLA_VehObj0_Cval_MPC "99F0FFFFFFFFFFFFh";
BA_ "GenSigCycleTime" SG_ 2432636031 OLA_VehObj0_Cval_MPC 50;
BA_ "GenSigSNA" SG_ 2432636031 HeightVehObj0_Cval_MPC "FFh";
BA_ "FlexKomIsMotorola" SG_ 2432636031 HeightVehObj0_Cval_MPC 1;
BA_ "FlexKomComment" SG_ 2432636031 HeightVehObj0_Cval_MPC "MPC C23 Pkt";
BA_ "FlexKomSigName" SG_ 2432636031 HeightVehObj0_Cval_MPC "MPC_C23_Pkt";
BA_ "FlexKomSigLaenge" SG_ 2432636031 HeightVehObj0_Cval_MPC 64;
BA_ "FlexKomSigStartPos" SG_ 2432636031 HeightVehObj0_Cval_MPC 7;
BA_ "FlexKomSID" SG_ 2432636031 HeightVehObj0_Cval_MPC 100679833;
BA_ "GenSigStartValue" SG_ 2432636031 HeightVehObj0_Cval_MPC 255;
BA_ "FlexKomSigStartValue" SG_ 2432636031 HeightVehObj0_Cval_MPC "99F0FFFFFFFFFFFFh";
BA_ "GenSigCycleTime" SG_ 2432636031 HeightVehObj0_Cval_MPC 50;
BA_ "GenSigSNA" SG_ 2432636031 LaneAlloc_VehObj0_Cval_MPC "7h";
BA_ "FlexKomIsMotorola" SG_ 2432636031 LaneAlloc_VehObj0_Cval_MPC 1;
BA_ "FlexKomComment" SG_ 2432636031 LaneAlloc_VehObj0_Cval_MPC "MPC C23 Pkt";
BA_ "FlexKomSigName" SG_ 2432636031 LaneAlloc_VehObj0_Cval_MPC "MPC_C23_Pkt";
BA_ "FlexKomSigLaenge" SG_ 2432636031 LaneAlloc_VehObj0_Cval_MPC 64;
BA_ "FlexKomSigStartPos" SG_ 2432636031 LaneAlloc_VehObj0_Cval_MPC 7;
BA_ "FlexKomSID" SG_ 2432636031 LaneAlloc_VehObj0_Cval_MPC 100679833;
BA_ "GenSigStartValue" SG_ 2432636031 LaneAlloc_VehObj0_Cval_MPC 7;
BA_ "FlexKomSigStartValue" SG_ 2432636031 LaneAlloc_VehObj0_Cval_MPC "99F0FFFFFFFFFFFFh";
BA_ "GenSigCycleTime" SG_ 2432636031 LaneAlloc_VehObj0_Cval_MPC 50;
BA_ "GenSigSNA" SG_ 2432636031 TurnSgl_VehObj0_Cval_MPC "7h";
BA_ "FlexKomIsMotorola" SG_ 2432636031 TurnSgl_VehObj0_Cval_MPC 1;
BA_ "FlexKomComment" SG_ 2432636031 TurnSgl_VehObj0_Cval_MPC "MPC C23 Pkt";
BA_ "FlexKomSigName" SG_ 2432636031 TurnSgl_VehObj0_Cval_MPC "MPC_C23_Pkt";
BA_ "FlexKomSigLaenge" SG_ 2432636031 TurnSgl_VehObj0_Cval_MPC 64;
BA_ "FlexKomSigStartPos" SG_ 2432636031 TurnSgl_VehObj0_Cval_MPC 7;
BA_ "FlexKomSID" SG_ 2432636031 TurnSgl_VehObj0_Cval_MPC 100679833;
BA_ "GenSigStartValue" SG_ 2432636031 TurnSgl_VehObj0_Cval_MPC 7;
BA_ "FlexKomSigStartValue" SG_ 2432636031 TurnSgl_VehObj0_Cval_MPC "99F0FFFFFFFFFFFFh";
BA_ "GenSigCycleTime" SG_ 2432636031 TurnSgl_VehObj0_Cval_MPC 50;
BA_ "GenSigSNA" SG_ 2432636031 LaneChgInd_VehObj0_Stat_MPC "3h";
BA_ "FlexKomIsMotorola" SG_ 2432636031 LaneChgInd_VehObj0_Stat_MPC 1;
BA_ "FlexKomComment" SG_ 2432636031 LaneChgInd_VehObj0_Stat_MPC "MPC C23 Pkt";
BA_ "FlexKomSigName" SG_ 2432636031 LaneChgInd_VehObj0_Stat_MPC "MPC_C23_Pkt";
BA_ "FlexKomSigLaenge" SG_ 2432636031 LaneChgInd_VehObj0_Stat_MPC 64;
BA_ "FlexKomSigStartPos" SG_ 2432636031 LaneChgInd_VehObj0_Stat_MPC 7;
BA_ "FlexKomSID" SG_ 2432636031 LaneChgInd_VehObj0_Stat_MPC 100679833;
BA_ "GenSigStartValue" SG_ 2432636031 LaneChgInd_VehObj0_Stat_MPC 3;
BA_ "FlexKomSigStartValue" SG_ 2432636031 LaneChgInd_VehObj0_Stat_MPC "99F0FFFFFFFFFFFFh";
BA_ "GenSigCycleTime" SG_ 2432636031 LaneChgInd_VehObj0_Stat_MPC 50;
BA_ "GenSigSNA" SG_ 2432636287 CRC_SG_MPC_C24_Pkt "EEh";
BA_ "FlexKomIsMotorola" SG_ 2432636287 CRC_SG_MPC_C24_Pkt 1;
BA_ "FlexKomComment" SG_ 2432636287 CRC_SG_MPC_C24_Pkt "MPC C23 Pkt";
BA_ "FlexKomSigName" SG_ 2432636287 CRC_SG_MPC_C24_Pkt "MPC_C24_Pkt";
BA_ "FlexKomSigLaenge" SG_ 2432636287 CRC_SG_MPC_C24_Pkt 64;
BA_ "FlexKomSigStartPos" SG_ 2432636287 CRC_SG_MPC_C24_Pkt 7;
BA_ "FlexKomSID" SG_ 2432636287 CRC_SG_MPC_C24_Pkt 100679835;
BA_ "GenSigStartValue" SG_ 2432636287 CRC_SG_MPC_C24_Pkt 238;
BA_ "FlexKomSigStartValue" SG_ 2432636287 CRC_SG_MPC_C24_Pkt "EEF0FFFFFFFFFFFFh";
BA_ "GenSigCycleTime" SG_ 2432636287 CRC_SG_MPC_C24_Pkt 50;
BA_ "GenSigSNA" SG_ 2432636287 SQC_SG_MPC_C24_Pkt "0h";
BA_ "FlexKomIsMotorola" SG_ 2432636287 SQC_SG_MPC_C24_Pkt 1;
BA_ "FlexKomComment" SG_ 2432636287 SQC_SG_MPC_C24_Pkt "MPC C23 Pkt";
BA_ "FlexKomSigName" SG_ 2432636287 SQC_SG_MPC_C24_Pkt "MPC_C24_Pkt";
BA_ "FlexKomSigLaenge" SG_ 2432636287 SQC_SG_MPC_C24_Pkt 64;
BA_ "FlexKomSigStartPos" SG_ 2432636287 SQC_SG_MPC_C24_Pkt 7;
BA_ "FlexKomSID" SG_ 2432636287 SQC_SG_MPC_C24_Pkt 100679835;
BA_ "FlexKomSigStartValue" SG_ 2432636287 SQC_SG_MPC_C24_Pkt "EEF0FFFFFFFFFFFFh";
BA_ "GenSigCycleTime" SG_ 2432636287 SQC_SG_MPC_C24_Pkt 50;
BA_ "GenSigSNA" SG_ 2432636287 ClassVehObj1_Stat_MPC "Fh";
BA_ "FlexKomIsMotorola" SG_ 2432636287 ClassVehObj1_Stat_MPC 1;
BA_ "FlexKomComment" SG_ 2432636287 ClassVehObj1_Stat_MPC "MPC C23 Pkt";
BA_ "FlexKomSigName" SG_ 2432636287 ClassVehObj1_Stat_MPC "MPC_C24_Pkt";
BA_ "FlexKomSigLaenge" SG_ 2432636287 ClassVehObj1_Stat_MPC 64;
BA_ "FlexKomSigStartPos" SG_ 2432636287 ClassVehObj1_Stat_MPC 7;
BA_ "FlexKomSID" SG_ 2432636287 ClassVehObj1_Stat_MPC 100679835;
BA_ "GenSigStartValue" SG_ 2432636287 ClassVehObj1_Stat_MPC 15;
BA_ "FlexKomSigStartValue" SG_ 2432636287 ClassVehObj1_Stat_MPC "EEF0FFFFFFFFFFFFh";
BA_ "GenSigCycleTime" SG_ 2432636287 ClassVehObj1_Stat_MPC 50;
BA_ "GenSigSNA" SG_ 2432636287 NumVehObj1_Cval_MPC "1Fh";
BA_ "FlexKomIsMotorola" SG_ 2432636287 NumVehObj1_Cval_MPC 1;
BA_ "FlexKomComment" SG_ 2432636287 NumVehObj1_Cval_MPC "MPC C23 Pkt";
BA_ "FlexKomSigName" SG_ 2432636287 NumVehObj1_Cval_MPC "MPC_C24_Pkt";
BA_ "FlexKomSigLaenge" SG_ 2432636287 NumVehObj1_Cval_MPC 64;
BA_ "FlexKomSigStartPos" SG_ 2432636287 NumVehObj1_Cval_MPC 7;
BA_ "FlexKomSID" SG_ 2432636287 NumVehObj1_Cval_MPC 100679835;
BA_ "GenSigStartValue" SG_ 2432636287 NumVehObj1_Cval_MPC 31;
BA_ "FlexKomSigStartValue" SG_ 2432636287 NumVehObj1_Cval_MPC "EEF0FFFFFFFFFFFFh";
BA_ "GenSigCycleTime" SG_ 2432636287 NumVehObj1_Cval_MPC 50;
BA_ "GenSigSNA" SG_ 2432636287 TypeVehObj1_Stat_MPC "7h";
BA_ "FlexKomIsMotorola" SG_ 2432636287 TypeVehObj1_Stat_MPC 1;
BA_ "FlexKomComment" SG_ 2432636287 TypeVehObj1_Stat_MPC "MPC C23 Pkt";
BA_ "FlexKomSigName" SG_ 2432636287 TypeVehObj1_Stat_MPC "MPC_C24_Pkt";
BA_ "FlexKomSigLaenge" SG_ 2432636287 TypeVehObj1_Stat_MPC 64;
BA_ "FlexKomSigStartPos" SG_ 2432636287 TypeVehObj1_Stat_MPC 7;
BA_ "FlexKomSID" SG_ 2432636287 TypeVehObj1_Stat_MPC 100679835;
BA_ "GenSigStartValue" SG_ 2432636287 TypeVehObj1_Stat_MPC 7;
BA_ "FlexKomSigStartValue" SG_ 2432636287 TypeVehObj1_Stat_MPC "EEF0FFFFFFFFFFFFh";
BA_ "GenSigCycleTime" SG_ 2432636287 TypeVehObj1_Stat_MPC 50;
BA_ "GenSigSNA" SG_ 2432636287 StdRng_X_VehObj1_Cval_MPC "3h";
BA_ "FlexKomIsMotorola" SG_ 2432636287 StdRng_X_VehObj1_Cval_MPC 1;
BA_ "FlexKomComment" SG_ 2432636287 StdRng_X_VehObj1_Cval_MPC "MPC C23 Pkt";
BA_ "FlexKomSigName" SG_ 2432636287 StdRng_X_VehObj1_Cval_MPC "MPC_C24_Pkt";
BA_ "FlexKomSigLaenge" SG_ 2432636287 StdRng_X_VehObj1_Cval_MPC 64;
BA_ "FlexKomSigStartPos" SG_ 2432636287 StdRng_X_VehObj1_Cval_MPC 7;
BA_ "FlexKomSID" SG_ 2432636287 StdRng_X_VehObj1_Cval_MPC 100679835;
BA_ "GenSigStartValue" SG_ 2432636287 StdRng_X_VehObj1_Cval_MPC 3;
BA_ "FlexKomSigStartValue" SG_ 2432636287 StdRng_X_VehObj1_Cval_MPC "EEF0FFFFFFFFFFFFh";
BA_ "GenSigCycleTime" SG_ 2432636287 StdRng_X_VehObj1_Cval_MPC 50;
BA_ "GenSigSNA" SG_ 2432636287 StdRng_Y_VehObj1_Cval_MPC "3h";
BA_ "FlexKomIsMotorola" SG_ 2432636287 StdRng_Y_VehObj1_Cval_MPC 1;
BA_ "FlexKomComment" SG_ 2432636287 StdRng_Y_VehObj1_Cval_MPC "MPC C23 Pkt";
BA_ "FlexKomSigName" SG_ 2432636287 StdRng_Y_VehObj1_Cval_MPC "MPC_C24_Pkt";
BA_ "FlexKomSigLaenge" SG_ 2432636287 StdRng_Y_VehObj1_Cval_MPC 64;
BA_ "FlexKomSigStartPos" SG_ 2432636287 StdRng_Y_VehObj1_Cval_MPC 7;
BA_ "FlexKomSID" SG_ 2432636287 StdRng_Y_VehObj1_Cval_MPC 100679835;
BA_ "GenSigStartValue" SG_ 2432636287 StdRng_Y_VehObj1_Cval_MPC 3;
BA_ "FlexKomSigStartValue" SG_ 2432636287 StdRng_Y_VehObj1_Cval_MPC "EEF0FFFFFFFFFFFFh";
BA_ "GenSigCycleTime" SG_ 2432636287 StdRng_Y_VehObj1_Cval_MPC 50;
BA_ "GenSigSNA" SG_ 2432636287 StdRng_Spd_X_VehObj1_Cval_MPC "3h";
BA_ "FlexKomIsMotorola" SG_ 2432636287 StdRng_Spd_X_VehObj1_Cval_MPC 1;
BA_ "FlexKomComment" SG_ 2432636287 StdRng_Spd_X_VehObj1_Cval_MPC "MPC C23 Pkt";
BA_ "FlexKomSigName" SG_ 2432636287 StdRng_Spd_X_VehObj1_Cval_MPC "MPC_C24_Pkt";
BA_ "FlexKomSigLaenge" SG_ 2432636287 StdRng_Spd_X_VehObj1_Cval_MPC 64;
BA_ "FlexKomSigStartPos" SG_ 2432636287 StdRng_Spd_X_VehObj1_Cval_MPC 7;
BA_ "FlexKomSID" SG_ 2432636287 StdRng_Spd_X_VehObj1_Cval_MPC 100679835;
BA_ "GenSigStartValue" SG_ 2432636287 StdRng_Spd_X_VehObj1_Cval_MPC 3;
BA_ "FlexKomSigStartValue" SG_ 2432636287 StdRng_Spd_X_VehObj1_Cval_MPC "EEF0FFFFFFFFFFFFh";
BA_ "GenSigCycleTime" SG_ 2432636287 StdRng_Spd_X_VehObj1_Cval_MPC 50;
BA_ "GenSigSNA" SG_ 2432636287 StdRng_Spd_Y_VehObj1_Cval_MPC "3h";
BA_ "FlexKomIsMotorola" SG_ 2432636287 StdRng_Spd_Y_VehObj1_Cval_MPC 1;
BA_ "FlexKomComment" SG_ 2432636287 StdRng_Spd_Y_VehObj1_Cval_MPC "MPC C23 Pkt";
BA_ "FlexKomSigName" SG_ 2432636287 StdRng_Spd_Y_VehObj1_Cval_MPC "MPC_C24_Pkt";
BA_ "FlexKomSigLaenge" SG_ 2432636287 StdRng_Spd_Y_VehObj1_Cval_MPC 64;
BA_ "FlexKomSigStartPos" SG_ 2432636287 StdRng_Spd_Y_VehObj1_Cval_MPC 7;
BA_ "FlexKomSID" SG_ 2432636287 StdRng_Spd_Y_VehObj1_Cval_MPC 100679835;
BA_ "GenSigStartValue" SG_ 2432636287 StdRng_Spd_Y_VehObj1_Cval_MPC 3;
BA_ "FlexKomSigStartValue" SG_ 2432636287 StdRng_Spd_Y_VehObj1_Cval_MPC "EEF0FFFFFFFFFFFFh";
BA_ "GenSigCycleTime" SG_ 2432636287 StdRng_Spd_Y_VehObj1_Cval_MPC 50;
BA_ "GenSigSNA" SG_ 2432636287 WidthVehObj1_Cval_MPC "FFh";
BA_ "FlexKomIsMotorola" SG_ 2432636287 WidthVehObj1_Cval_MPC 1;
BA_ "FlexKomComment" SG_ 2432636287 WidthVehObj1_Cval_MPC "MPC C23 Pkt";
BA_ "FlexKomSigName" SG_ 2432636287 WidthVehObj1_Cval_MPC "MPC_C24_Pkt";
BA_ "FlexKomSigLaenge" SG_ 2432636287 WidthVehObj1_Cval_MPC 64;
BA_ "FlexKomSigStartPos" SG_ 2432636287 WidthVehObj1_Cval_MPC 7;
BA_ "FlexKomSID" SG_ 2432636287 WidthVehObj1_Cval_MPC 100679835;
BA_ "GenSigStartValue" SG_ 2432636287 WidthVehObj1_Cval_MPC 255;
BA_ "FlexKomSigStartValue" SG_ 2432636287 WidthVehObj1_Cval_MPC "EEF0FFFFFFFFFFFFh";
BA_ "GenSigCycleTime" SG_ 2432636287 WidthVehObj1_Cval_MPC 50;
BA_ "GenSigSNA" SG_ 2432636287 OLA_VehObj1_Cval_MPC "FFh";
BA_ "FlexKomIsMotorola" SG_ 2432636287 OLA_VehObj1_Cval_MPC 1;
BA_ "FlexKomComment" SG_ 2432636287 OLA_VehObj1_Cval_MPC "MPC C23 Pkt";
BA_ "FlexKomSigName" SG_ 2432636287 OLA_VehObj1_Cval_MPC "MPC_C24_Pkt";
BA_ "FlexKomSigLaenge" SG_ 2432636287 OLA_VehObj1_Cval_MPC 64;
BA_ "FlexKomSigStartPos" SG_ 2432636287 OLA_VehObj1_Cval_MPC 7;
BA_ "FlexKomSID" SG_ 2432636287 OLA_VehObj1_Cval_MPC 100679835;
BA_ "GenSigStartValue" SG_ 2432636287 OLA_VehObj1_Cval_MPC 255;
BA_ "FlexKomSigStartValue" SG_ 2432636287 OLA_VehObj1_Cval_MPC "EEF0FFFFFFFFFFFFh";
BA_ "GenSigCycleTime" SG_ 2432636287 OLA_VehObj1_Cval_MPC 50;
BA_ "GenSigSNA" SG_ 2432636287 HeightVehObj1_Cval_MPC "FFh";
BA_ "FlexKomIsMotorola" SG_ 2432636287 HeightVehObj1_Cval_MPC 1;
BA_ "FlexKomComment" SG_ 2432636287 HeightVehObj1_Cval_MPC "MPC C23 Pkt";
BA_ "FlexKomSigName" SG_ 2432636287 HeightVehObj1_Cval_MPC "MPC_C24_Pkt";
BA_ "FlexKomSigLaenge" SG_ 2432636287 HeightVehObj1_Cval_MPC 64;
BA_ "FlexKomSigStartPos" SG_ 2432636287 HeightVehObj1_Cval_MPC 7;
BA_ "FlexKomSID" SG_ 2432636287 HeightVehObj1_Cval_MPC 100679835;
BA_ "GenSigStartValue" SG_ 2432636287 HeightVehObj1_Cval_MPC 255;
BA_ "FlexKomSigStartValue" SG_ 2432636287 HeightVehObj1_Cval_MPC "EEF0FFFFFFFFFFFFh";
BA_ "GenSigCycleTime" SG_ 2432636287 HeightVehObj1_Cval_MPC 50;
BA_ "GenSigSNA" SG_ 2432636287 LaneAlloc_VehObj1_Cval_MPC "7h";
BA_ "FlexKomIsMotorola" SG_ 2432636287 LaneAlloc_VehObj1_Cval_MPC 1;
BA_ "FlexKomComment" SG_ 2432636287 LaneAlloc_VehObj1_Cval_MPC "MPC C23 Pkt";
BA_ "FlexKomSigName" SG_ 2432636287 LaneAlloc_VehObj1_Cval_MPC "MPC_C24_Pkt";
BA_ "FlexKomSigLaenge" SG_ 2432636287 LaneAlloc_VehObj1_Cval_MPC 64;
BA_ "FlexKomSigStartPos" SG_ 2432636287 LaneAlloc_VehObj1_Cval_MPC 7;
BA_ "FlexKomSID" SG_ 2432636287 LaneAlloc_VehObj1_Cval_MPC 100679835;
BA_ "GenSigStartValue" SG_ 2432636287 LaneAlloc_VehObj1_Cval_MPC 7;
BA_ "FlexKomSigStartValue" SG_ 2432636287 LaneAlloc_VehObj1_Cval_MPC "EEF0FFFFFFFFFFFFh";
BA_ "GenSigCycleTime" SG_ 2432636287 LaneAlloc_VehObj1_Cval_MPC 50;
BA_ "GenSigSNA" SG_ 2432636287 TurnSgl_VehObj1_Cval_MPC "7h";
BA_ "FlexKomIsMotorola" SG_ 2432636287 TurnSgl_VehObj1_Cval_MPC 1;
BA_ "FlexKomComment" SG_ 2432636287 TurnSgl_VehObj1_Cval_MPC "MPC C23 Pkt";
BA_ "FlexKomSigName" SG_ 2432636287 TurnSgl_VehObj1_Cval_MPC "MPC_C24_Pkt";
BA_ "FlexKomSigLaenge" SG_ 2432636287 TurnSgl_VehObj1_Cval_MPC 64;
BA_ "FlexKomSigStartPos" SG_ 2432636287 TurnSgl_VehObj1_Cval_MPC 7;
BA_ "FlexKomSID" SG_ 2432636287 TurnSgl_VehObj1_Cval_MPC 100679835;
BA_ "GenSigStartValue" SG_ 2432636287 TurnSgl_VehObj1_Cval_MPC 7;
BA_ "FlexKomSigStartValue" SG_ 2432636287 TurnSgl_VehObj1_Cval_MPC "EEF0FFFFFFFFFFFFh";
BA_ "GenSigCycleTime" SG_ 2432636287 TurnSgl_VehObj1_Cval_MPC 50;
BA_ "GenSigSNA" SG_ 2432636287 LaneChgInd_VehObj1_Stat_MPC "3h";
BA_ "FlexKomIsMotorola" SG_ 2432636287 LaneChgInd_VehObj1_Stat_MPC 1;
BA_ "FlexKomComment" SG_ 2432636287 LaneChgInd_VehObj1_Stat_MPC "MPC C23 Pkt";
BA_ "FlexKomSigName" SG_ 2432636287 LaneChgInd_VehObj1_Stat_MPC "MPC_C24_Pkt";
BA_ "FlexKomSigLaenge" SG_ 2432636287 LaneChgInd_VehObj1_Stat_MPC 64;
BA_ "FlexKomSigStartPos" SG_ 2432636287 LaneChgInd_VehObj1_Stat_MPC 7;
BA_ "FlexKomSID" SG_ 2432636287 LaneChgInd_VehObj1_Stat_MPC 100679835;
BA_ "GenSigStartValue" SG_ 2432636287 LaneChgInd_VehObj1_Stat_MPC 3;
BA_ "FlexKomSigStartValue" SG_ 2432636287 LaneChgInd_VehObj1_Stat_MPC "EEF0FFFFFFFFFFFFh";
BA_ "GenSigCycleTime" SG_ 2432636287 LaneChgInd_VehObj1_Stat_MPC 50;
BA_ "GenSigSNA" SG_ 2432636543 CRC_SG_MPC_C25_Pkt "BAh";
BA_ "FlexKomIsMotorola" SG_ 2432636543 CRC_SG_MPC_C25_Pkt 1;
BA_ "FlexKomComment" SG_ 2432636543 CRC_SG_MPC_C25_Pkt "MPC C25 Pkt";
BA_ "FlexKomSigName" SG_ 2432636543 CRC_SG_MPC_C25_Pkt "MPC_C25_Pkt";
BA_ "FlexKomSigLaenge" SG_ 2432636543 CRC_SG_MPC_C25_Pkt 64;
BA_ "FlexKomSigStartPos" SG_ 2432636543 CRC_SG_MPC_C25_Pkt 7;
BA_ "FlexKomSID" SG_ 2432636543 CRC_SG_MPC_C25_Pkt 100679836;
BA_ "GenSigStartValue" SG_ 2432636543 CRC_SG_MPC_C25_Pkt 186;
BA_ "FlexKomSigStartValue" SG_ 2432636543 CRC_SG_MPC_C25_Pkt "BAF0FFFFFFFFFFFFh";
BA_ "GenSigCycleTime" SG_ 2432636543 CRC_SG_MPC_C25_Pkt 50;
BA_ "GenSigSNA" SG_ 2432636543 SQC_SG_MPC_C25_Pkt "0h";
BA_ "FlexKomIsMotorola" SG_ 2432636543 SQC_SG_MPC_C25_Pkt 1;
BA_ "FlexKomComment" SG_ 2432636543 SQC_SG_MPC_C25_Pkt "MPC C25 Pkt";
BA_ "FlexKomSigName" SG_ 2432636543 SQC_SG_MPC_C25_Pkt "MPC_C25_Pkt";
BA_ "FlexKomSigLaenge" SG_ 2432636543 SQC_SG_MPC_C25_Pkt 64;
BA_ "FlexKomSigStartPos" SG_ 2432636543 SQC_SG_MPC_C25_Pkt 7;
BA_ "FlexKomSID" SG_ 2432636543 SQC_SG_MPC_C25_Pkt 100679836;
BA_ "FlexKomSigStartValue" SG_ 2432636543 SQC_SG_MPC_C25_Pkt "BAF0FFFFFFFFFFFFh";
BA_ "GenSigCycleTime" SG_ 2432636543 SQC_SG_MPC_C25_Pkt 50;
BA_ "GenSigSNA" SG_ 2432636543 ClassVehObj2_Stat_MPC "Fh";
BA_ "FlexKomIsMotorola" SG_ 2432636543 ClassVehObj2_Stat_MPC 1;
BA_ "FlexKomComment" SG_ 2432636543 ClassVehObj2_Stat_MPC "MPC C25 Pkt";
BA_ "FlexKomSigName" SG_ 2432636543 ClassVehObj2_Stat_MPC "MPC_C25_Pkt";
BA_ "FlexKomSigLaenge" SG_ 2432636543 ClassVehObj2_Stat_MPC 64;
BA_ "FlexKomSigStartPos" SG_ 2432636543 ClassVehObj2_Stat_MPC 7;
BA_ "FlexKomSID" SG_ 2432636543 ClassVehObj2_Stat_MPC 100679836;
BA_ "GenSigStartValue" SG_ 2432636543 ClassVehObj2_Stat_MPC 15;
BA_ "FlexKomSigStartValue" SG_ 2432636543 ClassVehObj2_Stat_MPC "BAF0FFFFFFFFFFFFh";
BA_ "GenSigCycleTime" SG_ 2432636543 ClassVehObj2_Stat_MPC 50;
BA_ "GenSigSNA" SG_ 2432636543 NumVehObj2_Cval_MPC "1Fh";
BA_ "FlexKomIsMotorola" SG_ 2432636543 NumVehObj2_Cval_MPC 1;
BA_ "FlexKomComment" SG_ 2432636543 NumVehObj2_Cval_MPC "MPC C25 Pkt";
BA_ "FlexKomSigName" SG_ 2432636543 NumVehObj2_Cval_MPC "MPC_C25_Pkt";
BA_ "FlexKomSigLaenge" SG_ 2432636543 NumVehObj2_Cval_MPC 64;
BA_ "FlexKomSigStartPos" SG_ 2432636543 NumVehObj2_Cval_MPC 7;
BA_ "FlexKomSID" SG_ 2432636543 NumVehObj2_Cval_MPC 100679836;
BA_ "GenSigStartValue" SG_ 2432636543 NumVehObj2_Cval_MPC 31;
BA_ "FlexKomSigStartValue" SG_ 2432636543 NumVehObj2_Cval_MPC "BAF0FFFFFFFFFFFFh";
BA_ "GenSigCycleTime" SG_ 2432636543 NumVehObj2_Cval_MPC 50;
BA_ "GenSigSNA" SG_ 2432636543 TypeVehObj2_Stat_MPC "7h";
BA_ "FlexKomIsMotorola" SG_ 2432636543 TypeVehObj2_Stat_MPC 1;
BA_ "FlexKomComment" SG_ 2432636543 TypeVehObj2_Stat_MPC "MPC C25 Pkt";
BA_ "FlexKomSigName" SG_ 2432636543 TypeVehObj2_Stat_MPC "MPC_C25_Pkt";
BA_ "FlexKomSigLaenge" SG_ 2432636543 TypeVehObj2_Stat_MPC 64;
BA_ "FlexKomSigStartPos" SG_ 2432636543 TypeVehObj2_Stat_MPC 7;
BA_ "FlexKomSID" SG_ 2432636543 TypeVehObj2_Stat_MPC 100679836;
BA_ "GenSigStartValue" SG_ 2432636543 TypeVehObj2_Stat_MPC 7;
BA_ "FlexKomSigStartValue" SG_ 2432636543 TypeVehObj2_Stat_MPC "BAF0FFFFFFFFFFFFh";
BA_ "GenSigCycleTime" SG_ 2432636543 TypeVehObj2_Stat_MPC 50;
BA_ "GenSigSNA" SG_ 2432636543 StdRng_X_VehObj2_Cval_MPC "3h";
BA_ "FlexKomIsMotorola" SG_ 2432636543 StdRng_X_VehObj2_Cval_MPC 1;
BA_ "FlexKomComment" SG_ 2432636543 StdRng_X_VehObj2_Cval_MPC "MPC C25 Pkt";
BA_ "FlexKomSigName" SG_ 2432636543 StdRng_X_VehObj2_Cval_MPC "MPC_C25_Pkt";
BA_ "FlexKomSigLaenge" SG_ 2432636543 StdRng_X_VehObj2_Cval_MPC 64;
BA_ "FlexKomSigStartPos" SG_ 2432636543 StdRng_X_VehObj2_Cval_MPC 7;
BA_ "FlexKomSID" SG_ 2432636543 StdRng_X_VehObj2_Cval_MPC 100679836;
BA_ "GenSigStartValue" SG_ 2432636543 StdRng_X_VehObj2_Cval_MPC 3;
BA_ "FlexKomSigStartValue" SG_ 2432636543 StdRng_X_VehObj2_Cval_MPC "BAF0FFFFFFFFFFFFh";
BA_ "GenSigCycleTime" SG_ 2432636543 StdRng_X_VehObj2_Cval_MPC 50;
BA_ "GenSigSNA" SG_ 2432636543 StdRng_Y_VehObj2_Cval_MPC "3h";
BA_ "FlexKomIsMotorola" SG_ 2432636543 StdRng_Y_VehObj2_Cval_MPC 1;
BA_ "FlexKomComment" SG_ 2432636543 StdRng_Y_VehObj2_Cval_MPC "MPC C25 Pkt";
BA_ "FlexKomSigName" SG_ 2432636543 StdRng_Y_VehObj2_Cval_MPC "MPC_C25_Pkt";
BA_ "FlexKomSigLaenge" SG_ 2432636543 StdRng_Y_VehObj2_Cval_MPC 64;
BA_ "FlexKomSigStartPos" SG_ 2432636543 StdRng_Y_VehObj2_Cval_MPC 7;
BA_ "FlexKomSID" SG_ 2432636543 StdRng_Y_VehObj2_Cval_MPC 100679836;
BA_ "GenSigStartValue" SG_ 2432636543 StdRng_Y_VehObj2_Cval_MPC 3;
BA_ "FlexKomSigStartValue" SG_ 2432636543 StdRng_Y_VehObj2_Cval_MPC "BAF0FFFFFFFFFFFFh";
BA_ "GenSigCycleTime" SG_ 2432636543 StdRng_Y_VehObj2_Cval_MPC 50;
BA_ "GenSigSNA" SG_ 2432636543 StdRng_Spd_X_VehObj2_Cval_MPC "3h";
BA_ "FlexKomIsMotorola" SG_ 2432636543 StdRng_Spd_X_VehObj2_Cval_MPC 1;
BA_ "FlexKomComment" SG_ 2432636543 StdRng_Spd_X_VehObj2_Cval_MPC "MPC C25 Pkt";
BA_ "FlexKomSigName" SG_ 2432636543 StdRng_Spd_X_VehObj2_Cval_MPC "MPC_C25_Pkt";
BA_ "FlexKomSigLaenge" SG_ 2432636543 StdRng_Spd_X_VehObj2_Cval_MPC 64;
BA_ "FlexKomSigStartPos" SG_ 2432636543 StdRng_Spd_X_VehObj2_Cval_MPC 7;
BA_ "FlexKomSID" SG_ 2432636543 StdRng_Spd_X_VehObj2_Cval_MPC 100679836;
BA_ "GenSigStartValue" SG_ 2432636543 StdRng_Spd_X_VehObj2_Cval_MPC 3;
BA_ "FlexKomSigStartValue" SG_ 2432636543 StdRng_Spd_X_VehObj2_Cval_MPC "BAF0FFFFFFFFFFFFh";
BA_ "GenSigCycleTime" SG_ 2432636543 StdRng_Spd_X_VehObj2_Cval_MPC 50;
BA_ "GenSigSNA" SG_ 2432636543 StdRng_Spd_Y_VehObj2_Cval_MPC "3h";
BA_ "FlexKomIsMotorola" SG_ 2432636543 StdRng_Spd_Y_VehObj2_Cval_MPC 1;
BA_ "FlexKomComment" SG_ 2432636543 StdRng_Spd_Y_VehObj2_Cval_MPC "MPC C25 Pkt";
BA_ "FlexKomSigName" SG_ 2432636543 StdRng_Spd_Y_VehObj2_Cval_MPC "MPC_C25_Pkt";
BA_ "FlexKomSigLaenge" SG_ 2432636543 StdRng_Spd_Y_VehObj2_Cval_MPC 64;
BA_ "FlexKomSigStartPos" SG_ 2432636543 StdRng_Spd_Y_VehObj2_Cval_MPC 7;
BA_ "FlexKomSID" SG_ 2432636543 StdRng_Spd_Y_VehObj2_Cval_MPC 100679836;
BA_ "GenSigStartValue" SG_ 2432636543 StdRng_Spd_Y_VehObj2_Cval_MPC 3;
BA_ "FlexKomSigStartValue" SG_ 2432636543 StdRng_Spd_Y_VehObj2_Cval_MPC "BAF0FFFFFFFFFFFFh";
BA_ "GenSigCycleTime" SG_ 2432636543 StdRng_Spd_Y_VehObj2_Cval_MPC 50;
BA_ "GenSigSNA" SG_ 2432636543 WidthVehObj2_Cval_MPC "FFh";
BA_ "FlexKomIsMotorola" SG_ 2432636543 WidthVehObj2_Cval_MPC 1;
BA_ "FlexKomComment" SG_ 2432636543 WidthVehObj2_Cval_MPC "MPC C25 Pkt";
BA_ "FlexKomSigName" SG_ 2432636543 WidthVehObj2_Cval_MPC "MPC_C25_Pkt";
BA_ "FlexKomSigLaenge" SG_ 2432636543 WidthVehObj2_Cval_MPC 64;
BA_ "FlexKomSigStartPos" SG_ 2432636543 WidthVehObj2_Cval_MPC 7;
BA_ "FlexKomSID" SG_ 2432636543 WidthVehObj2_Cval_MPC 100679836;
BA_ "GenSigStartValue" SG_ 2432636543 WidthVehObj2_Cval_MPC 255;
BA_ "FlexKomSigStartValue" SG_ 2432636543 WidthVehObj2_Cval_MPC "BAF0FFFFFFFFFFFFh";
BA_ "GenSigCycleTime" SG_ 2432636543 WidthVehObj2_Cval_MPC 50;
BA_ "GenSigSNA" SG_ 2432636543 OLA_VehObj2_Cval_MPC "FFh";
BA_ "FlexKomIsMotorola" SG_ 2432636543 OLA_VehObj2_Cval_MPC 1;
BA_ "FlexKomComment" SG_ 2432636543 OLA_VehObj2_Cval_MPC "MPC C25 Pkt";
BA_ "FlexKomSigName" SG_ 2432636543 OLA_VehObj2_Cval_MPC "MPC_C25_Pkt";
BA_ "FlexKomSigLaenge" SG_ 2432636543 OLA_VehObj2_Cval_MPC 64;
BA_ "FlexKomSigStartPos" SG_ 2432636543 OLA_VehObj2_Cval_MPC 7;
BA_ "FlexKomSID" SG_ 2432636543 OLA_VehObj2_Cval_MPC 100679836;
BA_ "GenSigStartValue" SG_ 2432636543 OLA_VehObj2_Cval_MPC 255;
BA_ "FlexKomSigStartValue" SG_ 2432636543 OLA_VehObj2_Cval_MPC "BAF0FFFFFFFFFFFFh";
BA_ "GenSigCycleTime" SG_ 2432636543 OLA_VehObj2_Cval_MPC 50;
BA_ "GenSigSNA" SG_ 2432636543 HeightVehObj2_Cval_MPC "FFh";
BA_ "FlexKomIsMotorola" SG_ 2432636543 HeightVehObj2_Cval_MPC 1;
BA_ "FlexKomComment" SG_ 2432636543 HeightVehObj2_Cval_MPC "MPC C25 Pkt";
BA_ "FlexKomSigName" SG_ 2432636543 HeightVehObj2_Cval_MPC "MPC_C25_Pkt";
BA_ "FlexKomSigLaenge" SG_ 2432636543 HeightVehObj2_Cval_MPC 64;
BA_ "FlexKomSigStartPos" SG_ 2432636543 HeightVehObj2_Cval_MPC 7;
BA_ "FlexKomSID" SG_ 2432636543 HeightVehObj2_Cval_MPC 100679836;
BA_ "GenSigStartValue" SG_ 2432636543 HeightVehObj2_Cval_MPC 255;
BA_ "FlexKomSigStartValue" SG_ 2432636543 HeightVehObj2_Cval_MPC "BAF0FFFFFFFFFFFFh";
BA_ "GenSigCycleTime" SG_ 2432636543 HeightVehObj2_Cval_MPC 50;
BA_ "GenSigSNA" SG_ 2432636543 LaneAlloc_VehObj2_Cval_MPC "7h";
BA_ "FlexKomIsMotorola" SG_ 2432636543 LaneAlloc_VehObj2_Cval_MPC 1;
BA_ "FlexKomComment" SG_ 2432636543 LaneAlloc_VehObj2_Cval_MPC "MPC C25 Pkt";
BA_ "FlexKomSigName" SG_ 2432636543 LaneAlloc_VehObj2_Cval_MPC "MPC_C25_Pkt";
BA_ "FlexKomSigLaenge" SG_ 2432636543 LaneAlloc_VehObj2_Cval_MPC 64;
BA_ "FlexKomSigStartPos" SG_ 2432636543 LaneAlloc_VehObj2_Cval_MPC 7;
BA_ "FlexKomSID" SG_ 2432636543 LaneAlloc_VehObj2_Cval_MPC 100679836;
BA_ "GenSigStartValue" SG_ 2432636543 LaneAlloc_VehObj2_Cval_MPC 7;
BA_ "FlexKomSigStartValue" SG_ 2432636543 LaneAlloc_VehObj2_Cval_MPC "BAF0FFFFFFFFFFFFh";
BA_ "GenSigCycleTime" SG_ 2432636543 LaneAlloc_VehObj2_Cval_MPC 50;
BA_ "GenSigSNA" SG_ 2432636543 TurnSgl_VehObj2_Cval_MPC "7h";
BA_ "FlexKomIsMotorola" SG_ 2432636543 TurnSgl_VehObj2_Cval_MPC 1;
BA_ "FlexKomComment" SG_ 2432636543 TurnSgl_VehObj2_Cval_MPC "MPC C25 Pkt";
BA_ "FlexKomSigName" SG_ 2432636543 TurnSgl_VehObj2_Cval_MPC "MPC_C25_Pkt";
BA_ "FlexKomSigLaenge" SG_ 2432636543 TurnSgl_VehObj2_Cval_MPC 64;
BA_ "FlexKomSigStartPos" SG_ 2432636543 TurnSgl_VehObj2_Cval_MPC 7;
BA_ "FlexKomSID" SG_ 2432636543 TurnSgl_VehObj2_Cval_MPC 100679836;
BA_ "GenSigStartValue" SG_ 2432636543 TurnSgl_VehObj2_Cval_MPC 7;
BA_ "FlexKomSigStartValue" SG_ 2432636543 TurnSgl_VehObj2_Cval_MPC "BAF0FFFFFFFFFFFFh";
BA_ "GenSigCycleTime" SG_ 2432636543 TurnSgl_VehObj2_Cval_MPC 50;
BA_ "GenSigSNA" SG_ 2432636543 LaneChgInd_VehObj2_Stat_MPC "3h";
BA_ "FlexKomIsMotorola" SG_ 2432636543 LaneChgInd_VehObj2_Stat_MPC 1;
BA_ "FlexKomComment" SG_ 2432636543 LaneChgInd_VehObj2_Stat_MPC "MPC C25 Pkt";
BA_ "FlexKomSigName" SG_ 2432636543 LaneChgInd_VehObj2_Stat_MPC "MPC_C25_Pkt";
BA_ "FlexKomSigLaenge" SG_ 2432636543 LaneChgInd_VehObj2_Stat_MPC 64;
BA_ "FlexKomSigStartPos" SG_ 2432636543 LaneChgInd_VehObj2_Stat_MPC 7;
BA_ "FlexKomSID" SG_ 2432636543 LaneChgInd_VehObj2_Stat_MPC 100679836;
BA_ "GenSigStartValue" SG_ 2432636543 LaneChgInd_VehObj2_Stat_MPC 3;
BA_ "FlexKomSigStartValue" SG_ 2432636543 LaneChgInd_VehObj2_Stat_MPC "BAF0FFFFFFFFFFFFh";
BA_ "GenSigCycleTime" SG_ 2432636543 LaneChgInd_VehObj2_Stat_MPC 50;
BA_ "GenSigSNA" SG_ 2432636799 CRC_SG_MPC_C26_Pkt "3Ah";
BA_ "FlexKomIsMotorola" SG_ 2432636799 CRC_SG_MPC_C26_Pkt 1;
BA_ "FlexKomComment" SG_ 2432636799 CRC_SG_MPC_C26_Pkt "MPC C26 Pkt";
BA_ "FlexKomSigName" SG_ 2432636799 CRC_SG_MPC_C26_Pkt "MPC_C26_Pkt";
BA_ "FlexKomSigLaenge" SG_ 2432636799 CRC_SG_MPC_C26_Pkt 64;
BA_ "FlexKomSigStartPos" SG_ 2432636799 CRC_SG_MPC_C26_Pkt 7;
BA_ "FlexKomSID" SG_ 2432636799 CRC_SG_MPC_C26_Pkt 100679838;
BA_ "GenSigStartValue" SG_ 2432636799 CRC_SG_MPC_C26_Pkt 58;
BA_ "FlexKomSigStartValue" SG_ 2432636799 CRC_SG_MPC_C26_Pkt "3AF0FFFFFFFFFFFFh";
BA_ "GenSigCycleTime" SG_ 2432636799 CRC_SG_MPC_C26_Pkt 50;
BA_ "GenSigSNA" SG_ 2432636799 SQC_SG_MPC_C26_Pkt "0h";
BA_ "FlexKomIsMotorola" SG_ 2432636799 SQC_SG_MPC_C26_Pkt 1;
BA_ "FlexKomComment" SG_ 2432636799 SQC_SG_MPC_C26_Pkt "MPC C26 Pkt";
BA_ "FlexKomSigName" SG_ 2432636799 SQC_SG_MPC_C26_Pkt "MPC_C26_Pkt";
BA_ "FlexKomSigLaenge" SG_ 2432636799 SQC_SG_MPC_C26_Pkt 64;
BA_ "FlexKomSigStartPos" SG_ 2432636799 SQC_SG_MPC_C26_Pkt 7;
BA_ "FlexKomSID" SG_ 2432636799 SQC_SG_MPC_C26_Pkt 100679838;
BA_ "FlexKomSigStartValue" SG_ 2432636799 SQC_SG_MPC_C26_Pkt "3AF0FFFFFFFFFFFFh";
BA_ "GenSigCycleTime" SG_ 2432636799 SQC_SG_MPC_C26_Pkt 50;
BA_ "GenSigSNA" SG_ 2432636799 ClassVehObj3_Stat_MPC "Fh";
BA_ "FlexKomIsMotorola" SG_ 2432636799 ClassVehObj3_Stat_MPC 1;
BA_ "FlexKomComment" SG_ 2432636799 ClassVehObj3_Stat_MPC "MPC C26 Pkt";
BA_ "FlexKomSigName" SG_ 2432636799 ClassVehObj3_Stat_MPC "MPC_C26_Pkt";
BA_ "FlexKomSigLaenge" SG_ 2432636799 ClassVehObj3_Stat_MPC 64;
BA_ "FlexKomSigStartPos" SG_ 2432636799 ClassVehObj3_Stat_MPC 7;
BA_ "FlexKomSID" SG_ 2432636799 ClassVehObj3_Stat_MPC 100679838;
BA_ "GenSigStartValue" SG_ 2432636799 ClassVehObj3_Stat_MPC 15;
BA_ "FlexKomSigStartValue" SG_ 2432636799 ClassVehObj3_Stat_MPC "3AF0FFFFFFFFFFFFh";
BA_ "GenSigCycleTime" SG_ 2432636799 ClassVehObj3_Stat_MPC 50;
BA_ "GenSigSNA" SG_ 2432636799 NumVehObj3_Cval_MPC "1Fh";
BA_ "FlexKomIsMotorola" SG_ 2432636799 NumVehObj3_Cval_MPC 1;
BA_ "FlexKomComment" SG_ 2432636799 NumVehObj3_Cval_MPC "MPC C26 Pkt";
BA_ "FlexKomSigName" SG_ 2432636799 NumVehObj3_Cval_MPC "MPC_C26_Pkt";
BA_ "FlexKomSigLaenge" SG_ 2432636799 NumVehObj3_Cval_MPC 64;
BA_ "FlexKomSigStartPos" SG_ 2432636799 NumVehObj3_Cval_MPC 7;
BA_ "FlexKomSID" SG_ 2432636799 NumVehObj3_Cval_MPC 100679838;
BA_ "GenSigStartValue" SG_ 2432636799 NumVehObj3_Cval_MPC 31;
BA_ "FlexKomSigStartValue" SG_ 2432636799 NumVehObj3_Cval_MPC "3AF0FFFFFFFFFFFFh";
BA_ "GenSigCycleTime" SG_ 2432636799 NumVehObj3_Cval_MPC 50;
BA_ "GenSigSNA" SG_ 2432636799 TypeVehObj03_Stat_MPC "7h";
BA_ "FlexKomIsMotorola" SG_ 2432636799 TypeVehObj03_Stat_MPC 1;
BA_ "FlexKomComment" SG_ 2432636799 TypeVehObj03_Stat_MPC "MPC C26 Pkt";
BA_ "FlexKomSigName" SG_ 2432636799 TypeVehObj03_Stat_MPC "MPC_C26_Pkt";
BA_ "FlexKomSigLaenge" SG_ 2432636799 TypeVehObj03_Stat_MPC 64;
BA_ "FlexKomSigStartPos" SG_ 2432636799 TypeVehObj03_Stat_MPC 7;
BA_ "FlexKomSID" SG_ 2432636799 TypeVehObj03_Stat_MPC 100679838;
BA_ "GenSigStartValue" SG_ 2432636799 TypeVehObj03_Stat_MPC 7;
BA_ "FlexKomSigStartValue" SG_ 2432636799 TypeVehObj03_Stat_MPC "3AF0FFFFFFFFFFFFh";
BA_ "GenSigCycleTime" SG_ 2432636799 TypeVehObj03_Stat_MPC 50;
BA_ "GenSigSNA" SG_ 2432636799 StdRng_X_VehObj3_Cval_MPC "3h";
BA_ "FlexKomIsMotorola" SG_ 2432636799 StdRng_X_VehObj3_Cval_MPC 1;
BA_ "FlexKomComment" SG_ 2432636799 StdRng_X_VehObj3_Cval_MPC "MPC C26 Pkt";
BA_ "FlexKomSigName" SG_ 2432636799 StdRng_X_VehObj3_Cval_MPC "MPC_C26_Pkt";
BA_ "FlexKomSigLaenge" SG_ 2432636799 StdRng_X_VehObj3_Cval_MPC 64;
BA_ "FlexKomSigStartPos" SG_ 2432636799 StdRng_X_VehObj3_Cval_MPC 7;
BA_ "FlexKomSID" SG_ 2432636799 StdRng_X_VehObj3_Cval_MPC 100679838;
BA_ "GenSigStartValue" SG_ 2432636799 StdRng_X_VehObj3_Cval_MPC 3;
BA_ "FlexKomSigStartValue" SG_ 2432636799 StdRng_X_VehObj3_Cval_MPC "3AF0FFFFFFFFFFFFh";
BA_ "GenSigCycleTime" SG_ 2432636799 StdRng_X_VehObj3_Cval_MPC 50;
BA_ "GenSigSNA" SG_ 2432636799 StdRng_Y_VehObj3_Cval_MPC "3h";
BA_ "FlexKomIsMotorola" SG_ 2432636799 StdRng_Y_VehObj3_Cval_MPC 1;
BA_ "FlexKomComment" SG_ 2432636799 StdRng_Y_VehObj3_Cval_MPC "MPC C26 Pkt";
BA_ "FlexKomSigName" SG_ 2432636799 StdRng_Y_VehObj3_Cval_MPC "MPC_C26_Pkt";
BA_ "FlexKomSigLaenge" SG_ 2432636799 StdRng_Y_VehObj3_Cval_MPC 64;
BA_ "FlexKomSigStartPos" SG_ 2432636799 StdRng_Y_VehObj3_Cval_MPC 7;
BA_ "FlexKomSID" SG_ 2432636799 StdRng_Y_VehObj3_Cval_MPC 100679838;
BA_ "GenSigStartValue" SG_ 2432636799 StdRng_Y_VehObj3_Cval_MPC 3;
BA_ "FlexKomSigStartValue" SG_ 2432636799 StdRng_Y_VehObj3_Cval_MPC "3AF0FFFFFFFFFFFFh";
BA_ "GenSigCycleTime" SG_ 2432636799 StdRng_Y_VehObj3_Cval_MPC 50;
BA_ "GenSigSNA" SG_ 2432636799 StdRng_Spd_X_VehObj3_Cval_MPC "3h";
BA_ "FlexKomIsMotorola" SG_ 2432636799 StdRng_Spd_X_VehObj3_Cval_MPC 1;
BA_ "FlexKomComment" SG_ 2432636799 StdRng_Spd_X_VehObj3_Cval_MPC "MPC C26 Pkt";
BA_ "FlexKomSigName" SG_ 2432636799 StdRng_Spd_X_VehObj3_Cval_MPC "MPC_C26_Pkt";
BA_ "FlexKomSigLaenge" SG_ 2432636799 StdRng_Spd_X_VehObj3_Cval_MPC 64;
BA_ "FlexKomSigStartPos" SG_ 2432636799 StdRng_Spd_X_VehObj3_Cval_MPC 7;
BA_ "FlexKomSID" SG_ 2432636799 StdRng_Spd_X_VehObj3_Cval_MPC 100679838;
BA_ "GenSigStartValue" SG_ 2432636799 StdRng_Spd_X_VehObj3_Cval_MPC 3;
BA_ "FlexKomSigStartValue" SG_ 2432636799 StdRng_Spd_X_VehObj3_Cval_MPC "3AF0FFFFFFFFFFFFh";
BA_ "GenSigCycleTime" SG_ 2432636799 StdRng_Spd_X_VehObj3_Cval_MPC 50;
BA_ "GenSigSNA" SG_ 2432636799 StdRng_Spd_Y_VehObj3_Cval_MPC "3h";
BA_ "FlexKomIsMotorola" SG_ 2432636799 StdRng_Spd_Y_VehObj3_Cval_MPC 1;
BA_ "FlexKomComment" SG_ 2432636799 StdRng_Spd_Y_VehObj3_Cval_MPC "MPC C26 Pkt";
BA_ "FlexKomSigName" SG_ 2432636799 StdRng_Spd_Y_VehObj3_Cval_MPC "MPC_C26_Pkt";
BA_ "FlexKomSigLaenge" SG_ 2432636799 StdRng_Spd_Y_VehObj3_Cval_MPC 64;
BA_ "FlexKomSigStartPos" SG_ 2432636799 StdRng_Spd_Y_VehObj3_Cval_MPC 7;
BA_ "FlexKomSID" SG_ 2432636799 StdRng_Spd_Y_VehObj3_Cval_MPC 100679838;
BA_ "GenSigStartValue" SG_ 2432636799 StdRng_Spd_Y_VehObj3_Cval_MPC 3;
BA_ "FlexKomSigStartValue" SG_ 2432636799 StdRng_Spd_Y_VehObj3_Cval_MPC "3AF0FFFFFFFFFFFFh";
BA_ "GenSigCycleTime" SG_ 2432636799 StdRng_Spd_Y_VehObj3_Cval_MPC 50;
BA_ "GenSigSNA" SG_ 2432636799 WidthVehObj3_Cval_MPC "FFh";
BA_ "FlexKomIsMotorola" SG_ 2432636799 WidthVehObj3_Cval_MPC 1;
BA_ "FlexKomComment" SG_ 2432636799 WidthVehObj3_Cval_MPC "MPC C26 Pkt";
BA_ "FlexKomSigName" SG_ 2432636799 WidthVehObj3_Cval_MPC "MPC_C26_Pkt";
BA_ "FlexKomSigLaenge" SG_ 2432636799 WidthVehObj3_Cval_MPC 64;
BA_ "FlexKomSigStartPos" SG_ 2432636799 WidthVehObj3_Cval_MPC 7;
BA_ "FlexKomSID" SG_ 2432636799 WidthVehObj3_Cval_MPC 100679838;
BA_ "GenSigStartValue" SG_ 2432636799 WidthVehObj3_Cval_MPC 255;
BA_ "FlexKomSigStartValue" SG_ 2432636799 WidthVehObj3_Cval_MPC "3AF0FFFFFFFFFFFFh";
BA_ "GenSigCycleTime" SG_ 2432636799 WidthVehObj3_Cval_MPC 50;
BA_ "GenSigSNA" SG_ 2432636799 OLA_VehObj3_Cval_MPC "FFh";
BA_ "FlexKomIsMotorola" SG_ 2432636799 OLA_VehObj3_Cval_MPC 1;
BA_ "FlexKomComment" SG_ 2432636799 OLA_VehObj3_Cval_MPC "MPC C26 Pkt";
BA_ "FlexKomSigName" SG_ 2432636799 OLA_VehObj3_Cval_MPC "MPC_C26_Pkt";
BA_ "FlexKomSigLaenge" SG_ 2432636799 OLA_VehObj3_Cval_MPC 64;
BA_ "FlexKomSigStartPos" SG_ 2432636799 OLA_VehObj3_Cval_MPC 7;
BA_ "FlexKomSID" SG_ 2432636799 OLA_VehObj3_Cval_MPC 100679838;
BA_ "GenSigStartValue" SG_ 2432636799 OLA_VehObj3_Cval_MPC 255;
BA_ "FlexKomSigStartValue" SG_ 2432636799 OLA_VehObj3_Cval_MPC "3AF0FFFFFFFFFFFFh";
BA_ "GenSigCycleTime" SG_ 2432636799 OLA_VehObj3_Cval_MPC 50;
BA_ "GenSigSNA" SG_ 2432636799 HeightVehObj3_Cval_MPC "FFh";
BA_ "FlexKomIsMotorola" SG_ 2432636799 HeightVehObj3_Cval_MPC 1;
BA_ "FlexKomComment" SG_ 2432636799 HeightVehObj3_Cval_MPC "MPC C26 Pkt";
BA_ "FlexKomSigName" SG_ 2432636799 HeightVehObj3_Cval_MPC "MPC_C26_Pkt";
BA_ "FlexKomSigLaenge" SG_ 2432636799 HeightVehObj3_Cval_MPC 64;
BA_ "FlexKomSigStartPos" SG_ 2432636799 HeightVehObj3_Cval_MPC 7;
BA_ "FlexKomSID" SG_ 2432636799 HeightVehObj3_Cval_MPC 100679838;
BA_ "GenSigStartValue" SG_ 2432636799 HeightVehObj3_Cval_MPC 255;
BA_ "FlexKomSigStartValue" SG_ 2432636799 HeightVehObj3_Cval_MPC "3AF0FFFFFFFFFFFFh";
BA_ "GenSigCycleTime" SG_ 2432636799 HeightVehObj3_Cval_MPC 50;
BA_ "GenSigSNA" SG_ 2432636799 LaneAlloc_VehObj3_Cval_MPC "7h";
BA_ "FlexKomIsMotorola" SG_ 2432636799 LaneAlloc_VehObj3_Cval_MPC 1;
BA_ "FlexKomComment" SG_ 2432636799 LaneAlloc_VehObj3_Cval_MPC "MPC C26 Pkt";
BA_ "FlexKomSigName" SG_ 2432636799 LaneAlloc_VehObj3_Cval_MPC "MPC_C26_Pkt";
BA_ "FlexKomSigLaenge" SG_ 2432636799 LaneAlloc_VehObj3_Cval_MPC 64;
BA_ "FlexKomSigStartPos" SG_ 2432636799 LaneAlloc_VehObj3_Cval_MPC 7;
BA_ "FlexKomSID" SG_ 2432636799 LaneAlloc_VehObj3_Cval_MPC 100679838;
BA_ "GenSigStartValue" SG_ 2432636799 LaneAlloc_VehObj3_Cval_MPC 7;
BA_ "FlexKomSigStartValue" SG_ 2432636799 LaneAlloc_VehObj3_Cval_MPC "3AF0FFFFFFFFFFFFh";
BA_ "GenSigCycleTime" SG_ 2432636799 LaneAlloc_VehObj3_Cval_MPC 50;
BA_ "GenSigSNA" SG_ 2432636799 TurnSgl_VehObj3_Cval_MPC "7h";
BA_ "FlexKomIsMotorola" SG_ 2432636799 TurnSgl_VehObj3_Cval_MPC 1;
BA_ "FlexKomComment" SG_ 2432636799 TurnSgl_VehObj3_Cval_MPC "MPC C26 Pkt";
BA_ "FlexKomSigName" SG_ 2432636799 TurnSgl_VehObj3_Cval_MPC "MPC_C26_Pkt";
BA_ "FlexKomSigLaenge" SG_ 2432636799 TurnSgl_VehObj3_Cval_MPC 64;
BA_ "FlexKomSigStartPos" SG_ 2432636799 TurnSgl_VehObj3_Cval_MPC 7;
BA_ "FlexKomSID" SG_ 2432636799 TurnSgl_VehObj3_Cval_MPC 100679838;
BA_ "GenSigStartValue" SG_ 2432636799 TurnSgl_VehObj3_Cval_MPC 7;
BA_ "FlexKomSigStartValue" SG_ 2432636799 TurnSgl_VehObj3_Cval_MPC "3AF0FFFFFFFFFFFFh";
BA_ "GenSigCycleTime" SG_ 2432636799 TurnSgl_VehObj3_Cval_MPC 50;
BA_ "GenSigSNA" SG_ 2432636799 LaneChgInd_VehObj3_Stat_MPC "3h";
BA_ "FlexKomIsMotorola" SG_ 2432636799 LaneChgInd_VehObj3_Stat_MPC 1;
BA_ "FlexKomComment" SG_ 2432636799 LaneChgInd_VehObj3_Stat_MPC "MPC C26 Pkt";
BA_ "FlexKomSigName" SG_ 2432636799 LaneChgInd_VehObj3_Stat_MPC "MPC_C26_Pkt";
BA_ "FlexKomSigLaenge" SG_ 2432636799 LaneChgInd_VehObj3_Stat_MPC 64;
BA_ "FlexKomSigStartPos" SG_ 2432636799 LaneChgInd_VehObj3_Stat_MPC 7;
BA_ "FlexKomSID" SG_ 2432636799 LaneChgInd_VehObj3_Stat_MPC 100679838;
BA_ "GenSigStartValue" SG_ 2432636799 LaneChgInd_VehObj3_Stat_MPC 3;
BA_ "FlexKomSigStartValue" SG_ 2432636799 LaneChgInd_VehObj3_Stat_MPC "3AF0FFFFFFFFFFFFh";
BA_ "GenSigCycleTime" SG_ 2432636799 LaneChgInd_VehObj3_Stat_MPC 50;
BA_ "GenSigSNA" SG_ 2432637311 IHC_Tnl1_State_MPC "3h";
BA_ "FlexKomIsMotorola" SG_ 2432637311 IHC_Tnl1_State_MPC 1;
BA_ "FlexKomComment" SG_ 2432637311 IHC_Tnl1_State_MPC "MPC C28 Pkt";
BA_ "FlexKomSigName" SG_ 2432637311 IHC_Tnl1_State_MPC "MPC_C28_Pkt";
BA_ "FlexKomSigLaenge" SG_ 2432637311 IHC_Tnl1_State_MPC 64;
BA_ "FlexKomSigStartPos" SG_ 2432637311 IHC_Tnl1_State_MPC 7;
BA_ "FlexKomSID" SG_ 2432637311 IHC_Tnl1_State_MPC 100679826;
BA_ "GenSigStartValue" SG_ 2432637311 IHC_Tnl1_State_MPC 3;
BA_ "FlexKomSigStartValue" SG_ 2432637311 IHC_Tnl1_State_MPC "FFFFFFFFFFFFFFFFh";
BA_ "GenSigCycleTime" SG_ 2432637311 IHC_Tnl1_State_MPC 50;
BA_ "GenSigSNA" SG_ 2432637311 IHC_Tnl1_ChgOvrLvl_MPC "7h";
BA_ "FlexKomIsMotorola" SG_ 2432637311 IHC_Tnl1_ChgOvrLvl_MPC 1;
BA_ "FlexKomComment" SG_ 2432637311 IHC_Tnl1_ChgOvrLvl_MPC "MPC C28 Pkt";
BA_ "FlexKomSigName" SG_ 2432637311 IHC_Tnl1_ChgOvrLvl_MPC "MPC_C28_Pkt";
BA_ "FlexKomSigLaenge" SG_ 2432637311 IHC_Tnl1_ChgOvrLvl_MPC 64;
BA_ "FlexKomSigStartPos" SG_ 2432637311 IHC_Tnl1_ChgOvrLvl_MPC 7;
BA_ "FlexKomSID" SG_ 2432637311 IHC_Tnl1_ChgOvrLvl_MPC 100679826;
BA_ "GenSigStartValue" SG_ 2432637311 IHC_Tnl1_ChgOvrLvl_MPC 7;
BA_ "FlexKomSigStartValue" SG_ 2432637311 IHC_Tnl1_ChgOvrLvl_MPC "FFFFFFFFFFFFFFFFh";
BA_ "GenSigCycleTime" SG_ 2432637311 IHC_Tnl1_ChgOvrLvl_MPC 50;
BA_ "GenSigSNA" SG_ 2432637311 BotDotRec_Stat "7h";
BA_ "FlexKomIsMotorola" SG_ 2432637311 BotDotRec_Stat 1;
BA_ "FlexKomComment" SG_ 2432637311 BotDotRec_Stat "MPC C28 Pkt";
BA_ "FlexKomSigName" SG_ 2432637311 BotDotRec_Stat "MPC_C28_Pkt";
BA_ "FlexKomSigLaenge" SG_ 2432637311 BotDotRec_Stat 64;
BA_ "FlexKomSigStartPos" SG_ 2432637311 BotDotRec_Stat 7;
BA_ "FlexKomSID" SG_ 2432637311 BotDotRec_Stat 100679826;
BA_ "GenSigStartValue" SG_ 2432637311 BotDotRec_Stat 7;
BA_ "FlexKomSigStartValue" SG_ 2432637311 BotDotRec_Stat "FFFFFFFFFFFFFFFFh";
BA_ "GenSigCycleTime" SG_ 2432637311 BotDotRec_Stat 50;
BA_ "GenSigSNA" SG_ 2432637311 IHC_Tnl1_AngLmtLt_MPC "FFh";
BA_ "FlexKomIsMotorola" SG_ 2432637311 IHC_Tnl1_AngLmtLt_MPC 1;
BA_ "FlexKomComment" SG_ 2432637311 IHC_Tnl1_AngLmtLt_MPC "MPC C28 Pkt";
BA_ "FlexKomSigName" SG_ 2432637311 IHC_Tnl1_AngLmtLt_MPC "MPC_C28_Pkt";
BA_ "FlexKomSigLaenge" SG_ 2432637311 IHC_Tnl1_AngLmtLt_MPC 64;
BA_ "FlexKomSigStartPos" SG_ 2432637311 IHC_Tnl1_AngLmtLt_MPC 7;
BA_ "FlexKomSID" SG_ 2432637311 IHC_Tnl1_AngLmtLt_MPC 100679826;
BA_ "GenSigStartValue" SG_ 2432637311 IHC_Tnl1_AngLmtLt_MPC 255;
BA_ "FlexKomSigStartValue" SG_ 2432637311 IHC_Tnl1_AngLmtLt_MPC "FFFFFFFFFFFFFFFFh";
BA_ "GenSigCycleTime" SG_ 2432637311 IHC_Tnl1_AngLmtLt_MPC 50;
BA_ "GenSigSNA" SG_ 2432637311 IHC_Tnl1_AngLmtRt_MPC "FFh";
BA_ "FlexKomIsMotorola" SG_ 2432637311 IHC_Tnl1_AngLmtRt_MPC 1;
BA_ "FlexKomComment" SG_ 2432637311 IHC_Tnl1_AngLmtRt_MPC "MPC C28 Pkt";
BA_ "FlexKomSigName" SG_ 2432637311 IHC_Tnl1_AngLmtRt_MPC "MPC_C28_Pkt";
BA_ "FlexKomSigLaenge" SG_ 2432637311 IHC_Tnl1_AngLmtRt_MPC 64;
BA_ "FlexKomSigStartPos" SG_ 2432637311 IHC_Tnl1_AngLmtRt_MPC 7;
BA_ "FlexKomSID" SG_ 2432637311 IHC_Tnl1_AngLmtRt_MPC 100679826;
BA_ "GenSigStartValue" SG_ 2432637311 IHC_Tnl1_AngLmtRt_MPC 255;
BA_ "FlexKomSigStartValue" SG_ 2432637311 IHC_Tnl1_AngLmtRt_MPC "FFFFFFFFFFFFFFFFh";
BA_ "GenSigCycleTime" SG_ 2432637311 IHC_Tnl1_AngLmtRt_MPC 50;
BA_ "GenSigSNA" SG_ 2432637311 IHC_Tnl1_ActLgtDist_MPC "FFh";
BA_ "FlexKomIsMotorola" SG_ 2432637311 IHC_Tnl1_ActLgtDist_MPC 1;
BA_ "FlexKomComment" SG_ 2432637311 IHC_Tnl1_ActLgtDist_MPC "MPC C28 Pkt";
BA_ "FlexKomSigName" SG_ 2432637311 IHC_Tnl1_ActLgtDist_MPC "MPC_C28_Pkt";
BA_ "FlexKomSigLaenge" SG_ 2432637311 IHC_Tnl1_ActLgtDist_MPC 64;
BA_ "FlexKomSigStartPos" SG_ 2432637311 IHC_Tnl1_ActLgtDist_MPC 7;
BA_ "FlexKomSID" SG_ 2432637311 IHC_Tnl1_ActLgtDist_MPC 100679826;
BA_ "GenSigStartValue" SG_ 2432637311 IHC_Tnl1_ActLgtDist_MPC 255;
BA_ "FlexKomSigStartValue" SG_ 2432637311 IHC_Tnl1_ActLgtDist_MPC "FFFFFFFFFFFFFFFFh";
BA_ "GenSigCycleTime" SG_ 2432637311 IHC_Tnl1_ActLgtDist_MPC 50;
BA_ "GenSigSNA" SG_ 2432637311 IHC_Tnl2_State_MPC "3h";
BA_ "FlexKomIsMotorola" SG_ 2432637311 IHC_Tnl2_State_MPC 1;
BA_ "FlexKomComment" SG_ 2432637311 IHC_Tnl2_State_MPC "MPC C28 Pkt";
BA_ "FlexKomSigName" SG_ 2432637311 IHC_Tnl2_State_MPC "MPC_C28_Pkt";
BA_ "FlexKomSigLaenge" SG_ 2432637311 IHC_Tnl2_State_MPC 64;
BA_ "FlexKomSigStartPos" SG_ 2432637311 IHC_Tnl2_State_MPC 7;
BA_ "FlexKomSID" SG_ 2432637311 IHC_Tnl2_State_MPC 100679826;
BA_ "GenSigStartValue" SG_ 2432637311 IHC_Tnl2_State_MPC 3;
BA_ "FlexKomSigStartValue" SG_ 2432637311 IHC_Tnl2_State_MPC "FFFFFFFFFFFFFFFFh";
BA_ "GenSigCycleTime" SG_ 2432637311 IHC_Tnl2_State_MPC 50;
BA_ "GenSigSNA" SG_ 2432637311 IHC_Tnl2_ChgOvrLvl_MPC "7h";
BA_ "FlexKomIsMotorola" SG_ 2432637311 IHC_Tnl2_ChgOvrLvl_MPC 1;
BA_ "FlexKomComment" SG_ 2432637311 IHC_Tnl2_ChgOvrLvl_MPC "MPC C28 Pkt";
BA_ "FlexKomSigName" SG_ 2432637311 IHC_Tnl2_ChgOvrLvl_MPC "MPC_C28_Pkt";
BA_ "FlexKomSigLaenge" SG_ 2432637311 IHC_Tnl2_ChgOvrLvl_MPC 64;
BA_ "FlexKomSigStartPos" SG_ 2432637311 IHC_Tnl2_ChgOvrLvl_MPC 7;
BA_ "FlexKomSID" SG_ 2432637311 IHC_Tnl2_ChgOvrLvl_MPC 100679826;
BA_ "GenSigStartValue" SG_ 2432637311 IHC_Tnl2_ChgOvrLvl_MPC 7;
BA_ "FlexKomSigStartValue" SG_ 2432637311 IHC_Tnl2_ChgOvrLvl_MPC "FFFFFFFFFFFFFFFFh";
BA_ "GenSigCycleTime" SG_ 2432637311 IHC_Tnl2_ChgOvrLvl_MPC 50;
BA_ "GenSigSNA" SG_ 2432637311 WarnPoleRec_Stat "7h";
BA_ "FlexKomIsMotorola" SG_ 2432637311 WarnPoleRec_Stat 1;
BA_ "FlexKomComment" SG_ 2432637311 WarnPoleRec_Stat "MPC C28 Pkt";
BA_ "FlexKomSigName" SG_ 2432637311 WarnPoleRec_Stat "MPC_C28_Pkt";
BA_ "FlexKomSigLaenge" SG_ 2432637311 WarnPoleRec_Stat 64;
BA_ "FlexKomSigStartPos" SG_ 2432637311 WarnPoleRec_Stat 7;
BA_ "FlexKomSID" SG_ 2432637311 WarnPoleRec_Stat 100679826;
BA_ "GenSigStartValue" SG_ 2432637311 WarnPoleRec_Stat 7;
BA_ "FlexKomSigStartValue" SG_ 2432637311 WarnPoleRec_Stat "FFFFFFFFFFFFFFFFh";
BA_ "GenSigCycleTime" SG_ 2432637311 WarnPoleRec_Stat 50;
BA_ "GenSigSNA" SG_ 2432637311 IHC_Tnl2_AngLmtLt_MPC "FFh";
BA_ "FlexKomIsMotorola" SG_ 2432637311 IHC_Tnl2_AngLmtLt_MPC 1;
BA_ "FlexKomComment" SG_ 2432637311 IHC_Tnl2_AngLmtLt_MPC "MPC C28 Pkt";
BA_ "FlexKomSigName" SG_ 2432637311 IHC_Tnl2_AngLmtLt_MPC "MPC_C28_Pkt";
BA_ "FlexKomSigLaenge" SG_ 2432637311 IHC_Tnl2_AngLmtLt_MPC 64;
BA_ "FlexKomSigStartPos" SG_ 2432637311 IHC_Tnl2_AngLmtLt_MPC 7;
BA_ "FlexKomSID" SG_ 2432637311 IHC_Tnl2_AngLmtLt_MPC 100679826;
BA_ "GenSigStartValue" SG_ 2432637311 IHC_Tnl2_AngLmtLt_MPC 255;
BA_ "FlexKomSigStartValue" SG_ 2432637311 IHC_Tnl2_AngLmtLt_MPC "FFFFFFFFFFFFFFFFh";
BA_ "GenSigCycleTime" SG_ 2432637311 IHC_Tnl2_AngLmtLt_MPC 50;
BA_ "GenSigSNA" SG_ 2432637311 IHC_Tnl2_AngLmtRt_MPC "FFh";
BA_ "FlexKomIsMotorola" SG_ 2432637311 IHC_Tnl2_AngLmtRt_MPC 1;
BA_ "FlexKomComment" SG_ 2432637311 IHC_Tnl2_AngLmtRt_MPC "MPC C28 Pkt";
BA_ "FlexKomSigName" SG_ 2432637311 IHC_Tnl2_AngLmtRt_MPC "MPC_C28_Pkt";
BA_ "FlexKomSigLaenge" SG_ 2432637311 IHC_Tnl2_AngLmtRt_MPC 64;
BA_ "FlexKomSigStartPos" SG_ 2432637311 IHC_Tnl2_AngLmtRt_MPC 7;
BA_ "FlexKomSID" SG_ 2432637311 IHC_Tnl2_AngLmtRt_MPC 100679826;
BA_ "GenSigStartValue" SG_ 2432637311 IHC_Tnl2_AngLmtRt_MPC 255;
BA_ "FlexKomSigStartValue" SG_ 2432637311 IHC_Tnl2_AngLmtRt_MPC "FFFFFFFFFFFFFFFFh";
BA_ "GenSigCycleTime" SG_ 2432637311 IHC_Tnl2_AngLmtRt_MPC 50;
BA_ "GenSigSNA" SG_ 2432637311 IHC_Tnl2_ActLgtDist_MPC "FFh";
BA_ "FlexKomIsMotorola" SG_ 2432637311 IHC_Tnl2_ActLgtDist_MPC 1;
BA_ "FlexKomComment" SG_ 2432637311 IHC_Tnl2_ActLgtDist_MPC "MPC C28 Pkt";
BA_ "FlexKomSigName" SG_ 2432637311 IHC_Tnl2_ActLgtDist_MPC "MPC_C28_Pkt";
BA_ "FlexKomSigLaenge" SG_ 2432637311 IHC_Tnl2_ActLgtDist_MPC 64;
BA_ "FlexKomSigStartPos" SG_ 2432637311 IHC_Tnl2_ActLgtDist_MPC 7;
BA_ "FlexKomSID" SG_ 2432637311 IHC_Tnl2_ActLgtDist_MPC 100679826;
BA_ "GenSigStartValue" SG_ 2432637311 IHC_Tnl2_ActLgtDist_MPC 255;
BA_ "FlexKomSigStartValue" SG_ 2432637311 IHC_Tnl2_ActLgtDist_MPC "FFFFFFFFFFFFFFFFh";
BA_ "GenSigCycleTime" SG_ 2432637311 IHC_Tnl2_ActLgtDist_MPC 50;
BA_ "GenSigSNA" SG_ 2432637567 CRC_SG_MPC_C30_Pkt "4Dh";
BA_ "FlexKomIsMotorola" SG_ 2432637567 CRC_SG_MPC_C30_Pkt 1;
BA_ "FlexKomComment" SG_ 2432637567 CRC_SG_MPC_C30_Pkt "MPC_C30_Pkt";
BA_ "FlexKomSigName" SG_ 2432637567 CRC_SG_MPC_C30_Pkt "MPC_C30_Pkt";
BA_ "FlexKomSigLaenge" SG_ 2432637567 CRC_SG_MPC_C30_Pkt 64;
BA_ "FlexKomSigStartPos" SG_ 2432637567 CRC_SG_MPC_C30_Pkt 7;
BA_ "FlexKomSID" SG_ 2432637567 CRC_SG_MPC_C30_Pkt 100680308;
BA_ "GenSigStartValue" SG_ 2432637567 CRC_SG_MPC_C30_Pkt 77;
BA_ "FlexKomSigStartValue" SG_ 2432637567 CRC_SG_MPC_C30_Pkt "4DF0FFFFFFFFFFFFh";
BA_ "GenSigCycleTime" SG_ 2432637567 CRC_SG_MPC_C30_Pkt 50;
BA_ "GenSigSNA" SG_ 2432637567 SQC_SG_MPC_C30_Pkt "0h";
BA_ "FlexKomIsMotorola" SG_ 2432637567 SQC_SG_MPC_C30_Pkt 1;
BA_ "FlexKomComment" SG_ 2432637567 SQC_SG_MPC_C30_Pkt "MPC_C30_Pkt";
BA_ "FlexKomSigName" SG_ 2432637567 SQC_SG_MPC_C30_Pkt "MPC_C30_Pkt";
BA_ "FlexKomSigLaenge" SG_ 2432637567 SQC_SG_MPC_C30_Pkt 64;
BA_ "FlexKomSigStartPos" SG_ 2432637567 SQC_SG_MPC_C30_Pkt 7;
BA_ "FlexKomSID" SG_ 2432637567 SQC_SG_MPC_C30_Pkt 100680308;
BA_ "FlexKomSigStartValue" SG_ 2432637567 SQC_SG_MPC_C30_Pkt "4DF0FFFFFFFFFFFFh";
BA_ "GenSigCycleTime" SG_ 2432637567 SQC_SG_MPC_C30_Pkt 50;
BA_ "GenSigSNA" SG_ 2432637567 AnglLt_PedObj0_Cval_MPC "FFFFh";
BA_ "FlexKomIsMotorola" SG_ 2432637567 AnglLt_PedObj0_Cval_MPC 1;
BA_ "FlexKomComment" SG_ 2432637567 AnglLt_PedObj0_Cval_MPC "MPC_C30_Pkt";
BA_ "FlexKomSigName" SG_ 2432637567 AnglLt_PedObj0_Cval_MPC "MPC_C30_Pkt";
BA_ "FlexKomSigLaenge" SG_ 2432637567 AnglLt_PedObj0_Cval_MPC 64;
BA_ "FlexKomSigStartPos" SG_ 2432637567 AnglLt_PedObj0_Cval_MPC 7;
BA_ "FlexKomSID" SG_ 2432637567 AnglLt_PedObj0_Cval_MPC 100680308;
BA_ "GenSigStartValue" SG_ 2432637567 AnglLt_PedObj0_Cval_MPC 65535;
BA_ "FlexKomSigStartValue" SG_ 2432637567 AnglLt_PedObj0_Cval_MPC "4DF0FFFFFFFFFFFFh";
BA_ "GenSigCycleTime" SG_ 2432637567 AnglLt_PedObj0_Cval_MPC 50;
BA_ "GenSigSNA" SG_ 2432637567 AnglRt_PedObj0_Cval_MPC "FFFFh";
BA_ "FlexKomIsMotorola" SG_ 2432637567 AnglRt_PedObj0_Cval_MPC 1;
BA_ "FlexKomComment" SG_ 2432637567 AnglRt_PedObj0_Cval_MPC "MPC_C30_Pkt";
BA_ "FlexKomSigName" SG_ 2432637567 AnglRt_PedObj0_Cval_MPC "MPC_C30_Pkt";
BA_ "FlexKomSigLaenge" SG_ 2432637567 AnglRt_PedObj0_Cval_MPC 64;
BA_ "FlexKomSigStartPos" SG_ 2432637567 AnglRt_PedObj0_Cval_MPC 7;
BA_ "FlexKomSID" SG_ 2432637567 AnglRt_PedObj0_Cval_MPC 100680308;
BA_ "GenSigStartValue" SG_ 2432637567 AnglRt_PedObj0_Cval_MPC 65535;
BA_ "FlexKomSigStartValue" SG_ 2432637567 AnglRt_PedObj0_Cval_MPC "4DF0FFFFFFFFFFFFh";
BA_ "GenSigCycleTime" SG_ 2432637567 AnglRt_PedObj0_Cval_MPC 50;
BA_ "GenSigSNA" SG_ 2432637567 SclFctr_PedObj0_Cval_MPC "FFFFh";
BA_ "FlexKomIsMotorola" SG_ 2432637567 SclFctr_PedObj0_Cval_MPC 1;
BA_ "FlexKomComment" SG_ 2432637567 SclFctr_PedObj0_Cval_MPC "MPC_C30_Pkt";
BA_ "FlexKomSigName" SG_ 2432637567 SclFctr_PedObj0_Cval_MPC "MPC_C30_Pkt";
BA_ "FlexKomSigLaenge" SG_ 2432637567 SclFctr_PedObj0_Cval_MPC 64;
BA_ "FlexKomSigStartPos" SG_ 2432637567 SclFctr_PedObj0_Cval_MPC 7;
BA_ "FlexKomSID" SG_ 2432637567 SclFctr_PedObj0_Cval_MPC 100680308;
BA_ "GenSigStartValue" SG_ 2432637567 SclFctr_PedObj0_Cval_MPC 65535;
BA_ "FlexKomSigStartValue" SG_ 2432637567 SclFctr_PedObj0_Cval_MPC "4DF0FFFFFFFFFFFFh";
BA_ "GenSigCycleTime" SG_ 2432637567 SclFctr_PedObj0_Cval_MPC 50;
BA_ "GenSigSNA" SG_ 2432637823 CRC_SG_MPC_C31_Pkt "ADh";
BA_ "FlexKomIsMotorola" SG_ 2432637823 CRC_SG_MPC_C31_Pkt 1;
BA_ "FlexKomComment" SG_ 2432637823 CRC_SG_MPC_C31_Pkt "MPC_C31_Pkt";
BA_ "FlexKomSigName" SG_ 2432637823 CRC_SG_MPC_C31_Pkt "MPC_C31_Pkt";
BA_ "FlexKomSigLaenge" SG_ 2432637823 CRC_SG_MPC_C31_Pkt 64;
BA_ "FlexKomSigStartPos" SG_ 2432637823 CRC_SG_MPC_C31_Pkt 7;
BA_ "FlexKomSID" SG_ 2432637823 CRC_SG_MPC_C31_Pkt 100680309;
BA_ "GenSigStartValue" SG_ 2432637823 CRC_SG_MPC_C31_Pkt 173;
BA_ "FlexKomSigStartValue" SG_ 2432637823 CRC_SG_MPC_C31_Pkt "ADF0FFFFFFFFFFFFh";
BA_ "GenSigCycleTime" SG_ 2432637823 CRC_SG_MPC_C31_Pkt 50;
BA_ "GenSigSNA" SG_ 2432637823 SQC_SG_MPC_C31_Pkt "0h";
BA_ "FlexKomIsMotorola" SG_ 2432637823 SQC_SG_MPC_C31_Pkt 1;
BA_ "FlexKomComment" SG_ 2432637823 SQC_SG_MPC_C31_Pkt "MPC_C31_Pkt";
BA_ "FlexKomSigName" SG_ 2432637823 SQC_SG_MPC_C31_Pkt "MPC_C31_Pkt";
BA_ "FlexKomSigLaenge" SG_ 2432637823 SQC_SG_MPC_C31_Pkt 64;
BA_ "FlexKomSigStartPos" SG_ 2432637823 SQC_SG_MPC_C31_Pkt 7;
BA_ "FlexKomSID" SG_ 2432637823 SQC_SG_MPC_C31_Pkt 100680309;
BA_ "FlexKomSigStartValue" SG_ 2432637823 SQC_SG_MPC_C31_Pkt "ADF0FFFFFFFFFFFFh";
BA_ "GenSigCycleTime" SG_ 2432637823 SQC_SG_MPC_C31_Pkt 50;
BA_ "GenSigSNA" SG_ 2432637823 AnglLt_PedObj1_Cval_MPC "FFFFh";
BA_ "FlexKomIsMotorola" SG_ 2432637823 AnglLt_PedObj1_Cval_MPC 1;
BA_ "FlexKomComment" SG_ 2432637823 AnglLt_PedObj1_Cval_MPC "MPC_C31_Pkt";
BA_ "FlexKomSigName" SG_ 2432637823 AnglLt_PedObj1_Cval_MPC "MPC_C31_Pkt";
BA_ "FlexKomSigLaenge" SG_ 2432637823 AnglLt_PedObj1_Cval_MPC 64;
BA_ "FlexKomSigStartPos" SG_ 2432637823 AnglLt_PedObj1_Cval_MPC 7;
BA_ "FlexKomSID" SG_ 2432637823 AnglLt_PedObj1_Cval_MPC 100680309;
BA_ "GenSigStartValue" SG_ 2432637823 AnglLt_PedObj1_Cval_MPC 65535;
BA_ "FlexKomSigStartValue" SG_ 2432637823 AnglLt_PedObj1_Cval_MPC "ADF0FFFFFFFFFFFFh";
BA_ "GenSigCycleTime" SG_ 2432637823 AnglLt_PedObj1_Cval_MPC 50;
BA_ "GenSigSNA" SG_ 2432637823 AnglRt_PedObj1_Cval_MPC "FFFFh";
BA_ "FlexKomIsMotorola" SG_ 2432637823 AnglRt_PedObj1_Cval_MPC 1;
BA_ "FlexKomComment" SG_ 2432637823 AnglRt_PedObj1_Cval_MPC "MPC_C31_Pkt";
BA_ "FlexKomSigName" SG_ 2432637823 AnglRt_PedObj1_Cval_MPC "MPC_C31_Pkt";
BA_ "FlexKomSigLaenge" SG_ 2432637823 AnglRt_PedObj1_Cval_MPC 64;
BA_ "FlexKomSigStartPos" SG_ 2432637823 AnglRt_PedObj1_Cval_MPC 7;
BA_ "FlexKomSID" SG_ 2432637823 AnglRt_PedObj1_Cval_MPC 100680309;
BA_ "GenSigStartValue" SG_ 2432637823 AnglRt_PedObj1_Cval_MPC 65535;
BA_ "FlexKomSigStartValue" SG_ 2432637823 AnglRt_PedObj1_Cval_MPC "ADF0FFFFFFFFFFFFh";
BA_ "GenSigCycleTime" SG_ 2432637823 AnglRt_PedObj1_Cval_MPC 50;
BA_ "GenSigSNA" SG_ 2432637823 SclFctr_PedObj1_Cval_MPC "FFFFh";
BA_ "FlexKomIsMotorola" SG_ 2432637823 SclFctr_PedObj1_Cval_MPC 1;
BA_ "FlexKomComment" SG_ 2432637823 SclFctr_PedObj1_Cval_MPC "MPC_C31_Pkt";
BA_ "FlexKomSigName" SG_ 2432637823 SclFctr_PedObj1_Cval_MPC "MPC_C31_Pkt";
BA_ "FlexKomSigLaenge" SG_ 2432637823 SclFctr_PedObj1_Cval_MPC 64;
BA_ "FlexKomSigStartPos" SG_ 2432637823 SclFctr_PedObj1_Cval_MPC 7;
BA_ "FlexKomSID" SG_ 2432637823 SclFctr_PedObj1_Cval_MPC 100680309;
BA_ "GenSigStartValue" SG_ 2432637823 SclFctr_PedObj1_Cval_MPC 65535;
BA_ "FlexKomSigStartValue" SG_ 2432637823 SclFctr_PedObj1_Cval_MPC "ADF0FFFFFFFFFFFFh";
BA_ "GenSigCycleTime" SG_ 2432637823 SclFctr_PedObj1_Cval_MPC 50;
BA_ "GenSigSNA" SG_ 2432638079 CRC_SG_MPC_C32_Pkt "53h";
BA_ "FlexKomIsMotorola" SG_ 2432638079 CRC_SG_MPC_C32_Pkt 1;
BA_ "FlexKomComment" SG_ 2432638079 CRC_SG_MPC_C32_Pkt "MPC_C32_Pkt";
BA_ "FlexKomSigName" SG_ 2432638079 CRC_SG_MPC_C32_Pkt "MPC_C32_Pkt";
BA_ "FlexKomSigLaenge" SG_ 2432638079 CRC_SG_MPC_C32_Pkt 64;
BA_ "FlexKomSigStartPos" SG_ 2432638079 CRC_SG_MPC_C32_Pkt 7;
BA_ "FlexKomSID" SG_ 2432638079 CRC_SG_MPC_C32_Pkt 100680310;
BA_ "GenSigStartValue" SG_ 2432638079 CRC_SG_MPC_C32_Pkt 83;
BA_ "FlexKomSigStartValue" SG_ 2432638079 CRC_SG_MPC_C32_Pkt "53F0FFFFFFFFFFFFh";
BA_ "GenSigCycleTime" SG_ 2432638079 CRC_SG_MPC_C32_Pkt 50;
BA_ "GenSigSNA" SG_ 2432638079 SQC_SG_MPC_C32_Pkt "0h";
BA_ "FlexKomIsMotorola" SG_ 2432638079 SQC_SG_MPC_C32_Pkt 1;
BA_ "FlexKomComment" SG_ 2432638079 SQC_SG_MPC_C32_Pkt "MPC_C32_Pkt";
BA_ "FlexKomSigName" SG_ 2432638079 SQC_SG_MPC_C32_Pkt "MPC_C32_Pkt";
BA_ "FlexKomSigLaenge" SG_ 2432638079 SQC_SG_MPC_C32_Pkt 64;
BA_ "FlexKomSigStartPos" SG_ 2432638079 SQC_SG_MPC_C32_Pkt 7;
BA_ "FlexKomSID" SG_ 2432638079 SQC_SG_MPC_C32_Pkt 100680310;
BA_ "FlexKomSigStartValue" SG_ 2432638079 SQC_SG_MPC_C32_Pkt "53F0FFFFFFFFFFFFh";
BA_ "GenSigCycleTime" SG_ 2432638079 SQC_SG_MPC_C32_Pkt 50;
BA_ "GenSigSNA" SG_ 2432638079 AnglLt_PedObj2_Cval_MPC "FFFFh";
BA_ "FlexKomIsMotorola" SG_ 2432638079 AnglLt_PedObj2_Cval_MPC 1;
BA_ "FlexKomComment" SG_ 2432638079 AnglLt_PedObj2_Cval_MPC "MPC_C32_Pkt";
BA_ "FlexKomSigName" SG_ 2432638079 AnglLt_PedObj2_Cval_MPC "MPC_C32_Pkt";
BA_ "FlexKomSigLaenge" SG_ 2432638079 AnglLt_PedObj2_Cval_MPC 64;
BA_ "FlexKomSigStartPos" SG_ 2432638079 AnglLt_PedObj2_Cval_MPC 7;
BA_ "FlexKomSID" SG_ 2432638079 AnglLt_PedObj2_Cval_MPC 100680310;
BA_ "GenSigStartValue" SG_ 2432638079 AnglLt_PedObj2_Cval_MPC 65535;
BA_ "FlexKomSigStartValue" SG_ 2432638079 AnglLt_PedObj2_Cval_MPC "53F0FFFFFFFFFFFFh";
BA_ "GenSigCycleTime" SG_ 2432638079 AnglLt_PedObj2_Cval_MPC 50;
BA_ "GenSigSNA" SG_ 2432638079 AnglRt_PedObj2_Cval_MPC "FFFFh";
BA_ "FlexKomIsMotorola" SG_ 2432638079 AnglRt_PedObj2_Cval_MPC 1;
BA_ "FlexKomComment" SG_ 2432638079 AnglRt_PedObj2_Cval_MPC "MPC_C32_Pkt";
BA_ "FlexKomSigName" SG_ 2432638079 AnglRt_PedObj2_Cval_MPC "MPC_C32_Pkt";
BA_ "FlexKomSigLaenge" SG_ 2432638079 AnglRt_PedObj2_Cval_MPC 64;
BA_ "FlexKomSigStartPos" SG_ 2432638079 AnglRt_PedObj2_Cval_MPC 7;
BA_ "FlexKomSID" SG_ 2432638079 AnglRt_PedObj2_Cval_MPC 100680310;
BA_ "GenSigStartValue" SG_ 2432638079 AnglRt_PedObj2_Cval_MPC 65535;
BA_ "FlexKomSigStartValue" SG_ 2432638079 AnglRt_PedObj2_Cval_MPC "53F0FFFFFFFFFFFFh";
BA_ "GenSigCycleTime" SG_ 2432638079 AnglRt_PedObj2_Cval_MPC 50;
BA_ "GenSigSNA" SG_ 2432638079 SclFctr_PedObj2_Cval_MPC "FFFFh";
BA_ "FlexKomIsMotorola" SG_ 2432638079 SclFctr_PedObj2_Cval_MPC 1;
BA_ "FlexKomComment" SG_ 2432638079 SclFctr_PedObj2_Cval_MPC "MPC_C32_Pkt";
BA_ "FlexKomSigName" SG_ 2432638079 SclFctr_PedObj2_Cval_MPC "MPC_C32_Pkt";
BA_ "FlexKomSigLaenge" SG_ 2432638079 SclFctr_PedObj2_Cval_MPC 64;
BA_ "FlexKomSigStartPos" SG_ 2432638079 SclFctr_PedObj2_Cval_MPC 7;
BA_ "FlexKomSID" SG_ 2432638079 SclFctr_PedObj2_Cval_MPC 100680310;
BA_ "GenSigStartValue" SG_ 2432638079 SclFctr_PedObj2_Cval_MPC 65535;
BA_ "FlexKomSigStartValue" SG_ 2432638079 SclFctr_PedObj2_Cval_MPC "53F0FFFFFFFFFFFFh";
BA_ "GenSigCycleTime" SG_ 2432638079 SclFctr_PedObj2_Cval_MPC 50;
BA_ "GenSigSNA" SG_ 2432638335 CRC_SG_MPC_C33_Pkt "D9h";
BA_ "FlexKomIsMotorola" SG_ 2432638335 CRC_SG_MPC_C33_Pkt 1;
BA_ "FlexKomComment" SG_ 2432638335 CRC_SG_MPC_C33_Pkt "MPC_C33_Pkt";
BA_ "FlexKomSigName" SG_ 2432638335 CRC_SG_MPC_C33_Pkt "MPC_C33_Pkt";
BA_ "FlexKomSigLaenge" SG_ 2432638335 CRC_SG_MPC_C33_Pkt 64;
BA_ "FlexKomSigStartPos" SG_ 2432638335 CRC_SG_MPC_C33_Pkt 7;
BA_ "FlexKomSID" SG_ 2432638335 CRC_SG_MPC_C33_Pkt 100680311;
BA_ "GenSigStartValue" SG_ 2432638335 CRC_SG_MPC_C33_Pkt 217;
BA_ "FlexKomSigStartValue" SG_ 2432638335 CRC_SG_MPC_C33_Pkt "D9F0FFFFFFFFFFFFh";
BA_ "GenSigCycleTime" SG_ 2432638335 CRC_SG_MPC_C33_Pkt 50;
BA_ "GenSigSNA" SG_ 2432638335 SQC_SG_MPC_C33_Pkt "0h";
BA_ "FlexKomIsMotorola" SG_ 2432638335 SQC_SG_MPC_C33_Pkt 1;
BA_ "FlexKomComment" SG_ 2432638335 SQC_SG_MPC_C33_Pkt "MPC_C33_Pkt";
BA_ "FlexKomSigName" SG_ 2432638335 SQC_SG_MPC_C33_Pkt "MPC_C33_Pkt";
BA_ "FlexKomSigLaenge" SG_ 2432638335 SQC_SG_MPC_C33_Pkt 64;
BA_ "FlexKomSigStartPos" SG_ 2432638335 SQC_SG_MPC_C33_Pkt 7;
BA_ "FlexKomSID" SG_ 2432638335 SQC_SG_MPC_C33_Pkt 100680311;
BA_ "FlexKomSigStartValue" SG_ 2432638335 SQC_SG_MPC_C33_Pkt "D9F0FFFFFFFFFFFFh";
BA_ "GenSigCycleTime" SG_ 2432638335 SQC_SG_MPC_C33_Pkt 50;
BA_ "GenSigSNA" SG_ 2432638335 AnglLt_PedObj3_Cval_MPC "FFFFh";
BA_ "FlexKomIsMotorola" SG_ 2432638335 AnglLt_PedObj3_Cval_MPC 1;
BA_ "FlexKomComment" SG_ 2432638335 AnglLt_PedObj3_Cval_MPC "MPC_C33_Pkt";
BA_ "FlexKomSigName" SG_ 2432638335 AnglLt_PedObj3_Cval_MPC "MPC_C33_Pkt";
BA_ "FlexKomSigLaenge" SG_ 2432638335 AnglLt_PedObj3_Cval_MPC 64;
BA_ "FlexKomSigStartPos" SG_ 2432638335 AnglLt_PedObj3_Cval_MPC 7;
BA_ "FlexKomSID" SG_ 2432638335 AnglLt_PedObj3_Cval_MPC 100680311;
BA_ "GenSigStartValue" SG_ 2432638335 AnglLt_PedObj3_Cval_MPC 65535;
BA_ "FlexKomSigStartValue" SG_ 2432638335 AnglLt_PedObj3_Cval_MPC "D9F0FFFFFFFFFFFFh";
BA_ "GenSigCycleTime" SG_ 2432638335 AnglLt_PedObj3_Cval_MPC 50;
BA_ "GenSigSNA" SG_ 2432638335 AnglRt_PedObj3_Cval_MPC "FFFFh";
BA_ "FlexKomIsMotorola" SG_ 2432638335 AnglRt_PedObj3_Cval_MPC 1;
BA_ "FlexKomComment" SG_ 2432638335 AnglRt_PedObj3_Cval_MPC "MPC_C33_Pkt";
BA_ "FlexKomSigName" SG_ 2432638335 AnglRt_PedObj3_Cval_MPC "MPC_C33_Pkt";
BA_ "FlexKomSigLaenge" SG_ 2432638335 AnglRt_PedObj3_Cval_MPC 64;
BA_ "FlexKomSigStartPos" SG_ 2432638335 AnglRt_PedObj3_Cval_MPC 7;
BA_ "FlexKomSID" SG_ 2432638335 AnglRt_PedObj3_Cval_MPC 100680311;
BA_ "GenSigStartValue" SG_ 2432638335 AnglRt_PedObj3_Cval_MPC 65535;
BA_ "FlexKomSigStartValue" SG_ 2432638335 AnglRt_PedObj3_Cval_MPC "D9F0FFFFFFFFFFFFh";
BA_ "GenSigCycleTime" SG_ 2432638335 AnglRt_PedObj3_Cval_MPC 50;
BA_ "GenSigSNA" SG_ 2432638335 SclFctr_PedObj3_Cval_MPC "FFFFh";
BA_ "FlexKomIsMotorola" SG_ 2432638335 SclFctr_PedObj3_Cval_MPC 1;
BA_ "FlexKomComment" SG_ 2432638335 SclFctr_PedObj3_Cval_MPC "MPC_C33_Pkt";
BA_ "FlexKomSigName" SG_ 2432638335 SclFctr_PedObj3_Cval_MPC "MPC_C33_Pkt";
BA_ "FlexKomSigLaenge" SG_ 2432638335 SclFctr_PedObj3_Cval_MPC 64;
BA_ "FlexKomSigStartPos" SG_ 2432638335 SclFctr_PedObj3_Cval_MPC 7;
BA_ "FlexKomSID" SG_ 2432638335 SclFctr_PedObj3_Cval_MPC 100680311;
BA_ "GenSigStartValue" SG_ 2432638335 SclFctr_PedObj3_Cval_MPC 65535;
BA_ "FlexKomSigStartValue" SG_ 2432638335 SclFctr_PedObj3_Cval_MPC "D9F0FFFFFFFFFFFFh";
BA_ "GenSigCycleTime" SG_ 2432638335 SclFctr_PedObj3_Cval_MPC 50;
BA_ "GenSigSNA" SG_ 2432638591 CRC_SG_MPC_C34_Pkt "38h";
BA_ "FlexKomIsMotorola" SG_ 2432638591 CRC_SG_MPC_C34_Pkt 1;
BA_ "FlexKomComment" SG_ 2432638591 CRC_SG_MPC_C34_Pkt "MPC_C34_Pkt";
BA_ "FlexKomSigName" SG_ 2432638591 CRC_SG_MPC_C34_Pkt "MPC_C34_Pkt";
BA_ "FlexKomSigLaenge" SG_ 2432638591 CRC_SG_MPC_C34_Pkt 64;
BA_ "FlexKomSigStartPos" SG_ 2432638591 CRC_SG_MPC_C34_Pkt 7;
BA_ "FlexKomSID" SG_ 2432638591 CRC_SG_MPC_C34_Pkt 100680312;
BA_ "GenSigStartValue" SG_ 2432638591 CRC_SG_MPC_C34_Pkt 56;
BA_ "FlexKomSigStartValue" SG_ 2432638591 CRC_SG_MPC_C34_Pkt "38F0FFFFFFFFFFFFh";
BA_ "GenSigCycleTime" SG_ 2432638591 CRC_SG_MPC_C34_Pkt 50;
BA_ "GenSigSNA" SG_ 2432638591 SQC_SG_MPC_C34_Pkt "0h";
BA_ "FlexKomIsMotorola" SG_ 2432638591 SQC_SG_MPC_C34_Pkt 1;
BA_ "FlexKomComment" SG_ 2432638591 SQC_SG_MPC_C34_Pkt "MPC_C34_Pkt";
BA_ "FlexKomSigName" SG_ 2432638591 SQC_SG_MPC_C34_Pkt "MPC_C34_Pkt";
BA_ "FlexKomSigLaenge" SG_ 2432638591 SQC_SG_MPC_C34_Pkt 64;
BA_ "FlexKomSigStartPos" SG_ 2432638591 SQC_SG_MPC_C34_Pkt 7;
BA_ "FlexKomSID" SG_ 2432638591 SQC_SG_MPC_C34_Pkt 100680312;
BA_ "FlexKomSigStartValue" SG_ 2432638591 SQC_SG_MPC_C34_Pkt "38F0FFFFFFFFFFFFh";
BA_ "GenSigCycleTime" SG_ 2432638591 SQC_SG_MPC_C34_Pkt 50;
BA_ "GenSigSNA" SG_ 2432638591 AnglLt_PedObj4_Cval_MPC "FFFFh";
BA_ "FlexKomIsMotorola" SG_ 2432638591 AnglLt_PedObj4_Cval_MPC 1;
BA_ "FlexKomComment" SG_ 2432638591 AnglLt_PedObj4_Cval_MPC "MPC_C34_Pkt";
BA_ "FlexKomSigName" SG_ 2432638591 AnglLt_PedObj4_Cval_MPC "MPC_C34_Pkt";
BA_ "FlexKomSigLaenge" SG_ 2432638591 AnglLt_PedObj4_Cval_MPC 64;
BA_ "FlexKomSigStartPos" SG_ 2432638591 AnglLt_PedObj4_Cval_MPC 7;
BA_ "FlexKomSID" SG_ 2432638591 AnglLt_PedObj4_Cval_MPC 100680312;
BA_ "GenSigStartValue" SG_ 2432638591 AnglLt_PedObj4_Cval_MPC 65535;
BA_ "FlexKomSigStartValue" SG_ 2432638591 AnglLt_PedObj4_Cval_MPC "38F0FFFFFFFFFFFFh";
BA_ "GenSigCycleTime" SG_ 2432638591 AnglLt_PedObj4_Cval_MPC 50;
BA_ "GenSigSNA" SG_ 2432638591 AnglRt_PedObj4_Cval_MPC "FFFFh";
BA_ "FlexKomIsMotorola" SG_ 2432638591 AnglRt_PedObj4_Cval_MPC 1;
BA_ "FlexKomComment" SG_ 2432638591 AnglRt_PedObj4_Cval_MPC "MPC_C34_Pkt";
BA_ "FlexKomSigName" SG_ 2432638591 AnglRt_PedObj4_Cval_MPC "MPC_C34_Pkt";
BA_ "FlexKomSigLaenge" SG_ 2432638591 AnglRt_PedObj4_Cval_MPC 64;
BA_ "FlexKomSigStartPos" SG_ 2432638591 AnglRt_PedObj4_Cval_MPC 7;
BA_ "FlexKomSID" SG_ 2432638591 AnglRt_PedObj4_Cval_MPC 100680312;
BA_ "GenSigStartValue" SG_ 2432638591 AnglRt_PedObj4_Cval_MPC 65535;
BA_ "FlexKomSigStartValue" SG_ 2432638591 AnglRt_PedObj4_Cval_MPC "38F0FFFFFFFFFFFFh";
BA_ "GenSigCycleTime" SG_ 2432638591 AnglRt_PedObj4_Cval_MPC 50;
BA_ "GenSigSNA" SG_ 2432638591 SclFctr_PedObj4_Cval_MPC "FFFFh";
BA_ "FlexKomIsMotorola" SG_ 2432638591 SclFctr_PedObj4_Cval_MPC 1;
BA_ "FlexKomComment" SG_ 2432638591 SclFctr_PedObj4_Cval_MPC "MPC_C34_Pkt";
BA_ "FlexKomSigName" SG_ 2432638591 SclFctr_PedObj4_Cval_MPC "MPC_C34_Pkt";
BA_ "FlexKomSigLaenge" SG_ 2432638591 SclFctr_PedObj4_Cval_MPC 64;
BA_ "FlexKomSigStartPos" SG_ 2432638591 SclFctr_PedObj4_Cval_MPC 7;
BA_ "FlexKomSID" SG_ 2432638591 SclFctr_PedObj4_Cval_MPC 100680312;
BA_ "GenSigStartValue" SG_ 2432638591 SclFctr_PedObj4_Cval_MPC 65535;
BA_ "FlexKomSigStartValue" SG_ 2432638591 SclFctr_PedObj4_Cval_MPC "38F0FFFFFFFFFFFFh";
BA_ "GenSigCycleTime" SG_ 2432638591 SclFctr_PedObj4_Cval_MPC 50;
BA_ "GenSigSNA" SG_ 2432638847 CRC_SG_MPC_C35_Pkt "7Eh";
BA_ "FlexKomIsMotorola" SG_ 2432638847 CRC_SG_MPC_C35_Pkt 1;
BA_ "FlexKomComment" SG_ 2432638847 CRC_SG_MPC_C35_Pkt "MPC_C35_Pkt";
BA_ "FlexKomSigName" SG_ 2432638847 CRC_SG_MPC_C35_Pkt "MPC_C35_Pkt";
BA_ "FlexKomSigLaenge" SG_ 2432638847 CRC_SG_MPC_C35_Pkt 64;
BA_ "FlexKomSigStartPos" SG_ 2432638847 CRC_SG_MPC_C35_Pkt 7;
BA_ "FlexKomSID" SG_ 2432638847 CRC_SG_MPC_C35_Pkt 100680314;
BA_ "GenSigStartValue" SG_ 2432638847 CRC_SG_MPC_C35_Pkt 126;
BA_ "FlexKomSigStartValue" SG_ 2432638847 CRC_SG_MPC_C35_Pkt "7EF0FFFFFFFFFFFFh";
BA_ "GenSigCycleTime" SG_ 2432638847 CRC_SG_MPC_C35_Pkt 50;
BA_ "GenSigSNA" SG_ 2432638847 SQC_SG_MPC_C35_Pkt "0h";
BA_ "FlexKomIsMotorola" SG_ 2432638847 SQC_SG_MPC_C35_Pkt 1;
BA_ "FlexKomComment" SG_ 2432638847 SQC_SG_MPC_C35_Pkt "MPC_C35_Pkt";
BA_ "FlexKomSigName" SG_ 2432638847 SQC_SG_MPC_C35_Pkt "MPC_C35_Pkt";
BA_ "FlexKomSigLaenge" SG_ 2432638847 SQC_SG_MPC_C35_Pkt 64;
BA_ "FlexKomSigStartPos" SG_ 2432638847 SQC_SG_MPC_C35_Pkt 7;
BA_ "FlexKomSID" SG_ 2432638847 SQC_SG_MPC_C35_Pkt 100680314;
BA_ "FlexKomSigStartValue" SG_ 2432638847 SQC_SG_MPC_C35_Pkt "7EF0FFFFFFFFFFFFh";
BA_ "GenSigCycleTime" SG_ 2432638847 SQC_SG_MPC_C35_Pkt 50;
BA_ "GenSigSNA" SG_ 2432638847 AnglLt_PedObj5_Cval_MPC "FFFFh";
BA_ "FlexKomIsMotorola" SG_ 2432638847 AnglLt_PedObj5_Cval_MPC 1;
BA_ "FlexKomComment" SG_ 2432638847 AnglLt_PedObj5_Cval_MPC "MPC_C35_Pkt";
BA_ "FlexKomSigName" SG_ 2432638847 AnglLt_PedObj5_Cval_MPC "MPC_C35_Pkt";
BA_ "FlexKomSigLaenge" SG_ 2432638847 AnglLt_PedObj5_Cval_MPC 64;
BA_ "FlexKomSigStartPos" SG_ 2432638847 AnglLt_PedObj5_Cval_MPC 7;
BA_ "FlexKomSID" SG_ 2432638847 AnglLt_PedObj5_Cval_MPC 100680314;
BA_ "GenSigStartValue" SG_ 2432638847 AnglLt_PedObj5_Cval_MPC 65535;
BA_ "FlexKomSigStartValue" SG_ 2432638847 AnglLt_PedObj5_Cval_MPC "7EF0FFFFFFFFFFFFh";
BA_ "GenSigCycleTime" SG_ 2432638847 AnglLt_PedObj5_Cval_MPC 50;
BA_ "GenSigSNA" SG_ 2432638847 AnglRt_PedObj5_Cval_MPC "FFFFh";
BA_ "FlexKomIsMotorola" SG_ 2432638847 AnglRt_PedObj5_Cval_MPC 1;
BA_ "FlexKomComment" SG_ 2432638847 AnglRt_PedObj5_Cval_MPC "MPC_C35_Pkt";
BA_ "FlexKomSigName" SG_ 2432638847 AnglRt_PedObj5_Cval_MPC "MPC_C35_Pkt";
BA_ "FlexKomSigLaenge" SG_ 2432638847 AnglRt_PedObj5_Cval_MPC 64;
BA_ "FlexKomSigStartPos" SG_ 2432638847 AnglRt_PedObj5_Cval_MPC 7;
BA_ "FlexKomSID" SG_ 2432638847 AnglRt_PedObj5_Cval_MPC 100680314;
BA_ "GenSigStartValue" SG_ 2432638847 AnglRt_PedObj5_Cval_MPC 65535;
BA_ "FlexKomSigStartValue" SG_ 2432638847 AnglRt_PedObj5_Cval_MPC "7EF0FFFFFFFFFFFFh";
BA_ "GenSigCycleTime" SG_ 2432638847 AnglRt_PedObj5_Cval_MPC 50;
BA_ "GenSigSNA" SG_ 2432638847 SclFctr_PedObj5_Cval_MPC "FFFFh";
BA_ "FlexKomIsMotorola" SG_ 2432638847 SclFctr_PedObj5_Cval_MPC 1;
BA_ "FlexKomComment" SG_ 2432638847 SclFctr_PedObj5_Cval_MPC "MPC_C35_Pkt";
BA_ "FlexKomSigName" SG_ 2432638847 SclFctr_PedObj5_Cval_MPC "MPC_C35_Pkt";
BA_ "FlexKomSigLaenge" SG_ 2432638847 SclFctr_PedObj5_Cval_MPC 64;
BA_ "FlexKomSigStartPos" SG_ 2432638847 SclFctr_PedObj5_Cval_MPC 7;
BA_ "FlexKomSID" SG_ 2432638847 SclFctr_PedObj5_Cval_MPC 100680314;
BA_ "GenSigStartValue" SG_ 2432638847 SclFctr_PedObj5_Cval_MPC 65535;
BA_ "FlexKomSigStartValue" SG_ 2432638847 SclFctr_PedObj5_Cval_MPC "7EF0FFFFFFFFFFFFh";
BA_ "GenSigCycleTime" SG_ 2432638847 SclFctr_PedObj5_Cval_MPC 50;
BA_ "GenSigSNA" SG_ 2432639103 CRC_SG_MPC_C36_Pkt "3Ah";
BA_ "FlexKomIsMotorola" SG_ 2432639103 CRC_SG_MPC_C36_Pkt 1;
BA_ "FlexKomComment" SG_ 2432639103 CRC_SG_MPC_C36_Pkt "MPC_C36_Pkt";
BA_ "FlexKomSigName" SG_ 2432639103 CRC_SG_MPC_C36_Pkt "MPC_C36_Pkt";
BA_ "FlexKomSigLaenge" SG_ 2432639103 CRC_SG_MPC_C36_Pkt 64;
BA_ "FlexKomSigStartPos" SG_ 2432639103 CRC_SG_MPC_C36_Pkt 7;
BA_ "FlexKomSID" SG_ 2432639103 CRC_SG_MPC_C36_Pkt 100680318;
BA_ "GenSigStartValue" SG_ 2432639103 CRC_SG_MPC_C36_Pkt 58;
BA_ "FlexKomSigStartValue" SG_ 2432639103 CRC_SG_MPC_C36_Pkt "3AF0FFFFFFFFFFFFh";
BA_ "GenSigCycleTime" SG_ 2432639103 CRC_SG_MPC_C36_Pkt 50;
BA_ "GenSigSNA" SG_ 2432639103 SQC_SG_MPC_C36_Pkt "0h";
BA_ "FlexKomIsMotorola" SG_ 2432639103 SQC_SG_MPC_C36_Pkt 1;
BA_ "FlexKomComment" SG_ 2432639103 SQC_SG_MPC_C36_Pkt "MPC_C36_Pkt";
BA_ "FlexKomSigName" SG_ 2432639103 SQC_SG_MPC_C36_Pkt "MPC_C36_Pkt";
BA_ "FlexKomSigLaenge" SG_ 2432639103 SQC_SG_MPC_C36_Pkt 64;
BA_ "FlexKomSigStartPos" SG_ 2432639103 SQC_SG_MPC_C36_Pkt 7;
BA_ "FlexKomSID" SG_ 2432639103 SQC_SG_MPC_C36_Pkt 100680318;
BA_ "FlexKomSigStartValue" SG_ 2432639103 SQC_SG_MPC_C36_Pkt "3AF0FFFFFFFFFFFFh";
BA_ "GenSigCycleTime" SG_ 2432639103 SQC_SG_MPC_C36_Pkt 50;
BA_ "GenSigSNA" SG_ 2432639103 AnglLt_VehObj0_Cval_MPC "FFFFh";
BA_ "FlexKomIsMotorola" SG_ 2432639103 AnglLt_VehObj0_Cval_MPC 1;
BA_ "FlexKomComment" SG_ 2432639103 AnglLt_VehObj0_Cval_MPC "MPC_C36_Pkt";
BA_ "FlexKomSigName" SG_ 2432639103 AnglLt_VehObj0_Cval_MPC "MPC_C36_Pkt";
BA_ "FlexKomSigLaenge" SG_ 2432639103 AnglLt_VehObj0_Cval_MPC 64;
BA_ "FlexKomSigStartPos" SG_ 2432639103 AnglLt_VehObj0_Cval_MPC 7;
BA_ "FlexKomSID" SG_ 2432639103 AnglLt_VehObj0_Cval_MPC 100680318;
BA_ "GenSigStartValue" SG_ 2432639103 AnglLt_VehObj0_Cval_MPC 65535;
BA_ "FlexKomSigStartValue" SG_ 2432639103 AnglLt_VehObj0_Cval_MPC "3AF0FFFFFFFFFFFFh";
BA_ "GenSigCycleTime" SG_ 2432639103 AnglLt_VehObj0_Cval_MPC 50;
BA_ "GenSigSNA" SG_ 2432639103 AnglRt_VehObj0_Cval_MPC "FFFFh";
BA_ "FlexKomIsMotorola" SG_ 2432639103 AnglRt_VehObj0_Cval_MPC 1;
BA_ "FlexKomComment" SG_ 2432639103 AnglRt_VehObj0_Cval_MPC "MPC_C36_Pkt";
BA_ "FlexKomSigName" SG_ 2432639103 AnglRt_VehObj0_Cval_MPC "MPC_C36_Pkt";
BA_ "FlexKomSigLaenge" SG_ 2432639103 AnglRt_VehObj0_Cval_MPC 64;
BA_ "FlexKomSigStartPos" SG_ 2432639103 AnglRt_VehObj0_Cval_MPC 7;
BA_ "FlexKomSID" SG_ 2432639103 AnglRt_VehObj0_Cval_MPC 100680318;
BA_ "GenSigStartValue" SG_ 2432639103 AnglRt_VehObj0_Cval_MPC 65535;
BA_ "FlexKomSigStartValue" SG_ 2432639103 AnglRt_VehObj0_Cval_MPC "3AF0FFFFFFFFFFFFh";
BA_ "GenSigCycleTime" SG_ 2432639103 AnglRt_VehObj0_Cval_MPC 50;
BA_ "GenSigSNA" SG_ 2432639103 SclFctr_VehObj0_Cval_MPC "FFFFh";
BA_ "FlexKomIsMotorola" SG_ 2432639103 SclFctr_VehObj0_Cval_MPC 1;
BA_ "FlexKomComment" SG_ 2432639103 SclFctr_VehObj0_Cval_MPC "MPC_C36_Pkt";
BA_ "FlexKomSigName" SG_ 2432639103 SclFctr_VehObj0_Cval_MPC "MPC_C36_Pkt";
BA_ "FlexKomSigLaenge" SG_ 2432639103 SclFctr_VehObj0_Cval_MPC 64;
BA_ "FlexKomSigStartPos" SG_ 2432639103 SclFctr_VehObj0_Cval_MPC 7;
BA_ "FlexKomSID" SG_ 2432639103 SclFctr_VehObj0_Cval_MPC 100680318;
BA_ "GenSigStartValue" SG_ 2432639103 SclFctr_VehObj0_Cval_MPC 65535;
BA_ "FlexKomSigStartValue" SG_ 2432639103 SclFctr_VehObj0_Cval_MPC "3AF0FFFFFFFFFFFFh";
BA_ "GenSigCycleTime" SG_ 2432639103 SclFctr_VehObj0_Cval_MPC 50;
BA_ "GenSigSNA" SG_ 2432639359 CRC_SG_MPC_C37_Pkt "69h";
BA_ "FlexKomIsMotorola" SG_ 2432639359 CRC_SG_MPC_C37_Pkt 1;
BA_ "FlexKomComment" SG_ 2432639359 CRC_SG_MPC_C37_Pkt "MPC_C37_Pkt";
BA_ "FlexKomSigName" SG_ 2432639359 CRC_SG_MPC_C37_Pkt "MPC_C37_Pkt";
BA_ "FlexKomSigLaenge" SG_ 2432639359 CRC_SG_MPC_C37_Pkt 64;
BA_ "FlexKomSigStartPos" SG_ 2432639359 CRC_SG_MPC_C37_Pkt 7;
BA_ "FlexKomSID" SG_ 2432639359 CRC_SG_MPC_C37_Pkt 100680319;
BA_ "GenSigStartValue" SG_ 2432639359 CRC_SG_MPC_C37_Pkt 105;
BA_ "FlexKomSigStartValue" SG_ 2432639359 CRC_SG_MPC_C37_Pkt "69F0FFFFFFFFFFFFh";
BA_ "GenSigCycleTime" SG_ 2432639359 CRC_SG_MPC_C37_Pkt 50;
BA_ "GenSigSNA" SG_ 2432639359 SQC_SG_MPC_C37_Pkt "0h";
BA_ "FlexKomIsMotorola" SG_ 2432639359 SQC_SG_MPC_C37_Pkt 1;
BA_ "FlexKomComment" SG_ 2432639359 SQC_SG_MPC_C37_Pkt "MPC_C37_Pkt";
BA_ "FlexKomSigName" SG_ 2432639359 SQC_SG_MPC_C37_Pkt "MPC_C37_Pkt";
BA_ "FlexKomSigLaenge" SG_ 2432639359 SQC_SG_MPC_C37_Pkt 64;
BA_ "FlexKomSigStartPos" SG_ 2432639359 SQC_SG_MPC_C37_Pkt 7;
BA_ "FlexKomSID" SG_ 2432639359 SQC_SG_MPC_C37_Pkt 100680319;
BA_ "FlexKomSigStartValue" SG_ 2432639359 SQC_SG_MPC_C37_Pkt "69F0FFFFFFFFFFFFh";
BA_ "GenSigCycleTime" SG_ 2432639359 SQC_SG_MPC_C37_Pkt 50;
BA_ "GenSigSNA" SG_ 2432639359 AnglLt_VehObj1_Cval_MPC "FFFFh";
BA_ "FlexKomIsMotorola" SG_ 2432639359 AnglLt_VehObj1_Cval_MPC 1;
BA_ "FlexKomComment" SG_ 2432639359 AnglLt_VehObj1_Cval_MPC "MPC_C37_Pkt";
BA_ "FlexKomSigName" SG_ 2432639359 AnglLt_VehObj1_Cval_MPC "MPC_C37_Pkt";
BA_ "FlexKomSigLaenge" SG_ 2432639359 AnglLt_VehObj1_Cval_MPC 64;
BA_ "FlexKomSigStartPos" SG_ 2432639359 AnglLt_VehObj1_Cval_MPC 7;
BA_ "FlexKomSID" SG_ 2432639359 AnglLt_VehObj1_Cval_MPC 100680319;
BA_ "GenSigStartValue" SG_ 2432639359 AnglLt_VehObj1_Cval_MPC 65535;
BA_ "FlexKomSigStartValue" SG_ 2432639359 AnglLt_VehObj1_Cval_MPC "69F0FFFFFFFFFFFFh";
BA_ "GenSigCycleTime" SG_ 2432639359 AnglLt_VehObj1_Cval_MPC 50;
BA_ "GenSigSNA" SG_ 2432639359 AnglRt_VehObj1_Cval_MPC "FFFFh";
BA_ "FlexKomIsMotorola" SG_ 2432639359 AnglRt_VehObj1_Cval_MPC 1;
BA_ "FlexKomComment" SG_ 2432639359 AnglRt_VehObj1_Cval_MPC "MPC_C37_Pkt";
BA_ "FlexKomSigName" SG_ 2432639359 AnglRt_VehObj1_Cval_MPC "MPC_C37_Pkt";
BA_ "FlexKomSigLaenge" SG_ 2432639359 AnglRt_VehObj1_Cval_MPC 64;
BA_ "FlexKomSigStartPos" SG_ 2432639359 AnglRt_VehObj1_Cval_MPC 7;
BA_ "FlexKomSID" SG_ 2432639359 AnglRt_VehObj1_Cval_MPC 100680319;
BA_ "GenSigStartValue" SG_ 2432639359 AnglRt_VehObj1_Cval_MPC 65535;
BA_ "FlexKomSigStartValue" SG_ 2432639359 AnglRt_VehObj1_Cval_MPC "69F0FFFFFFFFFFFFh";
BA_ "GenSigCycleTime" SG_ 2432639359 AnglRt_VehObj1_Cval_MPC 50;
BA_ "GenSigSNA" SG_ 2432639359 SclFctr_VehObj1_Cval_MPC "FFFFh";
BA_ "FlexKomIsMotorola" SG_ 2432639359 SclFctr_VehObj1_Cval_MPC 1;
BA_ "FlexKomComment" SG_ 2432639359 SclFctr_VehObj1_Cval_MPC "MPC_C37_Pkt";
BA_ "FlexKomSigName" SG_ 2432639359 SclFctr_VehObj1_Cval_MPC "MPC_C37_Pkt";
BA_ "FlexKomSigLaenge" SG_ 2432639359 SclFctr_VehObj1_Cval_MPC 64;
BA_ "FlexKomSigStartPos" SG_ 2432639359 SclFctr_VehObj1_Cval_MPC 7;
BA_ "FlexKomSID" SG_ 2432639359 SclFctr_VehObj1_Cval_MPC 100680319;
BA_ "GenSigStartValue" SG_ 2432639359 SclFctr_VehObj1_Cval_MPC 65535;
BA_ "FlexKomSigStartValue" SG_ 2432639359 SclFctr_VehObj1_Cval_MPC "69F0FFFFFFFFFFFFh";
BA_ "GenSigCycleTime" SG_ 2432639359 SclFctr_VehObj1_Cval_MPC 50;
VAL_ 2432634239 ClassPedObj3_Stat_MPC 15 "SNA" 14 "ERR" 6 "OTHER" 5 "PED_GROUP" 4 "PEDESTRIAN" 3 "BICYCLE" 2 "MOT_CYC" 1 "PAS_CAR" 0 "TRUCK" ;
VAL_ 2432634239 NumPedObj3_Cval_MPC 31 "SNA" ;
VAL_ 2432634239 TypePedObj3_Stat_MPC 7 "SNA" 6 "init" 5 "oncom" 4 "cross" 3 "stati" 2 "Mov_Stop" 1 "Mov" 0 "not_detec" ;
VAL_ 2432634239 StdRng_X_PedObj3_Cval_MPC 3 "SNA" 2 "BELW_2M" 1 "BELW_1M" 0 "BELW_0_5M" ;
VAL_ 2432634239 StdRng_Y_PedObj3_Cval_MPC 3 "SNA" 2 "BELW_1M" 1 "BELW_0_5M" 0 "BELW_0_25M" ;
VAL_ 2432634239 StdRng_Spd_X_PedObj3_Cval_MPC 3 "SNA" 2 "BELW_2M_PER_S" 1 "BELW_1M_PER_S" 0 "BELW_0_5M_PER_S" ;
VAL_ 2432634239 StdRng_Spd_Y_PedObj3_Cval_MPC 3 "SNA" 2 "BELW_1_2M_PER_S" 1 "BELW_0_6M_PER_S" 0 "BELW_0_3M_PER_S" ;
VAL_ 2432634239 WidthPedObj3_Cval_MPC 255 "SNA" 254 "ERR" ;
VAL_ 2432634239 OLA_PedObj3_Cval_MPC 255 "SNA" 254 "ERR" ;
VAL_ 2432634239 HeightPedObj3_Cval_MPC 255 "SNA" 254 "ERR" ;
VAL_ 2432634239 LaneAlloc_PedObj3_Cval_MPC 7 "SNA" 3 "OBJ_RT" 2 "OBJ_CNT" 1 "OBJ_LT" 0 "NO_ALLOC" ;
VAL_ 2432634239 TurnSgl_PedObj3_Cval_MPC 7 "SNA" 3 "HAZARD" 2 "RIGHT" 1 "LEFT" 0 "NO" ;
VAL_ 2432634239 LaneChgInd_PedObj3_Stat_MPC 3 "SNA" 2 "CUT_OUT" 1 "CUT_IN" 0 "NO" ;
VAL_ 2432634495 ClassPedObj4_Stat_MPC 15 "SNA" 14 "ERR" 6 "OTHER" 5 "PED_GROUP" 4 "PEDESTRIAN" 3 "BICYCLE" 2 "MOT_CYC" 1 "PAS_CAR" 0 "TRUCK" ;
VAL_ 2432634495 NumPedObj4_Cval_MPC 31 "SNA" ;
VAL_ 2432634495 TypePedObj4_Stat_MPC 7 "SNA" 6 "init" 5 "oncom" 4 "cross" 3 "stati" 2 "Mov_Stop" 1 "Mov" 0 "not_detec" ;
VAL_ 2432634495 StdRng_X_PedObj4_Cval_MPC 3 "SNA" 2 "BELW_2M" 1 "BELW_1M" 0 "BELW_0_5M" ;
VAL_ 2432634495 StdRng_Y_PedObj4_Cval_MPC 3 "SNA" 2 "BELW_1M" 1 "BELW_0_5M" 0 "BELW_0_25M" ;
VAL_ 2432634495 StdRng_Spd_X_PedObj4_Cval_MPC 3 "SNA" 2 "BELW_2M_PER_S" 1 "BELW_1M_PER_S" 0 "BELW_0_5M_PER_S" ;
VAL_ 2432634495 StdRng_Spd_Y_PedObj4_Cval_MPC 3 "SNA" 2 "BELW_1_2M_PER_S" 1 "BELW_0_6M_PER_S" 0 "BELW_0_3M_PER_S" ;
VAL_ 2432634495 WidthPedObj4_Cval_MPC 255 "SNA" 254 "ERR" ;
VAL_ 2432634495 OLA_PedObj4_Cval_MPC 255 "SNA" 254 "ERR" ;
VAL_ 2432634495 HeightPedObj4_Cval_MPC 255 "SNA" 254 "ERR" ;
VAL_ 2432634495 LaneAlloc_PedObj4_Cval_MPC 7 "SNA" 3 "OBJ_RT" 2 "OBJ_CNT" 1 "OBJ_LT" 0 "NO_ALLOC" ;
VAL_ 2432634495 TurnSgl_PedObj4_Cval_MPC 7 "SNA" 3 "HAZARD" 2 "RIGHT" 1 "LEFT" 0 "NO" ;
VAL_ 2432634495 LaneChgInd_PedObj4_Stat_MPC 3 "SNA" 2 "CUT_OUT" 1 "CUT_IN" 0 "NO" ;
VAL_ 2432634751 ClassPedObj5_Stat_MPC 15 "SNA" 14 "ERR" 6 "OTHER" 5 "PED_GROUP" 4 "PEDESTRIAN" 3 "BICYCLE" 2 "MOT_CYC" 1 "PAS_CAR" 0 "TRUCK" ;
VAL_ 2432634751 NumPedObj5_Cval_MPC 31 "SNA" ;
VAL_ 2432634751 TypePedObj5_Stat_MPC 7 "SNA" 6 "init" 5 "oncom" 4 "cross" 3 "stati" 2 "Mov_Stop" 1 "Mov" 0 "not_detec" ;
VAL_ 2432634751 StdRng_X_PedObj5_Cval_MPC 3 "SNA" 2 "BELW_2M" 1 "BELW_1M" 0 "BELW_0_5M" ;
VAL_ 2432634751 StdRng_Y_PedObj5_Cval_MPC 3 "SNA" 2 "BELW_1M" 1 "BELW_0_5M" 0 "BELW_0_25M" ;
VAL_ 2432634751 StdRng_Spd_X_PedObj5_Cval_MPC 3 "SNA" 2 "BELW_2M_PER_S" 1 "BELW_1M_PER_S" 0 "BELW_0_5M_PER_S" ;
VAL_ 2432634751 StdRng_Spd_Y_PedObj5_Cval_MPC 3 "SNA" 2 "BELW_1_2M_PER_S" 1 "BELW_0_6M_PER_S" 0 "BELW_0_3M_PER_S" ;
VAL_ 2432634751 WidthPedObj5_Cval_MPC 255 "SNA" 254 "ERR" ;
VAL_ 2432634751 OLA_PedObj5_Cval_MPC 255 "SNA" 254 "ERR" ;
VAL_ 2432634751 HeightPedObj5_Cval_MPC 255 "SNA" 254 "ERR" ;
VAL_ 2432634751 LaneAlloc_PedObj5_Cval_MPC 7 "SNA" 3 "OBJ_RT" 2 "OBJ_CNT" 1 "OBJ_LT" 0 "NO_ALLOC" ;
VAL_ 2432634751 TurnSgl_PedObj5_Cval_MPC 7 "SNA" 3 "HAZARD" 2 "RIGHT" 1 "LEFT" 0 "NO" ;
VAL_ 2432634751 LaneChgInd_PedObj5_Stat_MPC 3 "SNA" 2 "CUT_OUT" 1 "CUT_IN" 0 "NO" ;
VAL_ 2432635007 ConfLvl_VehObj0_Cval 3 "SNA" 2 "CONFLVL2" 1 "CONFLVL1" 0 "NOCONF" ;
VAL_ 2432635007 DtctStat_VehObj0_MPC 3 "SNA" 2 "ERR" 1 "OBSRVD" 0 "NOBSRVD" ;
VAL_ 2432635007 Spd_X_VehObj0_Cval 255 "SNA" 254 "ERR" ;
VAL_ 2432635007 Spd_Y_VehObj0_Cval 255 "SNA" ;
VAL_ 2432635007 Dist_X_VehObj0_Cval_MPC 65535 "SNA" ;
VAL_ 2432635007 Dist_Y_VehObj0_Cval_MPC 65535 "SNA" ;
VAL_ 2432635263 ConfLvl_VehObj1_Cval 3 "SNA" 2 "CONFLVL2" 1 "CONFLVL1" 0 "NOCONF" ;
VAL_ 2432635263 DtctStat_VehObj1_MPC 3 "SNA" 2 "ERR" 1 "OBSRVD" 0 "NOBSRVD" ;
VAL_ 2432635263 Spd_X_VehObj1_Cval 255 "SNA" 254 "ERR" ;
VAL_ 2432635263 Spd_Y_VehObj1_Cval 255 "SNA" ;
VAL_ 2432635263 Dist_X_VehObj1_Cval_MPC 65535 "SNA" ;
VAL_ 2432635263 Dist_Y_VehObj1_Cval_MPC 65535 "SNA" ;
VAL_ 2432635519 ConfLvl_VehObj2_Cval 3 "SNA" 2 "CONFLVL2" 1 "CONFLVL1" 0 "NOCONF" ;
VAL_ 2432635519 DtctStat_VehObj2_MPC 3 "SNA" 2 "ERR" 1 "OBSRVD" 0 "NOBSRVD" ;
VAL_ 2432635519 Spd_X_VehObj2_Cval 255 "SNA" 254 "ERR" ;
VAL_ 2432635519 Spd_Y_VehObj2_Cval 255 "SNA" ;
VAL_ 2432635519 Dist_X_VehObj2_Cval_MPC 65535 "SNA" ;
VAL_ 2432635519 Dist_Y_VehObj2_Cval_MPC 65535 "SNA" ;
VAL_ 2432635775 ConfLvl_VehObj3_Cval 3 "SNA" 2 "CONFLVL2" 1 "CONFLVL1" 0 "NOCONF" ;
VAL_ 2432635775 DtctStat_VehObj3_MPC 3 "SNA" 2 "ERR" 1 "OBSRVD" 0 "NOBSRVD" ;
VAL_ 2432635775 Spd_X_VehObj3_Cval 255 "SNA" 254 "ERR" ;
VAL_ 2432635775 Spd_Y_VehObj3_Cval 255 "SNA" ;
VAL_ 2432635775 Dist_X_VehObj3_Cval_MPC 65535 "SNA" ;
VAL_ 2432635775 Dist_Y_VehObj3_Cval_MPC 65535 "SNA" ;
VAL_ 2432636031 ClassVehObj0_Stat_MPC 15 "SNA" 14 "ERR" 6 "OTHER" 5 "PED_GROUP" 4 "PEDESTRIAN" 3 "BICYCLE" 2 "MOT_CYC" 1 "PAS_CAR" 0 "TRUCK" ;
VAL_ 2432636031 NumVehObj0_Cval_MPC 31 "SNA" ;
VAL_ 2432636031 TypeVehObj0_Stat_MPC 7 "SNA" 6 "init" 5 "oncom" 4 "cross" 3 "stati" 2 "Mov_Stop" 1 "Mov" 0 "not_detec" ;
VAL_ 2432636031 StdRng_X_VehObj0_Cval_MPC 3 "SNA" 2 "BELW_2M" 1 "BELW_1M" 0 "BELW_0_5M" ;
VAL_ 2432636031 StdRng_Y_VehObj0_Cval_MPC 3 "SNA" 2 "BELW_1M" 1 "BELW_0_5M" 0 "BELW_0_25M" ;
VAL_ 2432636031 StdRng_Spd_X_VehObj0_Cval_MPC 3 "SNA" 2 "BELW_2M_PER_S" 1 "BELW_1M_PER_S" 0 "BELW_0_5M_PER_S" ;
VAL_ 2432636031 StdRng_Spd_Y_VehObj0_Cval_MPC 3 "SNA" 2 "BELW_1_2M_PER_S" 1 "BELW_0_6M_PER_S" 0 "BELW_0_3M_PER_S" ;
VAL_ 2432636031 WidthVehObj0_Cval_MPC 255 "SNA" 254 "ERR" ;
VAL_ 2432636031 OLA_VehObj0_Cval_MPC 255 "SNA" 254 "ERR" ;
VAL_ 2432636031 HeightVehObj0_Cval_MPC 255 "SNA" 254 "ERR" ;
VAL_ 2432636031 LaneAlloc_VehObj0_Cval_MPC 7 "SNA" 3 "OBJ_RT" 2 "OBJ_CNT" 1 "OBJ_LT" 0 "NO_ALLOC" ;
VAL_ 2432636031 TurnSgl_VehObj0_Cval_MPC 7 "SNA" 3 "HAZARD" 2 "RIGHT" 1 "LEFT" 0 "NO" ;
VAL_ 2432636031 LaneChgInd_VehObj0_Stat_MPC 3 "SNA" 2 "CUT_OUT" 1 "CUT_IN" 0 "NO" ;
VAL_ 2432636287 ClassVehObj1_Stat_MPC 15 "SNA" 14 "ERR" 6 "OTHER" 5 "PED_GROUP" 4 "PEDESTRIAN" 3 "BICYCLE" 2 "MOT_CYC" 1 "PAS_CAR" 0 "TRUCK" ;
VAL_ 2432636287 NumVehObj1_Cval_MPC 31 "SNA" ;
VAL_ 2432636287 TypeVehObj1_Stat_MPC 7 "SNA" 6 "init" 5 "oncom" 4 "cross" 3 "stati" 2 "Mov_Stop" 1 "Mov" 0 "not_detec" ;
VAL_ 2432636287 StdRng_X_VehObj1_Cval_MPC 3 "SNA" 2 "BELW_2M" 1 "BELW_1M" 0 "BELW_0_5M" ;
VAL_ 2432636287 StdRng_Y_VehObj1_Cval_MPC 3 "SNA" 2 "BELW_1M" 1 "BELW_0_5M" 0 "BELW_0_25M" ;
VAL_ 2432636287 StdRng_Spd_X_VehObj1_Cval_MPC 3 "SNA" 2 "BELW_2M_PER_S" 1 "BELW_1M_PER_S" 0 "BELW_0_5M_PER_S" ;
VAL_ 2432636287 StdRng_Spd_Y_VehObj1_Cval_MPC 3 "SNA" 2 "BELW_1_2M_PER_S" 1 "BELW_0_6M_PER_S" 0 "BELW_0_3M_PER_S" ;
VAL_ 2432636287 WidthVehObj1_Cval_MPC 255 "SNA" 254 "ERR" ;
VAL_ 2432636287 OLA_VehObj1_Cval_MPC 255 "SNA" 254 "ERR" ;
VAL_ 2432636287 HeightVehObj1_Cval_MPC 255 "SNA" 254 "ERR" ;
VAL_ 2432636287 LaneAlloc_VehObj1_Cval_MPC 7 "SNA" 3 "OBJ_RT" 2 "OBJ_CNT" 1 "OBJ_LT" 0 "NO_ALLOC" ;
VAL_ 2432636287 TurnSgl_VehObj1_Cval_MPC 7 "SNA" 3 "HAZARD" 2 "RIGHT" 1 "LEFT" 0 "NO" ;
VAL_ 2432636287 LaneChgInd_VehObj1_Stat_MPC 3 "SNA" 2 "CUT_OUT" 1 "CUT_IN" 0 "NO" ;
VAL_ 2432636543 ClassVehObj2_Stat_MPC 15 "SNA" 14 "ERR" 6 "OTHER" 5 "PED_GROUP" 4 "PEDESTRIAN" 3 "BICYCLE" 2 "MOT_CYC" 1 "PAS_CAR" 0 "TRUCK" ;
VAL_ 2432636543 NumVehObj2_Cval_MPC 31 "SNA" ;
VAL_ 2432636543 TypeVehObj2_Stat_MPC 7 "SNA" 6 "init" 5 "oncom" 4 "cross" 3 "stati" 2 "Mov_Stop" 1 "Mov" 0 "not_detec" ;
VAL_ 2432636543 StdRng_X_VehObj2_Cval_MPC 3 "SNA" 2 "BELW_2M" 1 "BELW_1M" 0 "BELW_0_5M" ;
VAL_ 2432636543 StdRng_Y_VehObj2_Cval_MPC 3 "SNA" 2 "BELW_1M" 1 "BELW_0_5M" 0 "BELW_0_25M" ;
VAL_ 2432636543 StdRng_Spd_X_VehObj2_Cval_MPC 3 "SNA" 2 "BELW_2M_PER_S" 1 "BELW_1M_PER_S" 0 "BELW_0_5M_PER_S" ;
VAL_ 2432636543 StdRng_Spd_Y_VehObj2_Cval_MPC 3 "SNA" 2 "BELW_1_2M_PER_S" 1 "BELW_0_6M_PER_S" 0 "BELW_0_3M_PER_S" ;
VAL_ 2432636543 WidthVehObj2_Cval_MPC 255 "SNA" 254 "ERR" ;
VAL_ 2432636543 OLA_VehObj2_Cval_MPC 255 "SNA" 254 "ERR" ;
VAL_ 2432636543 HeightVehObj2_Cval_MPC 255 "SNA" 254 "ERR" ;
VAL_ 2432636543 LaneAlloc_VehObj2_Cval_MPC 7 "SNA" 3 "OBJ_RT" 2 "OBJ_CNT" 1 "OBJ_LT" 0 "NO_ALLOC" ;
VAL_ 2432636543 TurnSgl_VehObj2_Cval_MPC 7 "SNA" 3 "HAZARD" 2 "RIGHT" 1 "LEFT" 0 "NO" ;
VAL_ 2432636543 LaneChgInd_VehObj2_Stat_MPC 3 "SNA" 2 "CUT_OUT" 1 "CUT_IN" 0 "NO" ;
VAL_ 2432636799 ClassVehObj3_Stat_MPC 15 "SNA" 14 "ERR" 6 "OTHER" 5 "PED_GROUP" 4 "PEDESTRIAN" 3 "BICYCLE" 2 "MOT_CYC" 1 "PAS_CAR" 0 "TRUCK" ;
VAL_ 2432636799 NumVehObj3_Cval_MPC 31 "SNA" ;
VAL_ 2432636799 TypeVehObj03_Stat_MPC 7 "SNA" 6 "init" 5 "oncom" 4 "cross" 3 "stati" 2 "Mov_Stop" 1 "Mov" 0 "not_detec" ;
VAL_ 2432636799 StdRng_X_VehObj3_Cval_MPC 3 "SNA" 2 "BELW_2M" 1 "BELW_1M" 0 "BELW_0_5M" ;
VAL_ 2432636799 StdRng_Y_VehObj3_Cval_MPC 3 "SNA" 2 "BELW_1M" 1 "BELW_0_5M" 0 "BELW_0_25M" ;
VAL_ 2432636799 StdRng_Spd_X_VehObj3_Cval_MPC 3 "SNA" 2 "BELW_2M_PER_S" 1 "BELW_1M_PER_S" 0 "BELW_0_5M_PER_S" ;
VAL_ 2432636799 StdRng_Spd_Y_VehObj3_Cval_MPC 3 "SNA" 2 "BELW_1_2M_PER_S" 1 "BELW_0_6M_PER_S" 0 "BELW_0_3M_PER_S" ;
VAL_ 2432636799 WidthVehObj3_Cval_MPC 255 "SNA" 254 "ERR" ;
VAL_ 2432636799 OLA_VehObj3_Cval_MPC 255 "SNA" 254 "ERR" ;
VAL_ 2432636799 HeightVehObj3_Cval_MPC 255 "SNA" 254 "ERR" ;
VAL_ 2432636799 LaneAlloc_VehObj3_Cval_MPC 7 "SNA" 3 "OBJ_RT" 2 "OBJ_CNT" 1 "OBJ_LT" 0 "NO_ALLOC" ;
VAL_ 2432636799 TurnSgl_VehObj3_Cval_MPC 7 "SNA" 3 "HAZARD" 2 "RIGHT" 1 "LEFT" 0 "NO" ;
VAL_ 2432636799 LaneChgInd_VehObj3_Stat_MPC 3 "SNA" 2 "CUT_OUT" 1 "CUT_IN" 0 "NO" ;
VAL_ 2432637311 IHC_Tnl1_State_MPC 3 "SNA" 2 "DIMMED" 1 "ACTIVE" 0 "OFF" ;
VAL_ 2432637311 IHC_Tnl1_ChgOvrLvl_MPC 7 "SNA" ;
VAL_ 2432637311 BotDotRec_Stat 7 "SNA" 3 "BOTH_SD" 2 "RT_SD" 1 "LT_SD" 0 "OFF" ;
VAL_ 2432637311 IHC_Tnl1_AngLmtLt_MPC 255 "SNA" 254 "ERR" ;
VAL_ 2432637311 IHC_Tnl1_AngLmtRt_MPC 255 "SNA" 254 "ERR" ;
VAL_ 2432637311 IHC_Tnl1_ActLgtDist_MPC 255 "SNA" 254 "ERR" ;
VAL_ 2432637311 IHC_Tnl2_State_MPC 3 "SNA" 2 "DIMMED" 1 "ACTIVE" 0 "OFF" ;
VAL_ 2432637311 IHC_Tnl2_ChgOvrLvl_MPC 7 "SNA" ;
VAL_ 2432637311 WarnPoleRec_Stat 7 "SNA" 3 "BOTH_SD" 2 "RT_SD" 1 "LT_SD" 0 "OFF" ;
VAL_ 2432637311 IHC_Tnl2_AngLmtLt_MPC 255 "SNA" 254 "ERR" ;
VAL_ 2432637311 IHC_Tnl2_AngLmtRt_MPC 255 "SNA" 254 "ERR" ;
VAL_ 2432637311 IHC_Tnl2_ActLgtDist_MPC 255 "SNA" 254 "ERR" ;
VAL_ 2432637567 AnglLt_PedObj0_Cval_MPC 65535 "SNA" ;
VAL_ 2432637567 AnglRt_PedObj0_Cval_MPC 65535 "SNA" ;
VAL_ 2432637567 SclFctr_PedObj0_Cval_MPC 65535 "SNA" ;
VAL_ 2432637823 AnglLt_PedObj1_Cval_MPC 65535 "SNA" ;
VAL_ 2432637823 AnglRt_PedObj1_Cval_MPC 65535 "SNA" ;
VAL_ 2432637823 SclFctr_PedObj1_Cval_MPC 65535 "SNA" ;
VAL_ 2432638079 AnglLt_PedObj2_Cval_MPC 65535 "SNA" ;
VAL_ 2432638079 AnglRt_PedObj2_Cval_MPC 65535 "SNA" ;
VAL_ 2432638079 SclFctr_PedObj2_Cval_MPC 65535 "SNA" ;
VAL_ 2432638335 AnglLt_PedObj3_Cval_MPC 65535 "SNA" ;
VAL_ 2432638335 AnglRt_PedObj3_Cval_MPC 65535 "SNA" ;
VAL_ 2432638335 SclFctr_PedObj3_Cval_MPC 65535 "SNA" ;
VAL_ 2432638591 AnglLt_PedObj4_Cval_MPC 65535 "SNA" ;
VAL_ 2432638591 AnglRt_PedObj4_Cval_MPC 65535 "SNA" ;
VAL_ 2432638591 SclFctr_PedObj4_Cval_MPC 65535 "SNA" ;
VAL_ 2432638847 AnglLt_PedObj5_Cval_MPC 65535 "SNA" ;
VAL_ 2432638847 AnglRt_PedObj5_Cval_MPC 65535 "SNA" ;
VAL_ 2432638847 SclFctr_PedObj5_Cval_MPC 65535 "SNA" ;
VAL_ 2432639103 AnglLt_VehObj0_Cval_MPC 65535 "SNA" ;
VAL_ 2432639103 AnglRt_VehObj0_Cval_MPC 65535 "SNA" ;
VAL_ 2432639103 SclFctr_VehObj0_Cval_MPC 65535 "SNA" ;
VAL_ 2432639359 AnglLt_VehObj1_Cval_MPC 65535 "SNA" ;
VAL_ 2432639359 AnglRt_VehObj1_Cval_MPC 65535 "SNA" ;
VAL_ 2432639359 SclFctr_VehObj1_Cval_MPC 65535 "SNA" ;
